VERSION ""

NS_ :

BS_:

BU_:  Inverter  Battery  Charger  Host

BO_ 2626813958 BATT_diagnosticHrnsImpDleta_0_6: 8 Battery
 SG_ BATT_HrnsImpDelta_3_6 : 48|16@1- (0.001,0) [-32.768|32.767] "mV" Host
 SG_ BATT_HrnsImpDelta_2_6 : 32|16@1- (0.001,0) [-32.768|32.767] "mV" Host
 SG_ BATT_HrnsImpDelta_1_6 : 16|16@1- (0.001,0) [-32.768|32.767] "mV" Host
 SG_ BATT_HrnsImpDelta_0_6 : 0|16@1- (0.001,0) [-32.768|32.767] "mV" Host

BO_ 2626813959 BATT_diagnosticHrnsImpDleta_0_7: 8 Battery
 SG_ BATT_HrnsImpDelta_3_7 : 48|16@1- (0.001,0) [-32.768|32.767] "mV" Host
 SG_ BATT_HrnsImpDelta_2_7 : 32|16@1- (0.001,0) [-32.768|32.767] "mV" Host
 SG_ BATT_HrnsImpDelta_1_7 : 16|16@1- (0.001,0) [-32.768|32.767] "mV" Host
 SG_ BATT_HrnsImpDelta_0_7 : 0|16@1- (0.001,0) [-32.768|32.767] "mV" Host

BO_ 2626813960 BATT_diagnosticHrnsImpDleta_0_8: 8 Battery
 SG_ BATT_HrnsImpDelta_3_8 : 48|16@1- (0.001,0) [-32.768|32.767] "mV" Host
 SG_ BATT_HrnsImpDelta_2_8 : 32|16@1- (0.001,0) [-32.768|32.767] "mV" Host
 SG_ BATT_HrnsImpDelta_1_8 : 16|16@1- (0.001,0) [-32.768|32.767] "mV" Host
 SG_ BATT_HrnsImpDelta_0_8 : 0|16@1- (0.001,0) [-32.768|32.767] "mV" Host

BO_ 2626813961 BATT_diagnosticHrnsImpDleta_0_9: 8 Battery
 SG_ BATT_HrnsImpDelta_3_9 : 48|16@1- (0.001,0) [-32.768|32.767] "mV" Host
 SG_ BATT_HrnsImpDelta_2_9 : 32|16@1- (0.001,0) [-32.768|32.767] "mV" Host
 SG_ BATT_HrnsImpDelta_1_9 : 16|16@1- (0.001,0) [-32.768|32.767] "mV" Host
 SG_ BATT_HrnsImpDelta_0_9 : 0|16@1- (0.001,0) [-32.768|32.767] "mV" Host

BO_ 2626813962 BATT_diagnosticHrnsImpDleta_0_10: 8 Battery
 SG_ BATT_HrnsImpDelta_3_10 : 48|16@1- (0.001,0) [-32.768|32.767] "mV" Host
 SG_ BATT_HrnsImpDelta_2_10 : 32|16@1- (0.001,0) [-32.768|32.767] "mV" Host
 SG_ BATT_HrnsImpDelta_1_10 : 16|16@1- (0.001,0) [-32.768|32.767] "mV" Host
 SG_ BATT_HrnsImpDelta_0_10 : 0|16@1- (0.001,0) [-32.768|32.767] "mV" Host

BO_ 2626813963 BATT_diagnosticHrnsImpDleta_0_11: 8 Battery
 SG_ BATT_HrnsImpDelta_3_11 : 48|16@1- (0.001,0) [-32.768|32.767] "mV" Host
 SG_ BATT_HrnsImpDelta_2_11 : 32|16@1- (0.001,0) [-32.768|32.767] "mV" Host
 SG_ BATT_HrnsImpDelta_1_11 : 16|16@1- (0.001,0) [-32.768|32.767] "mV" Host
 SG_ BATT_HrnsImpDelta_0_11 : 0|16@1- (0.001,0) [-32.768|32.767] "mV" Host

BO_ 2626818048 BATT_diagnosticHrnsImpDleta_1_0: 8 Battery
 SG_ BATT_HrnsImpDelta_7_0 : 48|16@1- (0.001,0) [-32.768|32.767] "mV" Host
 SG_ BATT_HrnsImpDelta_6_0 : 32|16@1- (0.001,0) [-32.768|32.767] "mV" Host
 SG_ BATT_HrnsImpDelta_5_0 : 16|16@1- (0.001,0) [-32.768|32.767] "mV" Host
 SG_ BATT_HrnsImpDelta_4_0 : 0|16@1- (0.001,0) [-32.768|32.767] "mV" Host

BO_ 2626818049 BATT_diagnosticHrnsImpDleta_1_1: 8 Battery
 SG_ BATT_HrnsImpDelta_7_1 : 48|16@1- (0.001,0) [-32.768|32.767] "mV" Host
 SG_ BATT_HrnsImpDelta_6_1 : 32|16@1- (0.001,0) [-32.768|32.767] "mV" Host
 SG_ BATT_HrnsImpDelta_5_1 : 16|16@1- (0.001,0) [-32.768|32.767] "mV" Host
 SG_ BATT_HrnsImpDelta_4_1 : 0|16@1- (0.001,0) [-32.768|32.767] "mV" Host

BO_ 2626818050 BATT_diagnosticHrnsImpDleta_1_2: 8 Battery
 SG_ BATT_HrnsImpDelta_7_2 : 48|16@1- (0.001,0) [-32.768|32.767] "mV" Host
 SG_ BATT_HrnsImpDelta_6_2 : 32|16@1- (0.001,0) [-32.768|32.767] "mV" Host
 SG_ BATT_HrnsImpDelta_5_2 : 16|16@1- (0.001,0) [-32.768|32.767] "mV" Host
 SG_ BATT_HrnsImpDelta_4_2 : 0|16@1- (0.001,0) [-32.768|32.767] "mV" Host

BO_ 2626818051 BATT_diagnosticHrnsImpDleta_1_3: 8 Battery
 SG_ BATT_HrnsImpDelta_7_3 : 48|16@1- (0.001,0) [-32.768|32.767] "mV" Host
 SG_ BATT_HrnsImpDelta_6_3 : 32|16@1- (0.001,0) [-32.768|32.767] "mV" Host
 SG_ BATT_HrnsImpDelta_5_3 : 16|16@1- (0.001,0) [-32.768|32.767] "mV" Host
 SG_ BATT_HrnsImpDelta_4_3 : 0|16@1- (0.001,0) [-32.768|32.767] "mV" Host

BO_ 2626818052 BATT_diagnosticHrnsImpDleta_1_4: 8 Battery
 SG_ BATT_HrnsImpDelta_7_4 : 48|16@1- (0.001,0) [-32.768|32.767] "mV" Host
 SG_ BATT_HrnsImpDelta_6_4 : 32|16@1- (0.001,0) [-32.768|32.767] "mV" Host
 SG_ BATT_HrnsImpDelta_5_4 : 16|16@1- (0.001,0) [-32.768|32.767] "mV" Host
 SG_ BATT_HrnsImpDelta_4_4 : 0|16@1- (0.001,0) [-32.768|32.767] "mV" Host

BO_ 2626818053 BATT_diagnosticHrnsImpDleta_1_5: 8 Battery
 SG_ BATT_HrnsImpDelta_7_5 : 48|16@1- (0.001,0) [-32.768|32.767] "mV" Host
 SG_ BATT_HrnsImpDelta_6_5 : 32|16@1- (0.001,0) [-32.768|32.767] "mV" Host
 SG_ BATT_HrnsImpDelta_5_5 : 16|16@1- (0.001,0) [-32.768|32.767] "mV" Host
 SG_ BATT_HrnsImpDelta_4_5 : 0|16@1- (0.001,0) [-32.768|32.767] "mV" Host

BO_ 2626818054 BATT_diagnosticHrnsImpDleta_1_6: 8 Battery
 SG_ BATT_HrnsImpDelta_7_6 : 48|16@1- (0.001,0) [-32.768|32.767] "mV" Host
 SG_ BATT_HrnsImpDelta_6_6 : 32|16@1- (0.001,0) [-32.768|32.767] "mV" Host
 SG_ BATT_HrnsImpDelta_5_6 : 16|16@1- (0.001,0) [-32.768|32.767] "mV" Host
 SG_ BATT_HrnsImpDelta_4_6 : 0|16@1- (0.001,0) [-32.768|32.767] "mV" Host

BO_ 2626818055 BATT_diagnosticHrnsImpDleta_1_7: 8 Battery
 SG_ BATT_HrnsImpDelta_7_7 : 48|16@1- (0.001,0) [-32.768|32.767] "mV" Host
 SG_ BATT_HrnsImpDelta_6_7 : 32|16@1- (0.001,0) [-32.768|32.767] "mV" Host
 SG_ BATT_HrnsImpDelta_5_7 : 16|16@1- (0.001,0) [-32.768|32.767] "mV" Host
 SG_ BATT_HrnsImpDelta_4_7 : 0|16@1- (0.001,0) [-32.768|32.767] "mV" Host

BO_ 2626818056 BATT_diagnosticHrnsImpDleta_1_8: 8 Battery
 SG_ BATT_HrnsImpDelta_7_8 : 48|16@1- (0.001,0) [-32.768|32.767] "mV" Host
 SG_ BATT_HrnsImpDelta_6_8 : 32|16@1- (0.001,0) [-32.768|32.767] "mV" Host
 SG_ BATT_HrnsImpDelta_5_8 : 16|16@1- (0.001,0) [-32.768|32.767] "mV" Host
 SG_ BATT_HrnsImpDelta_4_8 : 0|16@1- (0.001,0) [-32.768|32.767] "mV" Host

BO_ 2626818057 BATT_diagnosticHrnsImpDleta_1_9: 8 Battery
 SG_ BATT_HrnsImpDelta_7_9 : 48|16@1- (0.001,0) [-32.768|32.767] "mV" Host
 SG_ BATT_HrnsImpDelta_6_9 : 32|16@1- (0.001,0) [-32.768|32.767] "mV" Host
 SG_ BATT_HrnsImpDelta_5_9 : 16|16@1- (0.001,0) [-32.768|32.767] "mV" Host
 SG_ BATT_HrnsImpDelta_4_9 : 0|16@1- (0.001,0) [-32.768|32.767] "mV" Host

BO_ 2626818058 BATT_diagnosticHrnsImpDleta_1_10: 8 Battery
 SG_ BATT_HrnsImpDelta_7_10 : 48|16@1- (0.001,0) [-32.768|32.767] "mV" Host
 SG_ BATT_HrnsImpDelta_6_10 : 32|16@1- (0.001,0) [-32.768|32.767] "mV" Host
 SG_ BATT_HrnsImpDelta_5_10 : 16|16@1- (0.001,0) [-32.768|32.767] "mV" Host
 SG_ BATT_HrnsImpDelta_4_10 : 0|16@1- (0.001,0) [-32.768|32.767] "mV" Host

BO_ 2626818059 BATT_diagnosticHrnsImpDleta_1_11: 8 Battery
 SG_ BATT_HrnsImpDelta_7_11 : 48|16@1- (0.001,0) [-32.768|32.767] "mV" Host
 SG_ BATT_HrnsImpDelta_6_11 : 32|16@1- (0.001,0) [-32.768|32.767] "mV" Host
 SG_ BATT_HrnsImpDelta_5_11 : 16|16@1- (0.001,0) [-32.768|32.767] "mV" Host
 SG_ BATT_HrnsImpDelta_4_11 : 0|16@1- (0.001,0) [-32.768|32.767] "mV" Host

BO_ 2626822144 BATT_diagnosticHrnsImpDleta_2_0: 8 Battery
 SG_ BATT_HrnsImpDelta_11_0 : 48|16@1- (0.001,0) [-32.768|32.767] "mV" Host
 SG_ BATT_HrnsImpDelta_10_0 : 32|16@1- (0.001,0) [-32.768|32.767] "mV" Host
 SG_ BATT_HrnsImpDelta_9_0 : 16|16@1- (0.001,0) [-32.768|32.767] "mV" Host
 SG_ BATT_HrnsImpDelta_8_0 : 0|16@1- (0.001,0) [-32.768|32.767] "mV" Host

BO_ 2626822145 BATT_diagnosticHrnsImpDleta_2_1: 8 Battery
 SG_ BATT_HrnsImpDelta_11_1 : 48|16@1- (0.001,0) [-32.768|32.767] "mV" Host
 SG_ BATT_HrnsImpDelta_10_1 : 32|16@1- (0.001,0) [-32.768|32.767] "mV" Host
 SG_ BATT_HrnsImpDelta_9_1 : 16|16@1- (0.001,0) [-32.768|32.767] "mV" Host
 SG_ BATT_HrnsImpDelta_8_1 : 0|16@1- (0.001,0) [-32.768|32.767] "mV" Host

BO_ 2626822146 BATT_diagnosticHrnsImpDleta_2_2: 8 Battery
 SG_ BATT_HrnsImpDelta_11_2 : 48|16@1- (0.001,0) [-32.768|32.767] "mV" Host
 SG_ BATT_HrnsImpDelta_10_2 : 32|16@1- (0.001,0) [-32.768|32.767] "mV" Host
 SG_ BATT_HrnsImpDelta_9_2 : 16|16@1- (0.001,0) [-32.768|32.767] "mV" Host
 SG_ BATT_HrnsImpDelta_8_2 : 0|16@1- (0.001,0) [-32.768|32.767] "mV" Host

BO_ 2626822147 BATT_diagnosticHrnsImpDleta_2_3: 8 Battery
 SG_ BATT_HrnsImpDelta_11_3 : 48|16@1- (0.001,0) [-32.768|32.767] "mV" Host
 SG_ BATT_HrnsImpDelta_10_3 : 32|16@1- (0.001,0) [-32.768|32.767] "mV" Host
 SG_ BATT_HrnsImpDelta_9_3 : 16|16@1- (0.001,0) [-32.768|32.767] "mV" Host
 SG_ BATT_HrnsImpDelta_8_3 : 0|16@1- (0.001,0) [-32.768|32.767] "mV" Host

BO_ 2626822148 BATT_diagnosticHrnsImpDleta_2_4: 8 Battery
 SG_ BATT_HrnsImpDelta_11_4 : 48|16@1- (0.001,0) [-32.768|32.767] "mV" Host
 SG_ BATT_HrnsImpDelta_10_4 : 32|16@1- (0.001,0) [-32.768|32.767] "mV" Host
 SG_ BATT_HrnsImpDelta_9_4 : 16|16@1- (0.001,0) [-32.768|32.767] "mV" Host
 SG_ BATT_HrnsImpDelta_8_4 : 0|16@1- (0.001,0) [-32.768|32.767] "mV" Host

BO_ 2626822149 BATT_diagnosticHrnsImpDleta_2_5: 8 Battery
 SG_ BATT_HrnsImpDelta_11_5 : 48|16@1- (0.001,0) [-32.768|32.767] "mV" Host
 SG_ BATT_HrnsImpDelta_10_5 : 32|16@1- (0.001,0) [-32.768|32.767] "mV" Host
 SG_ BATT_HrnsImpDelta_9_5 : 16|16@1- (0.001,0) [-32.768|32.767] "mV" Host
 SG_ BATT_HrnsImpDelta_8_5 : 0|16@1- (0.001,0) [-32.768|32.767] "mV" Host

BO_ 2626822150 BATT_diagnosticHrnsImpDleta_2_6: 8 Battery
 SG_ BATT_HrnsImpDelta_11_6 : 48|16@1- (0.001,0) [-32.768|32.767] "mV" Host
 SG_ BATT_HrnsImpDelta_10_6 : 32|16@1- (0.001,0) [-32.768|32.767] "mV" Host
 SG_ BATT_HrnsImpDelta_9_6 : 16|16@1- (0.001,0) [-32.768|32.767] "mV" Host
 SG_ BATT_HrnsImpDelta_8_6 : 0|16@1- (0.001,0) [-32.768|32.767] "mV" Host

BO_ 2626822151 BATT_diagnosticHrnsImpDleta_2_7: 8 Battery
 SG_ BATT_HrnsImpDelta_11_7 : 48|16@1- (0.001,0) [-32.768|32.767] "mV" Host
 SG_ BATT_HrnsImpDelta_10_7 : 32|16@1- (0.001,0) [-32.768|32.767] "mV" Host
 SG_ BATT_HrnsImpDelta_9_7 : 16|16@1- (0.001,0) [-32.768|32.767] "mV" Host
 SG_ BATT_HrnsImpDelta_8_7 : 0|16@1- (0.001,0) [-32.768|32.767] "mV" Host

BO_ 2626822152 BATT_diagnosticHrnsImpDleta_2_8: 8 Battery
 SG_ BATT_HrnsImpDelta_11_8 : 48|16@1- (0.001,0) [-32.768|32.767] "mV" Host
 SG_ BATT_HrnsImpDelta_10_8 : 32|16@1- (0.001,0) [-32.768|32.767] "mV" Host
 SG_ BATT_HrnsImpDelta_9_8 : 16|16@1- (0.001,0) [-32.768|32.767] "mV" Host
 SG_ BATT_HrnsImpDelta_8_8 : 0|16@1- (0.001,0) [-32.768|32.767] "mV" Host

BO_ 2626822153 BATT_diagnosticHrnsImpDleta_2_9: 8 Battery
 SG_ BATT_HrnsImpDelta_11_9 : 48|16@1- (0.001,0) [-32.768|32.767] "mV" Host
 SG_ BATT_HrnsImpDelta_10_9 : 32|16@1- (0.001,0) [-32.768|32.767] "mV" Host
 SG_ BATT_HrnsImpDelta_9_9 : 16|16@1- (0.001,0) [-32.768|32.767] "mV" Host
 SG_ BATT_HrnsImpDelta_8_9 : 0|16@1- (0.001,0) [-32.768|32.767] "mV" Host

BO_ 2626822154 BATT_diagnosticHrnsImpDleta_2_10: 8 Battery
 SG_ BATT_HrnsImpDelta_11_10 : 48|16@1- (0.001,0) [-32.768|32.767] "mV" Host
 SG_ BATT_HrnsImpDelta_10_10 : 32|16@1- (0.001,0) [-32.768|32.767] "mV" Host
 SG_ BATT_HrnsImpDelta_9_10 : 16|16@1- (0.001,0) [-32.768|32.767] "mV" Host
 SG_ BATT_HrnsImpDelta_8_10 : 0|16@1- (0.001,0) [-32.768|32.767] "mV" Host

BO_ 2626822155 BATT_diagnosticHrnsImpDleta_2_11: 8 Battery
 SG_ BATT_HrnsImpDelta_11_11 : 48|16@1- (0.001,0) [-32.768|32.767] "mV" Host
 SG_ BATT_HrnsImpDelta_10_11 : 32|16@1- (0.001,0) [-32.768|32.767] "mV" Host
 SG_ BATT_HrnsImpDelta_9_11 : 16|16@1- (0.001,0) [-32.768|32.767] "mV" Host
 SG_ BATT_HrnsImpDelta_8_11 : 0|16@1- (0.001,0) [-32.768|32.767] "mV" Host

BO_ 2626826240 BATT_diagnosticHrnsImpDleta_3_0: 6 Battery
 SG_ BATT_HrnsImpDelta_14_0 : 32|16@1- (0.001,0) [-32.768|32.767] "mV" Host
 SG_ BATT_HrnsImpDelta_13_0 : 16|16@1- (0.001,0) [-32.768|32.767] "mV" Host
 SG_ BATT_HrnsImpDelta_12_0 : 0|16@1- (0.001,0) [-32.768|32.767] "mV" Host

BO_ 2626826241 BATT_diagnosticHrnsImpDleta_3_1: 6 Battery
 SG_ BATT_HrnsImpDelta_14_1 : 32|16@1- (0.001,0) [-32.768|32.767] "mV" Host
 SG_ BATT_HrnsImpDelta_13_1 : 16|16@1- (0.001,0) [-32.768|32.767] "mV" Host
 SG_ BATT_HrnsImpDelta_12_1 : 0|16@1- (0.001,0) [-32.768|32.767] "mV" Host

BO_ 2626826242 BATT_diagnosticHrnsImpDleta_3_2: 6 Battery
 SG_ BATT_HrnsImpDelta_14_2 : 32|16@1- (0.001,0) [-32.768|32.767] "mV" Host
 SG_ BATT_HrnsImpDelta_13_2 : 16|16@1- (0.001,0) [-32.768|32.767] "mV" Host
 SG_ BATT_HrnsImpDelta_12_2 : 0|16@1- (0.001,0) [-32.768|32.767] "mV" Host

BO_ 2626826243 BATT_diagnosticHrnsImpDleta_3_3: 6 Battery
 SG_ BATT_HrnsImpDelta_14_3 : 32|16@1- (0.001,0) [-32.768|32.767] "mV" Host
 SG_ BATT_HrnsImpDelta_13_3 : 16|16@1- (0.001,0) [-32.768|32.767] "mV" Host
 SG_ BATT_HrnsImpDelta_12_3 : 0|16@1- (0.001,0) [-32.768|32.767] "mV" Host

BO_ 2626826244 BATT_diagnosticHrnsImpDleta_3_4: 6 Battery
 SG_ BATT_HrnsImpDelta_14_4 : 32|16@1- (0.001,0) [-32.768|32.767] "mV" Host
 SG_ BATT_HrnsImpDelta_13_4 : 16|16@1- (0.001,0) [-32.768|32.767] "mV" Host
 SG_ BATT_HrnsImpDelta_12_4 : 0|16@1- (0.001,0) [-32.768|32.767] "mV" Host

BO_ 2626826245 BATT_diagnosticHrnsImpDleta_3_5: 6 Battery
 SG_ BATT_HrnsImpDelta_14_5 : 32|16@1- (0.001,0) [-32.768|32.767] "mV" Host
 SG_ BATT_HrnsImpDelta_13_5 : 16|16@1- (0.001,0) [-32.768|32.767] "mV" Host
 SG_ BATT_HrnsImpDelta_12_5 : 0|16@1- (0.001,0) [-32.768|32.767] "mV" Host

BO_ 2626826246 BATT_diagnosticHrnsImpDleta_3_6: 6 Battery
 SG_ BATT_HrnsImpDelta_14_6 : 32|16@1- (0.001,0) [-32.768|32.767] "mV" Host
 SG_ BATT_HrnsImpDelta_13_6 : 16|16@1- (0.001,0) [-32.768|32.767] "mV" Host
 SG_ BATT_HrnsImpDelta_12_6 : 0|16@1- (0.001,0) [-32.768|32.767] "mV" Host

BO_ 2626826247 BATT_diagnosticHrnsImpDleta_3_7: 6 Battery
 SG_ BATT_HrnsImpDelta_14_7 : 32|16@1- (0.001,0) [-32.768|32.767] "mV" Host
 SG_ BATT_HrnsImpDelta_13_7 : 16|16@1- (0.001,0) [-32.768|32.767] "mV" Host
 SG_ BATT_HrnsImpDelta_12_7 : 0|16@1- (0.001,0) [-32.768|32.767] "mV" Host

BO_ 2626826248 BATT_diagnosticHrnsImpDleta_3_8: 6 Battery
 SG_ BATT_HrnsImpDelta_14_8 : 32|16@1- (0.001,0) [-32.768|32.767] "mV" Host
 SG_ BATT_HrnsImpDelta_13_8 : 16|16@1- (0.001,0) [-32.768|32.767] "mV" Host
 SG_ BATT_HrnsImpDelta_12_8 : 0|16@1- (0.001,0) [-32.768|32.767] "mV" Host

BO_ 2626826249 BATT_diagnosticHrnsImpDleta_3_9: 6 Battery
 SG_ BATT_HrnsImpDelta_14_9 : 32|16@1- (0.001,0) [-32.768|32.767] "mV" Host
 SG_ BATT_HrnsImpDelta_13_9 : 16|16@1- (0.001,0) [-32.768|32.767] "mV" Host
 SG_ BATT_HrnsImpDelta_12_9 : 0|16@1- (0.001,0) [-32.768|32.767] "mV" Host

BO_ 2626826250 BATT_diagnosticHrnsImpDleta_3_10: 6 Battery
 SG_ BATT_HrnsImpDelta_14_10 : 32|16@1- (0.001,0) [-32.768|32.767] "mV" Host
 SG_ BATT_HrnsImpDelta_13_10 : 16|16@1- (0.001,0) [-32.768|32.767] "mV" Host
 SG_ BATT_HrnsImpDelta_12_10 : 0|16@1- (0.001,0) [-32.768|32.767] "mV" Host

BO_ 2626826251 BATT_diagnosticHrnsImpDleta_3_11: 6 Battery
 SG_ BATT_HrnsImpDelta_14_11 : 32|16@1- (0.001,0) [-32.768|32.767] "mV" Host
 SG_ BATT_HrnsImpDelta_13_11 : 16|16@1- (0.001,0) [-32.768|32.767] "mV" Host
 SG_ BATT_HrnsImpDelta_12_11 : 0|16@1- (0.001,0) [-32.768|32.767] "mV" Host

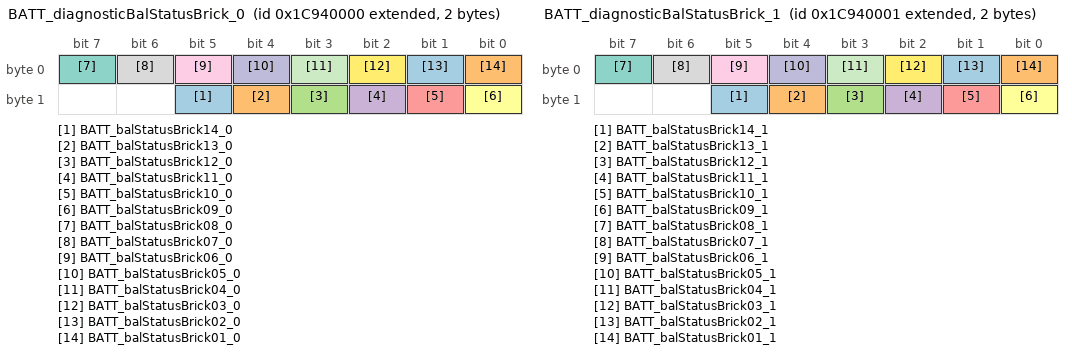
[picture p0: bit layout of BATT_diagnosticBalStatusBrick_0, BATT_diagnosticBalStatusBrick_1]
BO_ 2626945024 BATT_diagnosticBalStatusBrick_0: 2 Battery
 SG_ BATT_balStatusBrick14_0 : 13|1@1+ (1,0) [0|1] "" Host
 SG_ BATT_balStatusBrick13_0 : 12|1@1+ (1,0) [0|1] "" Host
 SG_ BATT_balStatusBrick12_0 : 11|1@1+ (1,0) [0|1] "" Host
 SG_ BATT_balStatusBrick11_0 : 10|1@1+ (1,0) [0|1] "" Host
 SG_ BATT_balStatusBrick10_0 : 9|1@1+ (1,0) [0|1] "" Host
 SG_ BATT_balStatusBrick09_0 : 8|1@1+ (1,0) [0|1] "" Host
 SG_ BATT_balStatusBrick08_0 : 7|1@1+ (1,0) [0|1] "" Host
 SG_ BATT_balStatusBrick07_0 : 6|1@1+ (1,0) [0|1] "" Host
 SG_ BATT_balStatusBrick06_0 : 5|1@1+ (1,0) [0|1] "" Host
 SG_ BATT_balStatusBrick05_0 : 4|1@1+ (1,0) [0|1] "" Host
 SG_ BATT_balStatusBrick04_0 : 3|1@1+ (1,0) [0|1] "" Host
 SG_ BATT_balStatusBrick03_0 : 2|1@1+ (1,0) [0|1] "" Host
 SG_ BATT_balStatusBrick02_0 : 1|1@1+ (1,0) [0|1] "" Host
 SG_ BATT_balStatusBrick01_0 : 0|1@1+ (1,0) [0|1] "" Host

BO_ 2626945025 BATT_diagnosticBalStatusBrick_1: 2 Battery
 SG_ BATT_balStatusBrick14_1 : 13|1@1+ (1,0) [0|1] "" Host
 SG_ BATT_balStatusBrick13_1 : 12|1@1+ (1,0) [0|1] "" Host
 SG_ BATT_balStatusBrick12_1 : 11|1@1+ (1,0) [0|1] "" Host
 SG_ BATT_balStatusBrick11_1 : 10|1@1+ (1,0) [0|1] "" Host
 SG_ BATT_balStatusBrick10_1 : 9|1@1+ (1,0) [0|1] "" Host
 SG_ BATT_balStatusBrick09_1 : 8|1@1+ (1,0) [0|1] "" Host
 SG_ BATT_balStatusBrick08_1 : 7|1@1+ (1,0) [0|1] "" Host
 SG_ BATT_balStatusBrick07_1 : 6|1@1+ (1,0) [0|1] "" Host
 SG_ BATT_balStatusBrick06_1 : 5|1@1+ (1,0) [0|1] "" Host
 SG_ BATT_balStatusBrick05_1 : 4|1@1+ (1,0) [0|1] "" Host
 SG_ BATT_balStatusBrick04_1 : 3|1@1+ (1,0) [0|1] "" Host
 SG_ BATT_balStatusBrick03_1 : 2|1@1+ (1,0) [0|1] "" Host
 SG_ BATT_balStatusBrick02_1 : 1|1@1+ (1,0) [0|1] "" Host
 SG_ BATT_balStatusBrick01_1 : 0|1@1+ (1,0) [0|1] "" Host

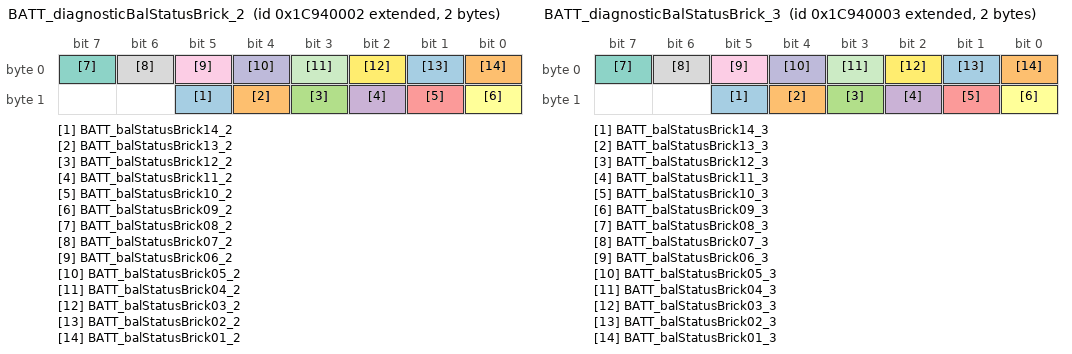
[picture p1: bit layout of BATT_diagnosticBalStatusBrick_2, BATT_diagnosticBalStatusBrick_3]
BO_ 2626945026 BATT_diagnosticBalStatusBrick_2: 2 Battery
 SG_ BATT_balStatusBrick14_2 : 13|1@1+ (1,0) [0|1] "" Host
 SG_ BATT_balStatusBrick13_2 : 12|1@1+ (1,0) [0|1] "" Host
 SG_ BATT_balStatusBrick12_2 : 11|1@1+ (1,0) [0|1] "" Host
 SG_ BATT_balStatusBrick11_2 : 10|1@1+ (1,0) [0|1] "" Host
 SG_ BATT_balStatusBrick10_2 : 9|1@1+ (1,0) [0|1] "" Host
 SG_ BATT_balStatusBrick09_2 : 8|1@1+ (1,0) [0|1] "" Host
 SG_ BATT_balStatusBrick08_2 : 7|1@1+ (1,0) [0|1] "" Host
 SG_ BATT_balStatusBrick07_2 : 6|1@1+ (1,0) [0|1] "" Host
 SG_ BATT_balStatusBrick06_2 : 5|1@1+ (1,0) [0|1] "" Host
 SG_ BATT_balStatusBrick05_2 : 4|1@1+ (1,0) [0|1] "" Host
 SG_ BATT_balStatusBrick04_2 : 3|1@1+ (1,0) [0|1] "" Host
 SG_ BATT_balStatusBrick03_2 : 2|1@1+ (1,0) [0|1] "" Host
 SG_ BATT_balStatusBrick02_2 : 1|1@1+ (1,0) [0|1] "" Host
 SG_ BATT_balStatusBrick01_2 : 0|1@1+ (1,0) [0|1] "" Host

BO_ 2626945027 BATT_diagnosticBalStatusBrick_3: 2 Battery
 SG_ BATT_balStatusBrick14_3 : 13|1@1+ (1,0) [0|1] "" Host
 SG_ BATT_balStatusBrick13_3 : 12|1@1+ (1,0) [0|1] "" Host
 SG_ BATT_balStatusBrick12_3 : 11|1@1+ (1,0) [0|1] "" Host
 SG_ BATT_balStatusBrick11_3 : 10|1@1+ (1,0) [0|1] "" Host
 SG_ BATT_balStatusBrick10_3 : 9|1@1+ (1,0) [0|1] "" Host
 SG_ BATT_balStatusBrick09_3 : 8|1@1+ (1,0) [0|1] "" Host
 SG_ BATT_balStatusBrick08_3 : 7|1@1+ (1,0) [0|1] "" Host
 SG_ BATT_balStatusBrick07_3 : 6|1@1+ (1,0) [0|1] "" Host
 SG_ BATT_balStatusBrick06_3 : 5|1@1+ (1,0) [0|1] "" Host
 SG_ BATT_balStatusBrick05_3 : 4|1@1+ (1,0) [0|1] "" Host
 SG_ BATT_balStatusBrick04_3 : 3|1@1+ (1,0) [0|1] "" Host
 SG_ BATT_balStatusBrick03_3 : 2|1@1+ (1,0) [0|1] "" Host
 SG_ BATT_balStatusBrick02_3 : 1|1@1+ (1,0) [0|1] "" Host
 SG_ BATT_balStatusBrick01_3 : 0|1@1+ (1,0) [0|1] "" Host

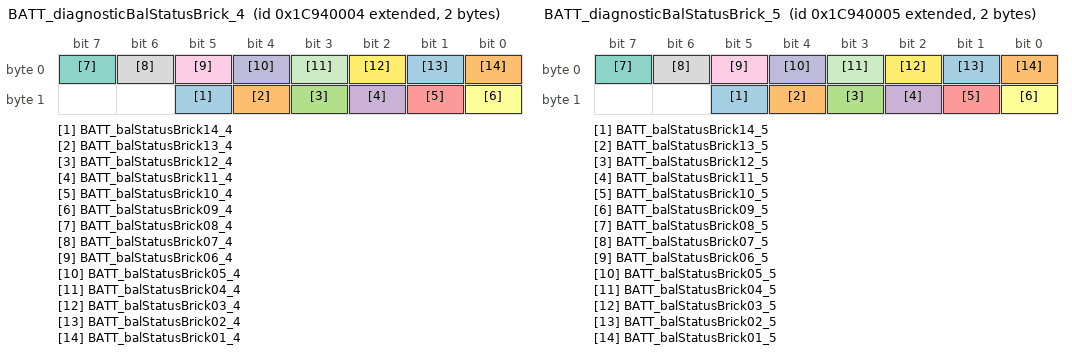
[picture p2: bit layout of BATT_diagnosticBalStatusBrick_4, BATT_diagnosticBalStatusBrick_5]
BO_ 2626945028 BATT_diagnosticBalStatusBrick_4: 2 Battery
 SG_ BATT_balStatusBrick14_4 : 13|1@1+ (1,0) [0|1] "" Host
 SG_ BATT_balStatusBrick13_4 : 12|1@1+ (1,0) [0|1] "" Host
 SG_ BATT_balStatusBrick12_4 : 11|1@1+ (1,0) [0|1] "" Host
 SG_ BATT_balStatusBrick11_4 : 10|1@1+ (1,0) [0|1] "" Host
 SG_ BATT_balStatusBrick10_4 : 9|1@1+ (1,0) [0|1] "" Host
 SG_ BATT_balStatusBrick09_4 : 8|1@1+ (1,0) [0|1] "" Host
 SG_ BATT_balStatusBrick08_4 : 7|1@1+ (1,0) [0|1] "" Host
 SG_ BATT_balStatusBrick07_4 : 6|1@1+ (1,0) [0|1] "" Host
 SG_ BATT_balStatusBrick06_4 : 5|1@1+ (1,0) [0|1] "" Host
 SG_ BATT_balStatusBrick05_4 : 4|1@1+ (1,0) [0|1] "" Host
 SG_ BATT_balStatusBrick04_4 : 3|1@1+ (1,0) [0|1] "" Host
 SG_ BATT_balStatusBrick03_4 : 2|1@1+ (1,0) [0|1] "" Host
 SG_ BATT_balStatusBrick02_4 : 1|1@1+ (1,0) [0|1] "" Host
 SG_ BATT_balStatusBrick01_4 : 0|1@1+ (1,0) [0|1] "" Host

BO_ 2626945029 BATT_diagnosticBalStatusBrick_5: 2 Battery
 SG_ BATT_balStatusBrick14_5 : 13|1@1+ (1,0) [0|1] "" Host
 SG_ BATT_balStatusBrick13_5 : 12|1@1+ (1,0) [0|1] "" Host
 SG_ BATT_balStatusBrick12_5 : 11|1@1+ (1,0) [0|1] "" Host
 SG_ BATT_balStatusBrick11_5 : 10|1@1+ (1,0) [0|1] "" Host
 SG_ BATT_balStatusBrick10_5 : 9|1@1+ (1,0) [0|1] "" Host
 SG_ BATT_balStatusBrick09_5 : 8|1@1+ (1,0) [0|1] "" Host
 SG_ BATT_balStatusBrick08_5 : 7|1@1+ (1,0) [0|1] "" Host
 SG_ BATT_balStatusBrick07_5 : 6|1@1+ (1,0) [0|1] "" Host
 SG_ BATT_balStatusBrick06_5 : 5|1@1+ (1,0) [0|1] "" Host
 SG_ BATT_balStatusBrick05_5 : 4|1@1+ (1,0) [0|1] "" Host
 SG_ BATT_balStatusBrick04_5 : 3|1@1+ (1,0) [0|1] "" Host
 SG_ BATT_balStatusBrick03_5 : 2|1@1+ (1,0) [0|1] "" Host
 SG_ BATT_balStatusBrick02_5 : 1|1@1+ (1,0) [0|1] "" Host
 SG_ BATT_balStatusBrick01_5 : 0|1@1+ (1,0) [0|1] "" Host

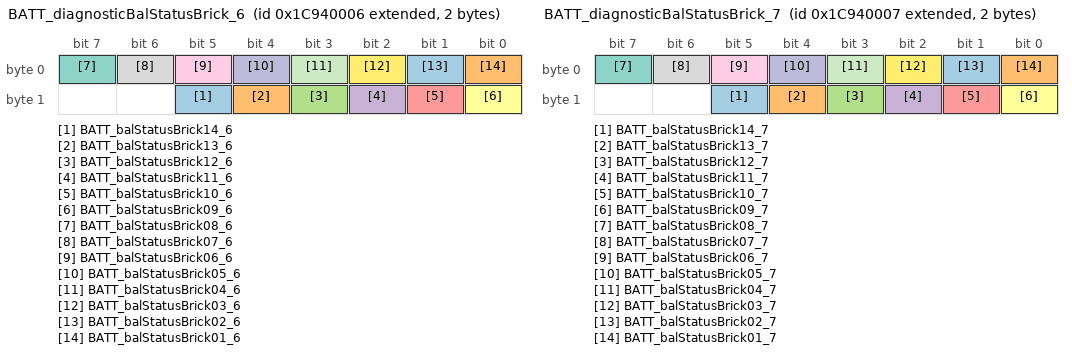
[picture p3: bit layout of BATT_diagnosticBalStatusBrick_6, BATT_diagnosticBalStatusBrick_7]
BO_ 2626945030 BATT_diagnosticBalStatusBrick_6: 2 Battery
 SG_ BATT_balStatusBrick14_6 : 13|1@1+ (1,0) [0|1] "" Host
 SG_ BATT_balStatusBrick13_6 : 12|1@1+ (1,0) [0|1] "" Host
 SG_ BATT_balStatusBrick12_6 : 11|1@1+ (1,0) [0|1] "" Host
 SG_ BATT_balStatusBrick11_6 : 10|1@1+ (1,0) [0|1] "" Host
 SG_ BATT_balStatusBrick10_6 : 9|1@1+ (1,0) [0|1] "" Host
 SG_ BATT_balStatusBrick09_6 : 8|1@1+ (1,0) [0|1] "" Host
 SG_ BATT_balStatusBrick08_6 : 7|1@1+ (1,0) [0|1] "" Host
 SG_ BATT_balStatusBrick07_6 : 6|1@1+ (1,0) [0|1] "" Host
 SG_ BATT_balStatusBrick06_6 : 5|1@1+ (1,0) [0|1] "" Host
 SG_ BATT_balStatusBrick05_6 : 4|1@1+ (1,0) [0|1] "" Host
 SG_ BATT_balStatusBrick04_6 : 3|1@1+ (1,0) [0|1] "" Host
 SG_ BATT_balStatusBrick03_6 : 2|1@1+ (1,0) [0|1] "" Host
 SG_ BATT_balStatusBrick02_6 : 1|1@1+ (1,0) [0|1] "" Host
 SG_ BATT_balStatusBrick01_6 : 0|1@1+ (1,0) [0|1] "" Host

BO_ 2626945031 BATT_diagnosticBalStatusBrick_7: 2 Battery
 SG_ BATT_balStatusBrick14_7 : 13|1@1+ (1,0) [0|1] "" Host
 SG_ BATT_balStatusBrick13_7 : 12|1@1+ (1,0) [0|1] "" Host
 SG_ BATT_balStatusBrick12_7 : 11|1@1+ (1,0) [0|1] "" Host
 SG_ BATT_balStatusBrick11_7 : 10|1@1+ (1,0) [0|1] "" Host
 SG_ BATT_balStatusBrick10_7 : 9|1@1+ (1,0) [0|1] "" Host
 SG_ BATT_balStatusBrick09_7 : 8|1@1+ (1,0) [0|1] "" Host
 SG_ BATT_balStatusBrick08_7 : 7|1@1+ (1,0) [0|1] "" Host
 SG_ BATT_balStatusBrick07_7 : 6|1@1+ (1,0) [0|1] "" Host
 SG_ BATT_balStatusBrick06_7 : 5|1@1+ (1,0) [0|1] "" Host
 SG_ BATT_balStatusBrick05_7 : 4|1@1+ (1,0) [0|1] "" Host
 SG_ BATT_balStatusBrick04_7 : 3|1@1+ (1,0) [0|1] "" Host
 SG_ BATT_balStatusBrick03_7 : 2|1@1+ (1,0) [0|1] "" Host
 SG_ BATT_balStatusBrick02_7 : 1|1@1+ (1,0) [0|1] "" Host
 SG_ BATT_balStatusBrick01_7 : 0|1@1+ (1,0) [0|1] "" Host

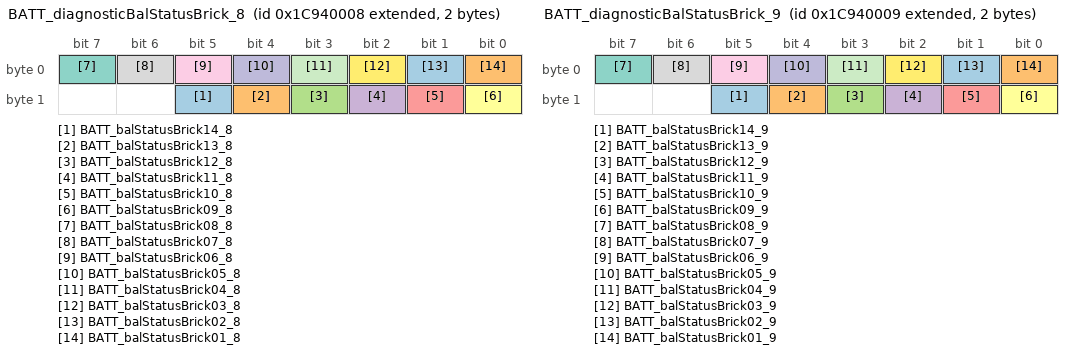
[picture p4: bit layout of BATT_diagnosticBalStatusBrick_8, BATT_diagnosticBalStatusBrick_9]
BO_ 2626945032 BATT_diagnosticBalStatusBrick_8: 2 Battery
 SG_ BATT_balStatusBrick14_8 : 13|1@1+ (1,0) [0|1] "" Host
 SG_ BATT_balStatusBrick13_8 : 12|1@1+ (1,0) [0|1] "" Host
 SG_ BATT_balStatusBrick12_8 : 11|1@1+ (1,0) [0|1] "" Host
 SG_ BATT_balStatusBrick11_8 : 10|1@1+ (1,0) [0|1] "" Host
 SG_ BATT_balStatusBrick10_8 : 9|1@1+ (1,0) [0|1] "" Host
 SG_ BATT_balStatusBrick09_8 : 8|1@1+ (1,0) [0|1] "" Host
 SG_ BATT_balStatusBrick08_8 : 7|1@1+ (1,0) [0|1] "" Host
 SG_ BATT_balStatusBrick07_8 : 6|1@1+ (1,0) [0|1] "" Host
 SG_ BATT_balStatusBrick06_8 : 5|1@1+ (1,0) [0|1] "" Host
 SG_ BATT_balStatusBrick05_8 : 4|1@1+ (1,0) [0|1] "" Host
 SG_ BATT_balStatusBrick04_8 : 3|1@1+ (1,0) [0|1] "" Host
 SG_ BATT_balStatusBrick03_8 : 2|1@1+ (1,0) [0|1] "" Host
 SG_ BATT_balStatusBrick02_8 : 1|1@1+ (1,0) [0|1] "" Host
 SG_ BATT_balStatusBrick01_8 : 0|1@1+ (1,0) [0|1] "" Host

BO_ 2626945033 BATT_diagnosticBalStatusBrick_9: 2 Battery
 SG_ BATT_balStatusBrick14_9 : 13|1@1+ (1,0) [0|1] "" Host
 SG_ BATT_balStatusBrick13_9 : 12|1@1+ (1,0) [0|1] "" Host
 SG_ BATT_balStatusBrick12_9 : 11|1@1+ (1,0) [0|1] "" Host
 SG_ BATT_balStatusBrick11_9 : 10|1@1+ (1,0) [0|1] "" Host
 SG_ BATT_balStatusBrick10_9 : 9|1@1+ (1,0) [0|1] "" Host
 SG_ BATT_balStatusBrick09_9 : 8|1@1+ (1,0) [0|1] "" Host
 SG_ BATT_balStatusBrick08_9 : 7|1@1+ (1,0) [0|1] "" Host
 SG_ BATT_balStatusBrick07_9 : 6|1@1+ (1,0) [0|1] "" Host
 SG_ BATT_balStatusBrick06_9 : 5|1@1+ (1,0) [0|1] "" Host
 SG_ BATT_balStatusBrick05_9 : 4|1@1+ (1,0) [0|1] "" Host
 SG_ BATT_balStatusBrick04_9 : 3|1@1+ (1,0) [0|1] "" Host
 SG_ BATT_balStatusBrick03_9 : 2|1@1+ (1,0) [0|1] "" Host
 SG_ BATT_balStatusBrick02_9 : 1|1@1+ (1,0) [0|1] "" Host
 SG_ BATT_balStatusBrick01_9 : 0|1@1+ (1,0) [0|1] "" Host

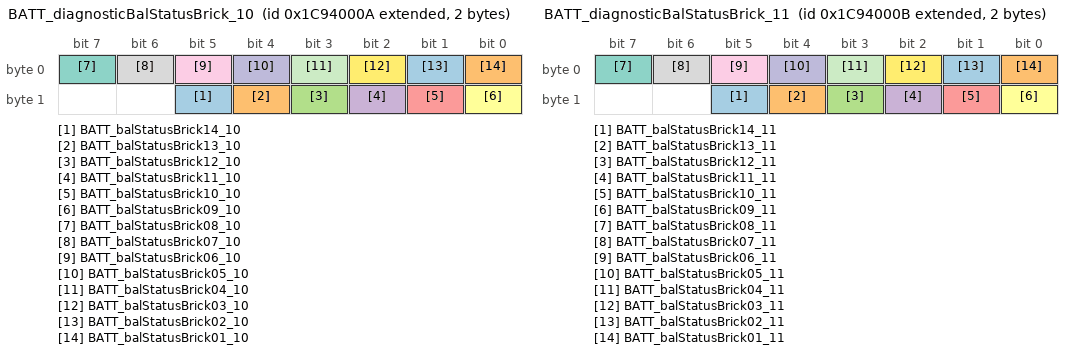
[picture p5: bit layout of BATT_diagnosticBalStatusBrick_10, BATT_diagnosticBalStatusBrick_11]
BO_ 2626945034 BATT_diagnosticBalStatusBrick_10: 2 Battery
 SG_ BATT_balStatusBrick14_10 : 13|1@1+ (1,0) [0|1] "" Host
 SG_ BATT_balStatusBrick13_10 : 12|1@1+ (1,0) [0|1] "" Host
 SG_ BATT_balStatusBrick12_10 : 11|1@1+ (1,0) [0|1] "" Host
 SG_ BATT_balStatusBrick11_10 : 10|1@1+ (1,0) [0|1] "" Host
 SG_ BATT_balStatusBrick10_10 : 9|1@1+ (1,0) [0|1] "" Host
 SG_ BATT_balStatusBrick09_10 : 8|1@1+ (1,0) [0|1] "" Host
 SG_ BATT_balStatusBrick08_10 : 7|1@1+ (1,0) [0|1] "" Host
 SG_ BATT_balStatusBrick07_10 : 6|1@1+ (1,0) [0|1] "" Host
 SG_ BATT_balStatusBrick06_10 : 5|1@1+ (1,0) [0|1] "" Host
 SG_ BATT_balStatusBrick05_10 : 4|1@1+ (1,0) [0|1] "" Host
 SG_ BATT_balStatusBrick04_10 : 3|1@1+ (1,0) [0|1] "" Host
 SG_ BATT_balStatusBrick03_10 : 2|1@1+ (1,0) [0|1] "" Host
 SG_ BATT_balStatusBrick02_10 : 1|1@1+ (1,0) [0|1] "" Host
 SG_ BATT_balStatusBrick01_10 : 0|1@1+ (1,0) [0|1] "" Host

BO_ 2626945035 BATT_diagnosticBalStatusBrick_11: 2 Battery
 SG_ BATT_balStatusBrick14_11 : 13|1@1+ (1,0) [0|1] "" Host
 SG_ BATT_balStatusBrick13_11 : 12|1@1+ (1,0) [0|1] "" Host
 SG_ BATT_balStatusBrick12_11 : 11|1@1+ (1,0) [0|1] "" Host
 SG_ BATT_balStatusBrick11_11 : 10|1@1+ (1,0) [0|1] "" Host
 SG_ BATT_balStatusBrick10_11 : 9|1@1+ (1,0) [0|1] "" Host
 SG_ BATT_balStatusBrick09_11 : 8|1@1+ (1,0) [0|1] "" Host
 SG_ BATT_balStatusBrick08_11 : 7|1@1+ (1,0) [0|1] "" Host
 SG_ BATT_balStatusBrick07_11 : 6|1@1+ (1,0) [0|1] "" Host
 SG_ BATT_balStatusBrick06_11 : 5|1@1+ (1,0) [0|1] "" Host
 SG_ BATT_balStatusBrick05_11 : 4|1@1+ (1,0) [0|1] "" Host
 SG_ BATT_balStatusBrick04_11 : 3|1@1+ (1,0) [0|1] "" Host
 SG_ BATT_balStatusBrick03_11 : 2|1@1+ (1,0) [0|1] "" Host
 SG_ BATT_balStatusBrick02_11 : 1|1@1+ (1,0) [0|1] "" Host
 SG_ BATT_balStatusBrick01_11 : 0|1@1+ (1,0) [0|1] "" Host

BO_ 2629828608 BATT_diagnosticAhTotal_0: 8 Battery
 SG_ BATT_ahDchTotal_0 : 32|32@1+ (0.1,0) [0|500000] "Ah" Host
 SG_ BATT_ahChgTotal_0 : 0|32@1+ (0.1,0) [0|500000] "Ah" Host

BO_ 2629828609 BATT_diagnosticAhTotal_1: 8 Battery
 SG_ BATT_ahDchTotal_1 : 32|32@1+ (0.1,0) [0|500000] "Ah" Host
 SG_ BATT_ahChgTotal_1 : 0|32@1+ (0.1,0) [0|500000] "Ah" Host

BO_ 2629828610 BATT_diagnosticAhTotal_2: 8 Battery
 SG_ BATT_ahDchTotal_2 : 32|32@1+ (0.1,0) [0|500000] "Ah" Host
 SG_ BATT_ahChgTotal_2 : 0|32@1+ (0.1,0) [0|500000] "Ah" Host

BO_ 2629828611 BATT_diagnosticAhTotal_3: 8 Battery
 SG_ BATT_ahDchTotal_3 : 32|32@1+ (0.1,0) [0|500000] "Ah" Host
 SG_ BATT_ahChgTotal_3 : 0|32@1+ (0.1,0) [0|500000] "Ah" Host

BO_ 2629828612 BATT_diagnosticAhTotal_4: 8 Battery
 SG_ BATT_ahDchTotal_4 : 32|32@1+ (0.1,0) [0|500000] "Ah" Host
 SG_ BATT_ahChgTotal_4 : 0|32@1+ (0.1,0) [0|500000] "Ah" Host

BO_ 2629828613 BATT_diagnosticAhTotal_5: 8 Battery
 SG_ BATT_ahDchTotal_5 : 32|32@1+ (0.1,0) [0|500000] "Ah" Host
 SG_ BATT_ahChgTotal_5 : 0|32@1+ (0.1,0) [0|500000] "Ah" Host

BO_ 2629828614 BATT_diagnosticAhTotal_6: 8 Battery
 SG_ BATT_ahDchTotal_6 : 32|32@1+ (0.1,0) [0|500000] "Ah" Host
 SG_ BATT_ahChgTotal_6 : 0|32@1+ (0.1,0) [0|500000] "Ah" Host

BO_ 2629828615 BATT_diagnosticAhTotal_7: 8 Battery
 SG_ BATT_ahDchTotal_7 : 32|32@1+ (0.1,0) [0|500000] "Ah" Host
 SG_ BATT_ahChgTotal_7 : 0|32@1+ (0.1,0) [0|500000] "Ah" Host

BO_ 2629828616 BATT_diagnosticAhTotal_8: 8 Battery
 SG_ BATT_ahDchTotal_8 : 32|32@1+ (0.1,0) [0|500000] "Ah" Host
 SG_ BATT_ahChgTotal_8 : 0|32@1+ (0.1,0) [0|500000] "Ah" Host

BO_ 2629828617 BATT_diagnosticAhTotal_9: 8 Battery
 SG_ BATT_ahDchTotal_9 : 32|32@1+ (0.1,0) [0|500000] "Ah" Host
 SG_ BATT_ahChgTotal_9 : 0|32@1+ (0.1,0) [0|500000] "Ah" Host

BO_ 2629828618 BATT_diagnosticAhTotal_10: 8 Battery
 SG_ BATT_ahDchTotal_10 : 32|32@1+ (0.1,0) [0|500000] "Ah" Host
 SG_ BATT_ahChgTotal_10 : 0|32@1+ (0.1,0) [0|500000] "Ah" Host

BO_ 2629828619 BATT_diagnosticAhTotal_11: 8 Battery
 SG_ BATT_ahDchTotal_11 : 32|32@1+ (0.1,0) [0|500000] "Ah" Host
 SG_ BATT_ahChgTotal_11 : 0|32@1+ (0.1,0) [0|500000] "Ah" Host

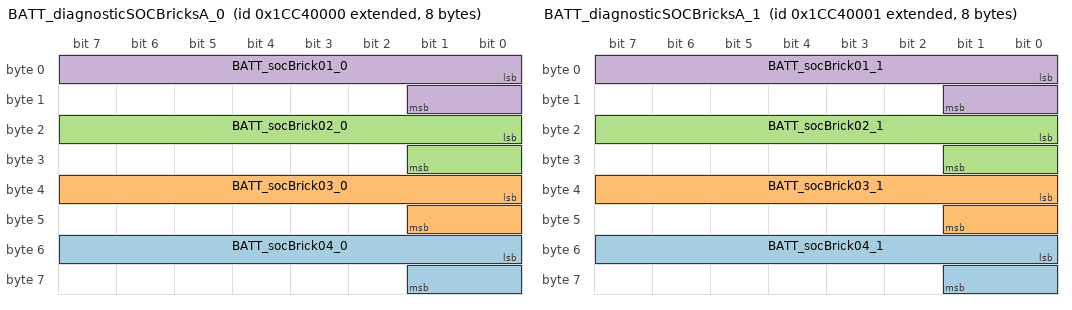
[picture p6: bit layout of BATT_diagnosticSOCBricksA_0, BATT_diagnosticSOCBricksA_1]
BO_ 2630090752 BATT_diagnosticSOCBricksA_0: 8 Battery
 SG_ BATT_socBrick04_0 : 48|10@1+ (0.1,0) [0|102.3] "%" Host
 SG_ BATT_socBrick03_0 : 32|10@1+ (0.1,0) [0|102.3] "%" Host
 SG_ BATT_socBrick02_0 : 16|10@1+ (0.1,0) [0|102.3] "%" Host
 SG_ BATT_socBrick01_0 : 0|10@1+ (0.1,0) [0|102.3] "%" Host

BO_ 2630090753 BATT_diagnosticSOCBricksA_1: 8 Battery
 SG_ BATT_socBrick04_1 : 48|10@1+ (0.1,0) [0|102.3] "%" Host
 SG_ BATT_socBrick03_1 : 32|10@1+ (0.1,0) [0|102.3] "%" Host
 SG_ BATT_socBrick02_1 : 16|10@1+ (0.1,0) [0|102.3] "%" Host
 SG_ BATT_socBrick01_1 : 0|10@1+ (0.1,0) [0|102.3] "%" Host

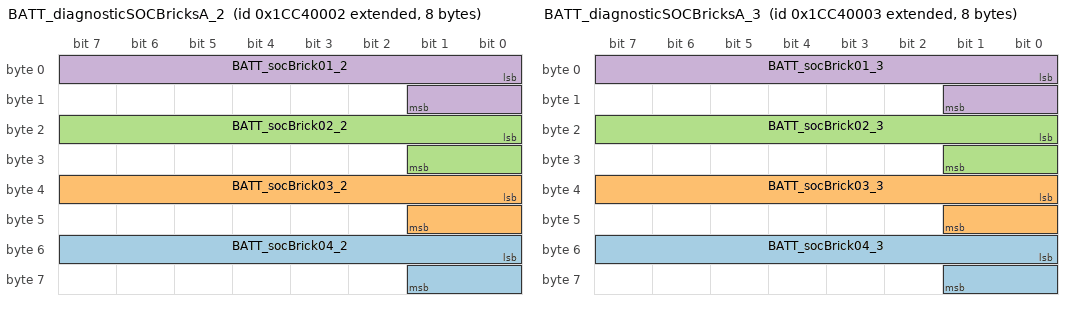
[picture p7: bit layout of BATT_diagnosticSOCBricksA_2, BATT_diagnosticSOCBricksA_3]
BO_ 2630090754 BATT_diagnosticSOCBricksA_2: 8 Battery
 SG_ BATT_socBrick04_2 : 48|10@1+ (0.1,0) [0|102.3] "%" Host
 SG_ BATT_socBrick03_2 : 32|10@1+ (0.1,0) [0|102.3] "%" Host
 SG_ BATT_socBrick02_2 : 16|10@1+ (0.1,0) [0|102.3] "%" Host
 SG_ BATT_socBrick01_2 : 0|10@1+ (0.1,0) [0|102.3] "%" Host

BO_ 2630090755 BATT_diagnosticSOCBricksA_3: 8 Battery
 SG_ BATT_socBrick04_3 : 48|10@1+ (0.1,0) [0|102.3] "%" Host
 SG_ BATT_socBrick03_3 : 32|10@1+ (0.1,0) [0|102.3] "%" Host
 SG_ BATT_socBrick02_3 : 16|10@1+ (0.1,0) [0|102.3] "%" Host
 SG_ BATT_socBrick01_3 : 0|10@1+ (0.1,0) [0|102.3] "%" Host

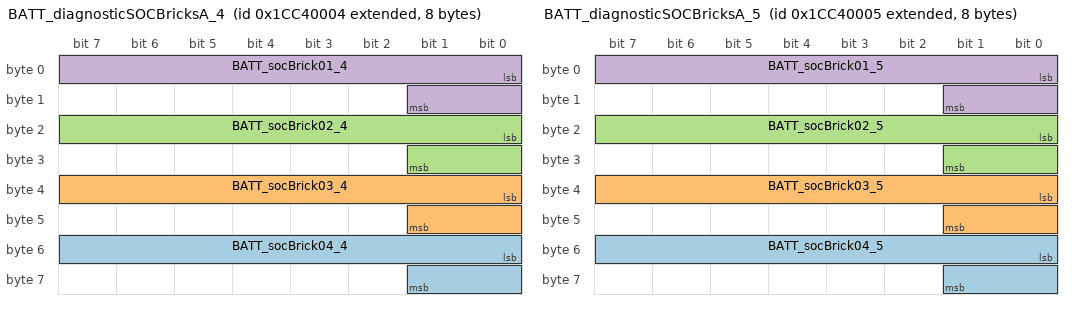
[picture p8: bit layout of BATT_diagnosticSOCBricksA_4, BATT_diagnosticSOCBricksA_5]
BO_ 2630090756 BATT_diagnosticSOCBricksA_4: 8 Battery
 SG_ BATT_socBrick04_4 : 48|10@1+ (0.1,0) [0|102.3] "%" Host
 SG_ BATT_socBrick03_4 : 32|10@1+ (0.1,0) [0|102.3] "%" Host
 SG_ BATT_socBrick02_4 : 16|10@1+ (0.1,0) [0|102.3] "%" Host
 SG_ BATT_socBrick01_4 : 0|10@1+ (0.1,0) [0|102.3] "%" Host

BO_ 2630090757 BATT_diagnosticSOCBricksA_5: 8 Battery
 SG_ BATT_socBrick04_5 : 48|10@1+ (0.1,0) [0|102.3] "%" Host
 SG_ BATT_socBrick03_5 : 32|10@1+ (0.1,0) [0|102.3] "%" Host
 SG_ BATT_socBrick02_5 : 16|10@1+ (0.1,0) [0|102.3] "%" Host
 SG_ BATT_socBrick01_5 : 0|10@1+ (0.1,0) [0|102.3] "%" Host

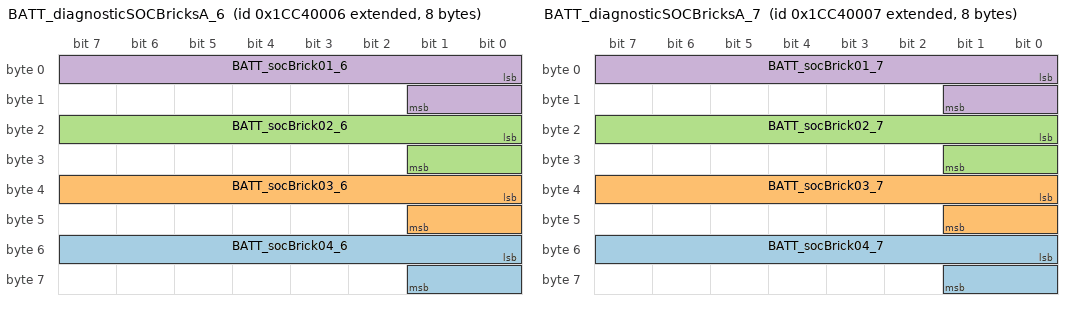
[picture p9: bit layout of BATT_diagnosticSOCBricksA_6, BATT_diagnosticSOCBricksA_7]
BO_ 2630090758 BATT_diagnosticSOCBricksA_6: 8 Battery
 SG_ BATT_socBrick04_6 : 48|10@1+ (0.1,0) [0|102.3] "%" Host
 SG_ BATT_socBrick03_6 : 32|10@1+ (0.1,0) [0|102.3] "%" Host
 SG_ BATT_socBrick02_6 : 16|10@1+ (0.1,0) [0|102.3] "%" Host
 SG_ BATT_socBrick01_6 : 0|10@1+ (0.1,0) [0|102.3] "%" Host

BO_ 2630090759 BATT_diagnosticSOCBricksA_7: 8 Battery
 SG_ BATT_socBrick04_7 : 48|10@1+ (0.1,0) [0|102.3] "%" Host
 SG_ BATT_socBrick03_7 : 32|10@1+ (0.1,0) [0|102.3] "%" Host
 SG_ BATT_socBrick02_7 : 16|10@1+ (0.1,0) [0|102.3] "%" Host
 SG_ BATT_socBrick01_7 : 0|10@1+ (0.1,0) [0|102.3] "%" Host

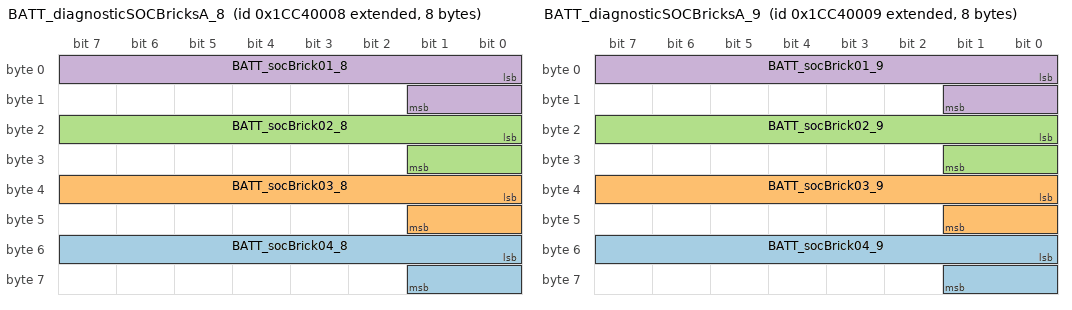
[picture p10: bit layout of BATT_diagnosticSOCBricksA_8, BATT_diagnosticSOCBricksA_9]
BO_ 2630090760 BATT_diagnosticSOCBricksA_8: 8 Battery
 SG_ BATT_socBrick04_8 : 48|10@1+ (0.1,0) [0|102.3] "%" Host
 SG_ BATT_socBrick03_8 : 32|10@1+ (0.1,0) [0|102.3] "%" Host
 SG_ BATT_socBrick02_8 : 16|10@1+ (0.1,0) [0|102.3] "%" Host
 SG_ BATT_socBrick01_8 : 0|10@1+ (0.1,0) [0|102.3] "%" Host

BO_ 2630090761 BATT_diagnosticSOCBricksA_9: 8 Battery
 SG_ BATT_socBrick04_9 : 48|10@1+ (0.1,0) [0|102.3] "%" Host
 SG_ BATT_socBrick03_9 : 32|10@1+ (0.1,0) [0|102.3] "%" Host
 SG_ BATT_socBrick02_9 : 16|10@1+ (0.1,0) [0|102.3] "%" Host
 SG_ BATT_socBrick01_9 : 0|10@1+ (0.1,0) [0|102.3] "%" Host

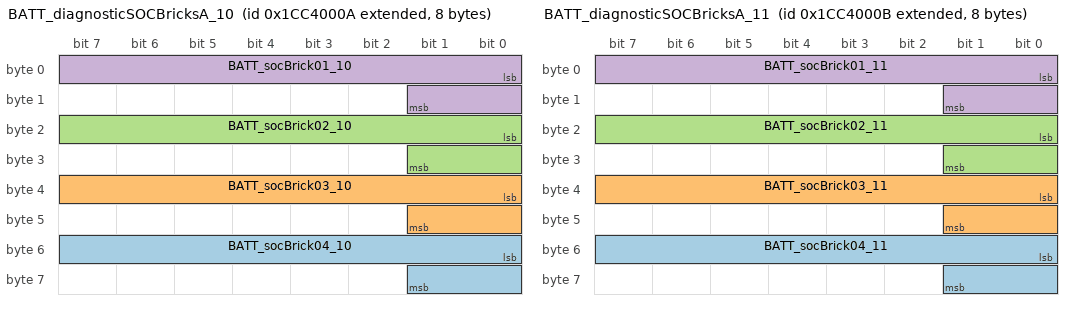
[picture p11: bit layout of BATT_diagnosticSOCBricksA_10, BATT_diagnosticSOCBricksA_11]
BO_ 2630090762 BATT_diagnosticSOCBricksA_10: 8 Battery
 SG_ BATT_socBrick04_10 : 48|10@1+ (0.1,0) [0|102.3] "%" Host
 SG_ BATT_socBrick03_10 : 32|10@1+ (0.1,0) [0|102.3] "%" Host
 SG_ BATT_socBrick02_10 : 16|10@1+ (0.1,0) [0|102.3] "%" Host
 SG_ BATT_socBrick01_10 : 0|10@1+ (0.1,0) [0|102.3] "%" Host

BO_ 2630090763 BATT_diagnosticSOCBricksA_11: 8 Battery
 SG_ BATT_socBrick04_11 : 48|10@1+ (0.1,0) [0|102.3] "%" Host
 SG_ BATT_socBrick03_11 : 32|10@1+ (0.1,0) [0|102.3] "%" Host
 SG_ BATT_socBrick02_11 : 16|10@1+ (0.1,0) [0|102.3] "%" Host
 SG_ BATT_socBrick01_11 : 0|10@1+ (0.1,0) [0|102.3] "%" Host

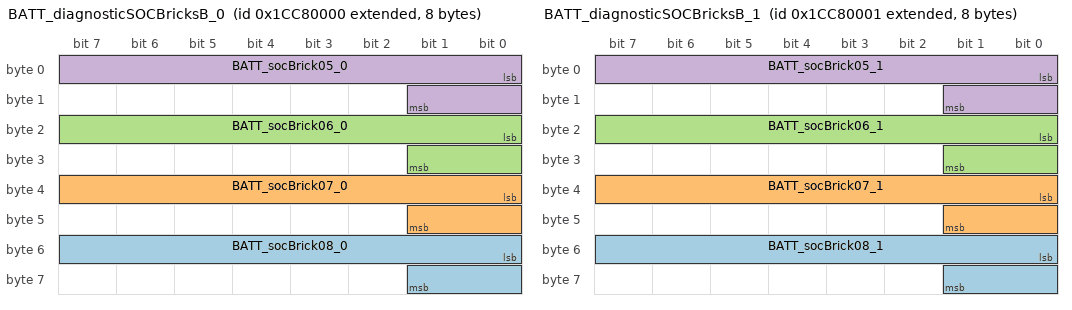
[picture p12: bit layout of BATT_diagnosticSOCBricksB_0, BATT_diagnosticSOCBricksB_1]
BO_ 2630352896 BATT_diagnosticSOCBricksB_0: 8 Battery
 SG_ BATT_socBrick08_0 : 48|10@1+ (0.1,0) [0|102.3] "%" Host
 SG_ BATT_socBrick07_0 : 32|10@1+ (0.1,0) [0|102.3] "%" Host
 SG_ BATT_socBrick06_0 : 16|10@1+ (0.1,0) [0|102.3] "%" Host
 SG_ BATT_socBrick05_0 : 0|10@1+ (0.1,0) [0|102.3] "%" Host

BO_ 2630352897 BATT_diagnosticSOCBricksB_1: 8 Battery
 SG_ BATT_socBrick08_1 : 48|10@1+ (0.1,0) [0|102.3] "%" Host
 SG_ BATT_socBrick07_1 : 32|10@1+ (0.1,0) [0|102.3] "%" Host
 SG_ BATT_socBrick06_1 : 16|10@1+ (0.1,0) [0|102.3] "%" Host
 SG_ BATT_socBrick05_1 : 0|10@1+ (0.1,0) [0|102.3] "%" Host

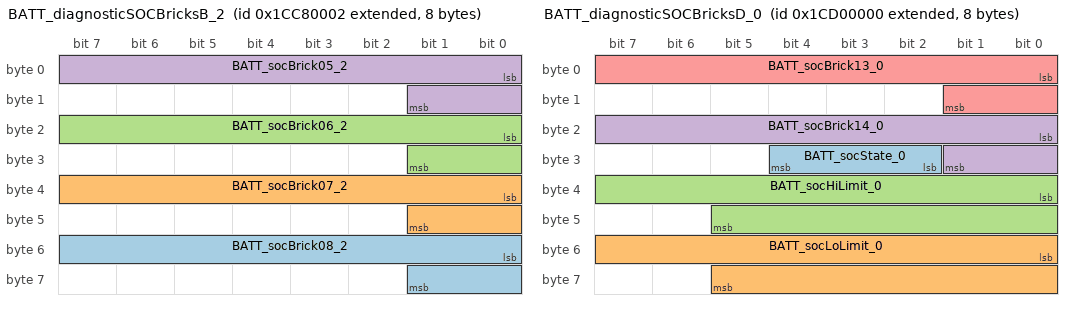
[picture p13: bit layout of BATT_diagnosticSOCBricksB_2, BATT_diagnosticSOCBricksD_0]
BO_ 2630352898 BATT_diagnosticSOCBricksB_2: 8 Battery
 SG_ BATT_socBrick08_2 : 48|10@1+ (0.1,0) [0|102.3] "%" Host
 SG_ BATT_socBrick07_2 : 32|10@1+ (0.1,0) [0|102.3] "%" Host
 SG_ BATT_socBrick06_2 : 16|10@1+ (0.1,0) [0|102.3] "%" Host
 SG_ BATT_socBrick05_2 : 0|10@1+ (0.1,0) [0|102.3] "%" Host

BO_ 2630352899 BATT_diagnosticSOCBricksB_3: 8 Battery
 SG_ BATT_socBrick08_3 : 48|10@1+ (0.1,0) [0|102.3] "%" Host
 SG_ BATT_socBrick07_3 : 32|10@1+ (0.1,0) [0|102.3] "%" Host
 SG_ BATT_socBrick06_3 : 16|10@1+ (0.1,0) [0|102.3] "%" Host
 SG_ BATT_socBrick05_3 : 0|10@1+ (0.1,0) [0|102.3] "%" Host

BO_ 2630352900 BATT_diagnosticSOCBricksB_4: 8 Battery
 SG_ BATT_socBrick08_4 : 48|10@1+ (0.1,0) [0|102.3] "%" Host
 SG_ BATT_socBrick07_4 : 32|10@1+ (0.1,0) [0|102.3] "%" Host
 SG_ BATT_socBrick06_4 : 16|10@1+ (0.1,0) [0|102.3] "%" Host
 SG_ BATT_socBrick05_4 : 0|10@1+ (0.1,0) [0|102.3] "%" Host

BO_ 2630352901 BATT_diagnosticSOCBricksB_5: 8 Battery
 SG_ BATT_socBrick08_5 : 48|10@1+ (0.1,0) [0|102.3] "%" Host
 SG_ BATT_socBrick07_5 : 32|10@1+ (0.1,0) [0|102.3] "%" Host
 SG_ BATT_socBrick06_5 : 16|10@1+ (0.1,0) [0|102.3] "%" Host
 SG_ BATT_socBrick05_5 : 0|10@1+ (0.1,0) [0|102.3] "%" Host

BO_ 2630352902 BATT_diagnosticSOCBricksB_6: 8 Battery
 SG_ BATT_socBrick08_6 : 48|10@1+ (0.1,0) [0|102.3] "%" Host
 SG_ BATT_socBrick07_6 : 32|10@1+ (0.1,0) [0|102.3] "%" Host
 SG_ BATT_socBrick06_6 : 16|10@1+ (0.1,0) [0|102.3] "%" Host
 SG_ BATT_socBrick05_6 : 0|10@1+ (0.1,0) [0|102.3] "%" Host

BO_ 2630352903 BATT_diagnosticSOCBricksB_7: 8 Battery
 SG_ BATT_socBrick08_7 : 48|10@1+ (0.1,0) [0|102.3] "%" Host
 SG_ BATT_socBrick07_7 : 32|10@1+ (0.1,0) [0|102.3] "%" Host
 SG_ BATT_socBrick06_7 : 16|10@1+ (0.1,0) [0|102.3] "%" Host
 SG_ BATT_socBrick05_7 : 0|10@1+ (0.1,0) [0|102.3] "%" Host

BO_ 2630352904 BATT_diagnosticSOCBricksB_8: 8 Battery
 SG_ BATT_socBrick08_8 : 48|10@1+ (0.1,0) [0|102.3] "%" Host
 SG_ BATT_socBrick07_8 : 32|10@1+ (0.1,0) [0|102.3] "%" Host
 SG_ BATT_socBrick06_8 : 16|10@1+ (0.1,0) [0|102.3] "%" Host
 SG_ BATT_socBrick05_8 : 0|10@1+ (0.1,0) [0|102.3] "%" Host

BO_ 2630352905 BATT_diagnosticSOCBricksB_9: 8 Battery
 SG_ BATT_socBrick08_9 : 48|10@1+ (0.1,0) [0|102.3] "%" Host
 SG_ BATT_socBrick07_9 : 32|10@1+ (0.1,0) [0|102.3] "%" Host
 SG_ BATT_socBrick06_9 : 16|10@1+ (0.1,0) [0|102.3] "%" Host
 SG_ BATT_socBrick05_9 : 0|10@1+ (0.1,0) [0|102.3] "%" Host

BO_ 2630352906 BATT_diagnosticSOCBricksB_10: 8 Battery
 SG_ BATT_socBrick08_10 : 48|10@1+ (0.1,0) [0|102.3] "%" Host
 SG_ BATT_socBrick07_10 : 32|10@1+ (0.1,0) [0|102.3] "%" Host
 SG_ BATT_socBrick06_10 : 16|10@1+ (0.1,0) [0|102.3] "%" Host
 SG_ BATT_socBrick05_10 : 0|10@1+ (0.1,0) [0|102.3] "%" Host

BO_ 2630352907 BATT_diagnosticSOCBricksB_11: 8 Battery
 SG_ BATT_socBrick08_11 : 48|10@1+ (0.1,0) [0|102.3] "%" Host
 SG_ BATT_socBrick07_11 : 32|10@1+ (0.1,0) [0|102.3] "%" Host
 SG_ BATT_socBrick06_11 : 16|10@1+ (0.1,0) [0|102.3] "%" Host
 SG_ BATT_socBrick05_11 : 0|10@1+ (0.1,0) [0|102.3] "%" Host

BO_ 2630615040 BATT_diagnosticSOCBricksC_0: 8 Battery
 SG_ BATT_socBrick12_0 : 48|10@1+ (0.1,0) [0|102.3] "%" Host
 SG_ BATT_socBrick11_0 : 32|10@1+ (0.1,0) [0|102.3] "%" Host
 SG_ BATT_socBrick09_0 : 0|10@1+ (0.1,0) [0|102.3] "%" Host
 SG_ BATT_socBrick10_0 : 16|10@1+ (0.1,0) [0|102.3] "%" Host

BO_ 2630615041 BATT_diagnosticSOCBricksC_1: 8 Battery
 SG_ BATT_socBrick12_1 : 48|10@1+ (0.1,0) [0|102.3] "%" Host
 SG_ BATT_socBrick11_1 : 32|10@1+ (0.1,0) [0|102.3] "%" Host
 SG_ BATT_socBrick09_1 : 0|10@1+ (0.1,0) [0|102.3] "%" Host
 SG_ BATT_socBrick10_1 : 16|10@1+ (0.1,0) [0|102.3] "%" Host

BO_ 2630615042 BATT_diagnosticSOCBricksC_2: 8 Battery
 SG_ BATT_socBrick12_2 : 48|10@1+ (0.1,0) [0|102.3] "%" Host
 SG_ BATT_socBrick11_2 : 32|10@1+ (0.1,0) [0|102.3] "%" Host
 SG_ BATT_socBrick09_2 : 0|10@1+ (0.1,0) [0|102.3] "%" Host
 SG_ BATT_socBrick10_2 : 16|10@1+ (0.1,0) [0|102.3] "%" Host

BO_ 2630615043 BATT_diagnosticSOCBricksC_3: 8 Battery
 SG_ BATT_socBrick12_3 : 48|10@1+ (0.1,0) [0|102.3] "%" Host
 SG_ BATT_socBrick11_3 : 32|10@1+ (0.1,0) [0|102.3] "%" Host
 SG_ BATT_socBrick09_3 : 0|10@1+ (0.1,0) [0|102.3] "%" Host
 SG_ BATT_socBrick10_3 : 16|10@1+ (0.1,0) [0|102.3] "%" Host

BO_ 2630615044 BATT_diagnosticSOCBricksC_4: 8 Battery
 SG_ BATT_socBrick12_4 : 48|10@1+ (0.1,0) [0|102.3] "%" Host
 SG_ BATT_socBrick11_4 : 32|10@1+ (0.1,0) [0|102.3] "%" Host
 SG_ BATT_socBrick09_4 : 0|10@1+ (0.1,0) [0|102.3] "%" Host
 SG_ BATT_socBrick10_4 : 16|10@1+ (0.1,0) [0|102.3] "%" Host

BO_ 2630615045 BATT_diagnosticSOCBricksC_5: 8 Battery
 SG_ BATT_socBrick12_5 : 48|10@1+ (0.1,0) [0|102.3] "%" Host
 SG_ BATT_socBrick11_5 : 32|10@1+ (0.1,0) [0|102.3] "%" Host
 SG_ BATT_socBrick09_5 : 0|10@1+ (0.1,0) [0|102.3] "%" Host
 SG_ BATT_socBrick10_5 : 16|10@1+ (0.1,0) [0|102.3] "%" Host

BO_ 2630615046 BATT_diagnosticSOCBricksC_6: 8 Battery
 SG_ BATT_socBrick12_6 : 48|10@1+ (0.1,0) [0|102.3] "%" Host
 SG_ BATT_socBrick11_6 : 32|10@1+ (0.1,0) [0|102.3] "%" Host
 SG_ BATT_socBrick09_6 : 0|10@1+ (0.1,0) [0|102.3] "%" Host
 SG_ BATT_socBrick10_6 : 16|10@1+ (0.1,0) [0|102.3] "%" Host

BO_ 2630615047 BATT_diagnosticSOCBricksC_7: 8 Battery
 SG_ BATT_socBrick12_7 : 48|10@1+ (0.1,0) [0|102.3] "%" Host
 SG_ BATT_socBrick11_7 : 32|10@1+ (0.1,0) [0|102.3] "%" Host
 SG_ BATT_socBrick09_7 : 0|10@1+ (0.1,0) [0|102.3] "%" Host
 SG_ BATT_socBrick10_7 : 16|10@1+ (0.1,0) [0|102.3] "%" Host

BO_ 2630615048 BATT_diagnosticSOCBricksC_8: 8 Battery
 SG_ BATT_socBrick12_8 : 48|10@1+ (0.1,0) [0|102.3] "%" Host
 SG_ BATT_socBrick11_8 : 32|10@1+ (0.1,0) [0|102.3] "%" Host
 SG_ BATT_socBrick09_8 : 0|10@1+ (0.1,0) [0|102.3] "%" Host
 SG_ BATT_socBrick10_8 : 16|10@1+ (0.1,0) [0|102.3] "%" Host

BO_ 2630615049 BATT_diagnosticSOCBricksC_9: 8 Battery
 SG_ BATT_socBrick12_9 : 48|10@1+ (0.1,0) [0|102.3] "%" Host
 SG_ BATT_socBrick11_9 : 32|10@1+ (0.1,0) [0|102.3] "%" Host
 SG_ BATT_socBrick09_9 : 0|10@1+ (0.1,0) [0|102.3] "%" Host
 SG_ BATT_socBrick10_9 : 16|10@1+ (0.1,0) [0|102.3] "%" Host

BO_ 2630615050 BATT_diagnosticSOCBricksC_10: 8 Battery
 SG_ BATT_socBrick12_10 : 48|10@1+ (0.1,0) [0|102.3] "%" Host
 SG_ BATT_socBrick11_10 : 32|10@1+ (0.1,0) [0|102.3] "%" Host
 SG_ BATT_socBrick09_10 : 0|10@1+ (0.1,0) [0|102.3] "%" Host
 SG_ BATT_socBrick10_10 : 16|10@1+ (0.1,0) [0|102.3] "%" Host

BO_ 2630615051 BATT_diagnosticSOCBricksC_11: 8 Battery
 SG_ BATT_socBrick12_11 : 48|10@1+ (0.1,0) [0|102.3] "%" Host
 SG_ BATT_socBrick11_11 : 32|10@1+ (0.1,0) [0|102.3] "%" Host
 SG_ BATT_socBrick09_11 : 0|10@1+ (0.1,0) [0|102.3] "%" Host
 SG_ BATT_socBrick10_11 : 16|10@1+ (0.1,0) [0|102.3] "%" Host

BO_ 2630877184 BATT_diagnosticSOCBricksD_0: 8 Battery
 SG_ BATT_socState_0 : 26|3@1+ (1,0) [0|7] "" Host
 SG_ BATT_socLoLimit_0 : 48|14@1+ (1,0) [0|16383] "" Host
 SG_ BATT_socHiLimit_0 : 32|14@1+ (1,0) [0|16383] "" Host
 SG_ BATT_socBrick14_0 : 16|10@1+ (0.1,0) [0|102.3] "%" Host
 SG_ BATT_socBrick13_0 : 0|10@1+ (0.1,0) [0|102.3] "%" Host

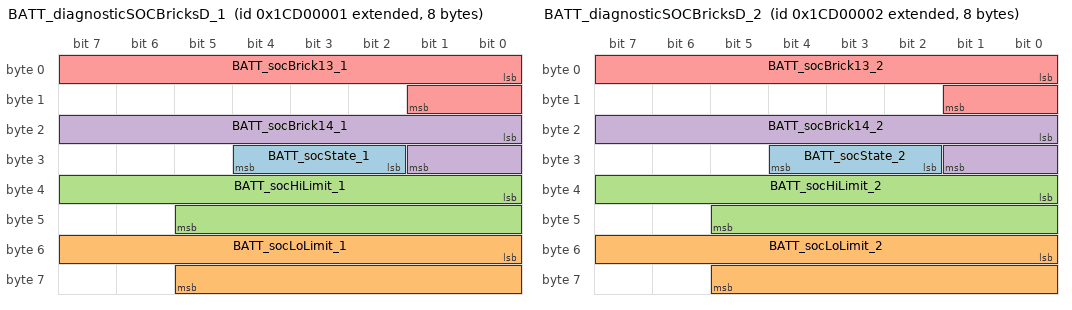
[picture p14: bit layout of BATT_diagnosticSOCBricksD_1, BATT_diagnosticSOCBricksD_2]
BO_ 2630877185 BATT_diagnosticSOCBricksD_1: 8 Battery
 SG_ BATT_socState_1 : 26|3@1+ (1,0) [0|7] "" Host
 SG_ BATT_socLoLimit_1 : 48|14@1+ (1,0) [0|16383] "" Host
 SG_ BATT_socHiLimit_1 : 32|14@1+ (1,0) [0|16383] "" Host
 SG_ BATT_socBrick14_1 : 16|10@1+ (0.1,0) [0|102.3] "%" Host
 SG_ BATT_socBrick13_1 : 0|10@1+ (0.1,0) [0|102.3] "%" Host

BO_ 2630877186 BATT_diagnosticSOCBricksD_2: 8 Battery
 SG_ BATT_socState_2 : 26|3@1+ (1,0) [0|7] "" Host
 SG_ BATT_socLoLimit_2 : 48|14@1+ (1,0) [0|16383] "" Host
 SG_ BATT_socHiLimit_2 : 32|14@1+ (1,0) [0|16383] "" Host
 SG_ BATT_socBrick14_2 : 16|10@1+ (0.1,0) [0|102.3] "%" Host
 SG_ BATT_socBrick13_2 : 0|10@1+ (0.1,0) [0|102.3] "%" Host

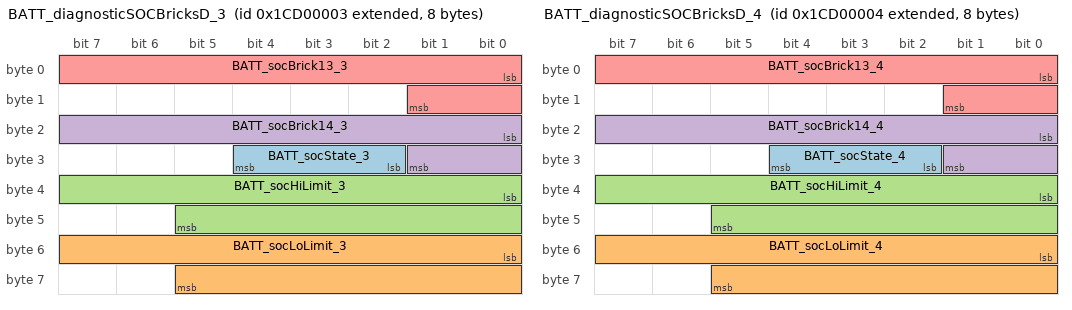
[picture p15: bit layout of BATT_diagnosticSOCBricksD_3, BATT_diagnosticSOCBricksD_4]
BO_ 2630877187 BATT_diagnosticSOCBricksD_3: 8 Battery
 SG_ BATT_socState_3 : 26|3@1+ (1,0) [0|7] "" Host
 SG_ BATT_socLoLimit_3 : 48|14@1+ (1,0) [0|16383] "" Host
 SG_ BATT_socHiLimit_3 : 32|14@1+ (1,0) [0|16383] "" Host
 SG_ BATT_socBrick14_3 : 16|10@1+ (0.1,0) [0|102.3] "%" Host
 SG_ BATT_socBrick13_3 : 0|10@1+ (0.1,0) [0|102.3] "%" Host

BO_ 2630877188 BATT_diagnosticSOCBricksD_4: 8 Battery
 SG_ BATT_socState_4 : 26|3@1+ (1,0) [0|7] "" Host
 SG_ BATT_socLoLimit_4 : 48|14@1+ (1,0) [0|16383] "" Host
 SG_ BATT_socHiLimit_4 : 32|14@1+ (1,0) [0|16383] "" Host
 SG_ BATT_socBrick14_4 : 16|10@1+ (0.1,0) [0|102.3] "%" Host
 SG_ BATT_socBrick13_4 : 0|10@1+ (0.1,0) [0|102.3] "%" Host

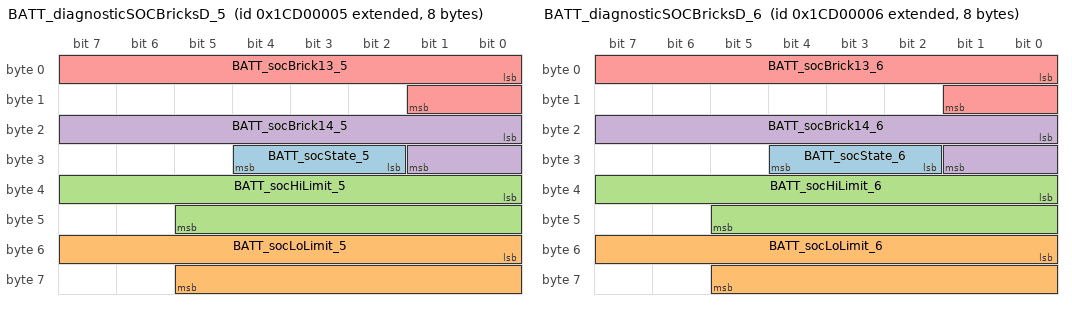
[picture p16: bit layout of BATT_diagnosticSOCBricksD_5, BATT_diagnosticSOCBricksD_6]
BO_ 2630877189 BATT_diagnosticSOCBricksD_5: 8 Battery
 SG_ BATT_socState_5 : 26|3@1+ (1,0) [0|7] "" Host
 SG_ BATT_socLoLimit_5 : 48|14@1+ (1,0) [0|16383] "" Host
 SG_ BATT_socHiLimit_5 : 32|14@1+ (1,0) [0|16383] "" Host
 SG_ BATT_socBrick14_5 : 16|10@1+ (0.1,0) [0|102.3] "%" Host
 SG_ BATT_socBrick13_5 : 0|10@1+ (0.1,0) [0|102.3] "%" Host

BO_ 2630877190 BATT_diagnosticSOCBricksD_6: 8 Battery
 SG_ BATT_socState_6 : 26|3@1+ (1,0) [0|7] "" Host
 SG_ BATT_socLoLimit_6 : 48|14@1+ (1,0) [0|16383] "" Host
 SG_ BATT_socHiLimit_6 : 32|14@1+ (1,0) [0|16383] "" Host
 SG_ BATT_socBrick14_6 : 16|10@1+ (0.1,0) [0|102.3] "%" Host
 SG_ BATT_socBrick13_6 : 0|10@1+ (0.1,0) [0|102.3] "%" Host

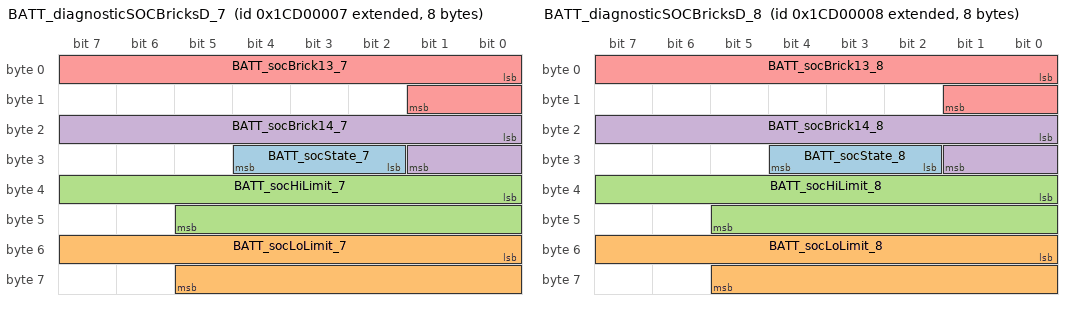
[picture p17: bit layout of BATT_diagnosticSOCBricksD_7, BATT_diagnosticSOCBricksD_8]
BO_ 2630877191 BATT_diagnosticSOCBricksD_7: 8 Battery
 SG_ BATT_socState_7 : 26|3@1+ (1,0) [0|7] "" Host
 SG_ BATT_socLoLimit_7 : 48|14@1+ (1,0) [0|16383] "" Host
 SG_ BATT_socHiLimit_7 : 32|14@1+ (1,0) [0|16383] "" Host
 SG_ BATT_socBrick14_7 : 16|10@1+ (0.1,0) [0|102.3] "%" Host
 SG_ BATT_socBrick13_7 : 0|10@1+ (0.1,0) [0|102.3] "%" Host

BO_ 2630877192 BATT_diagnosticSOCBricksD_8: 8 Battery
 SG_ BATT_socState_8 : 26|3@1+ (1,0) [0|7] "" Host
 SG_ BATT_socLoLimit_8 : 48|14@1+ (1,0) [0|16383] "" Host
 SG_ BATT_socHiLimit_8 : 32|14@1+ (1,0) [0|16383] "" Host
 SG_ BATT_socBrick14_8 : 16|10@1+ (0.1,0) [0|102.3] "%" Host
 SG_ BATT_socBrick13_8 : 0|10@1+ (0.1,0) [0|102.3] "%" Host

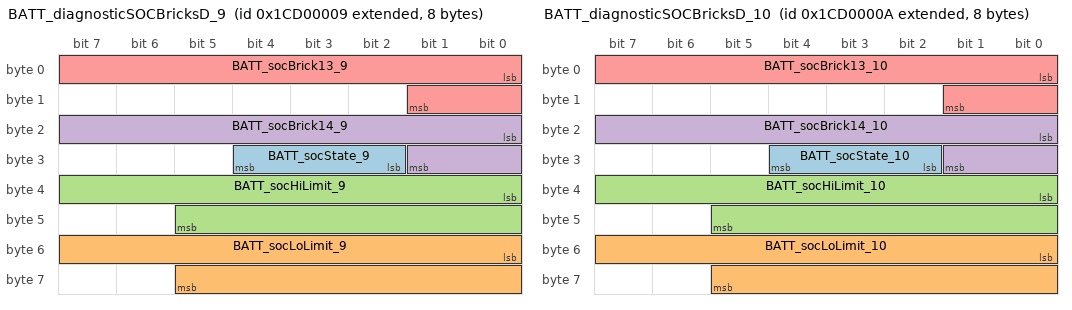
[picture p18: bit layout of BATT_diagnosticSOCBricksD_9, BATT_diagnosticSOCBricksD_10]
BO_ 2630877193 BATT_diagnosticSOCBricksD_9: 8 Battery
 SG_ BATT_socState_9 : 26|3@1+ (1,0) [0|7] "" Host
 SG_ BATT_socLoLimit_9 : 48|14@1+ (1,0) [0|16383] "" Host
 SG_ BATT_socHiLimit_9 : 32|14@1+ (1,0) [0|16383] "" Host
 SG_ BATT_socBrick14_9 : 16|10@1+ (0.1,0) [0|102.3] "%" Host
 SG_ BATT_socBrick13_9 : 0|10@1+ (0.1,0) [0|102.3] "%" Host

BO_ 2630877194 BATT_diagnosticSOCBricksD_10: 8 Battery
 SG_ BATT_socState_10 : 26|3@1+ (1,0) [0|7] "" Host
 SG_ BATT_socLoLimit_10 : 48|14@1+ (1,0) [0|16383] "" Host
 SG_ BATT_socHiLimit_10 : 32|14@1+ (1,0) [0|16383] "" Host
 SG_ BATT_socBrick14_10 : 16|10@1+ (0.1,0) [0|102.3] "%" Host
 SG_ BATT_socBrick13_10 : 0|10@1+ (0.1,0) [0|102.3] "%" Host

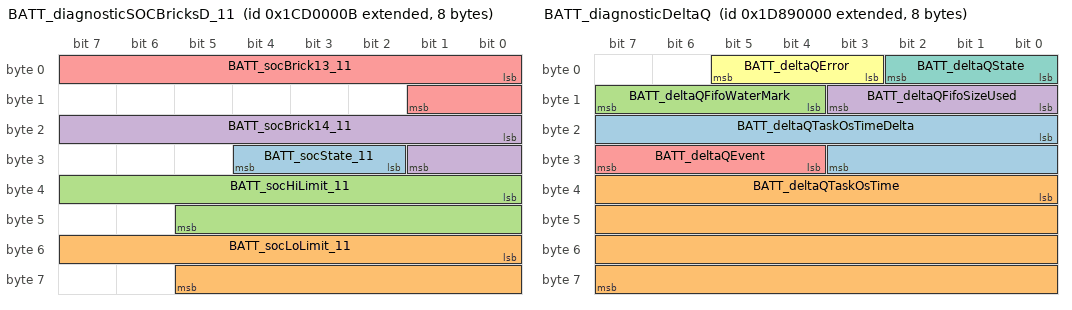
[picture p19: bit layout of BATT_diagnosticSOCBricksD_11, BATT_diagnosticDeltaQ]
BO_ 2630877195 BATT_diagnosticSOCBricksD_11: 8 Battery
 SG_ BATT_socState_11 : 26|3@1+ (1,0) [0|7] "" Host
 SG_ BATT_socLoLimit_11 : 48|14@1+ (1,0) [0|16383] "" Host
 SG_ BATT_socHiLimit_11 : 32|14@1+ (1,0) [0|16383] "" Host
 SG_ BATT_socBrick14_11 : 16|10@1+ (0.1,0) [0|102.3] "%" Host
 SG_ BATT_socBrick13_11 : 0|10@1+ (0.1,0) [0|102.3] "%" Host

BO_ 2642411520 BATT_taskStackDiag_0: 8 Battery
 SG_ BATT_canTaskStack_0 : 48|8@1+ (1,0) [0|100] "%" Host
 SG_ BATT_afeTaskStack_0 : 40|8@1+ (1,0) [0|100] "%" Host
 SG_ BATT_nvmTaskStack_0 : 32|8@1+ (1,0) [0|100] "%" Host
 SG_ BATT_10hzTaskStack_0 : 16|8@1+ (1,0) [0|100] "%" Host
 SG_ BATT_100hzTaskStack_0 : 8|8@1+ (1,0) [0|100] "%" Host
 SG_ BATT_1000hzTaskStack_0 : 0|8@1+ (1,0) [0|100] "%" Host

BO_ 2642411521 BATT_taskStackDiag_1: 8 Battery
 SG_ BATT_canTaskStack_1 : 48|8@1+ (1,0) [0|100] "%" Host
 SG_ BATT_afeTaskStack_1 : 40|8@1+ (1,0) [0|100] "%" Host
 SG_ BATT_nvmTaskStack_1 : 32|8@1+ (1,0) [0|100] "%" Host
 SG_ BATT_10hzTaskStack_1 : 16|8@1+ (1,0) [0|100] "%" Host
 SG_ BATT_100hzTaskStack_1 : 8|8@1+ (1,0) [0|100] "%" Host
 SG_ BATT_1000hzTaskStack_1 : 0|8@1+ (1,0) [0|100] "%" Host

BO_ 2642411522 BATT_taskStackDiag_2: 8 Battery
 SG_ BATT_canTaskStack_2 : 48|8@1+ (1,0) [0|100] "%" Host
 SG_ BATT_afeTaskStack_2 : 40|8@1+ (1,0) [0|100] "%" Host
 SG_ BATT_nvmTaskStack_2 : 32|8@1+ (1,0) [0|100] "%" Host
 SG_ BATT_10hzTaskStack_2 : 16|8@1+ (1,0) [0|100] "%" Host
 SG_ BATT_100hzTaskStack_2 : 8|8@1+ (1,0) [0|100] "%" Host
 SG_ BATT_1000hzTaskStack_2 : 0|8@1+ (1,0) [0|100] "%" Host

BO_ 2642411523 BATT_taskStackDiag_3: 8 Battery
 SG_ BATT_canTaskStack_3 : 48|8@1+ (1,0) [0|100] "%" Host
 SG_ BATT_afeTaskStack_3 : 40|8@1+ (1,0) [0|100] "%" Host
 SG_ BATT_nvmTaskStack_3 : 32|8@1+ (1,0) [0|100] "%" Host
 SG_ BATT_10hzTaskStack_3 : 16|8@1+ (1,0) [0|100] "%" Host
 SG_ BATT_100hzTaskStack_3 : 8|8@1+ (1,0) [0|100] "%" Host
 SG_ BATT_1000hzTaskStack_3 : 0|8@1+ (1,0) [0|100] "%" Host

BO_ 2642411524 BATT_taskStackDiag_4: 8 Battery
 SG_ BATT_canTaskStack_4 : 48|8@1+ (1,0) [0|100] "%" Host
 SG_ BATT_afeTaskStack_4 : 40|8@1+ (1,0) [0|100] "%" Host
 SG_ BATT_nvmTaskStack_4 : 32|8@1+ (1,0) [0|100] "%" Host
 SG_ BATT_10hzTaskStack_4 : 16|8@1+ (1,0) [0|100] "%" Host
 SG_ BATT_100hzTaskStack_4 : 8|8@1+ (1,0) [0|100] "%" Host
 SG_ BATT_1000hzTaskStack_4 : 0|8@1+ (1,0) [0|100] "%" Host

BO_ 2642411525 BATT_taskStackDiag_5: 8 Battery
 SG_ BATT_canTaskStack_5 : 48|8@1+ (1,0) [0|100] "%" Host
 SG_ BATT_afeTaskStack_5 : 40|8@1+ (1,0) [0|100] "%" Host
 SG_ BATT_nvmTaskStack_5 : 32|8@1+ (1,0) [0|100] "%" Host
 SG_ BATT_10hzTaskStack_5 : 16|8@1+ (1,0) [0|100] "%" Host
 SG_ BATT_100hzTaskStack_5 : 8|8@1+ (1,0) [0|100] "%" Host
 SG_ BATT_1000hzTaskStack_5 : 0|8@1+ (1,0) [0|100] "%" Host

BO_ 2642411526 BATT_taskStackDiag_6: 8 Battery
 SG_ BATT_canTaskStack_6 : 48|8@1+ (1,0) [0|100] "%" Host
 SG_ BATT_afeTaskStack_6 : 40|8@1+ (1,0) [0|100] "%" Host
 SG_ BATT_nvmTaskStack_6 : 32|8@1+ (1,0) [0|100] "%" Host
 SG_ BATT_10hzTaskStack_6 : 16|8@1+ (1,0) [0|100] "%" Host
 SG_ BATT_100hzTaskStack_6 : 8|8@1+ (1,0) [0|100] "%" Host
 SG_ BATT_1000hzTaskStack_6 : 0|8@1+ (1,0) [0|100] "%" Host

BO_ 2642411527 BATT_taskStackDiag_7: 8 Battery
 SG_ BATT_canTaskStack_7 : 48|8@1+ (1,0) [0|100] "%" Host
 SG_ BATT_afeTaskStack_7 : 40|8@1+ (1,0) [0|100] "%" Host
 SG_ BATT_nvmTaskStack_7 : 32|8@1+ (1,0) [0|100] "%" Host
 SG_ BATT_10hzTaskStack_7 : 16|8@1+ (1,0) [0|100] "%" Host
 SG_ BATT_100hzTaskStack_7 : 8|8@1+ (1,0) [0|100] "%" Host
 SG_ BATT_1000hzTaskStack_7 : 0|8@1+ (1,0) [0|100] "%" Host

BO_ 2642411528 BATT_taskStackDiag_8: 8 Battery
 SG_ BATT_canTaskStack_8 : 48|8@1+ (1,0) [0|100] "%" Host
 SG_ BATT_afeTaskStack_8 : 40|8@1+ (1,0) [0|100] "%" Host
 SG_ BATT_nvmTaskStack_8 : 32|8@1+ (1,0) [0|100] "%" Host
 SG_ BATT_10hzTaskStack_8 : 16|8@1+ (1,0) [0|100] "%" Host
 SG_ BATT_100hzTaskStack_8 : 8|8@1+ (1,0) [0|100] "%" Host
 SG_ BATT_1000hzTaskStack_8 : 0|8@1+ (1,0) [0|100] "%" Host

BO_ 2642411529 BATT_taskStackDiag_9: 8 Battery
 SG_ BATT_canTaskStack_9 : 48|8@1+ (1,0) [0|100] "%" Host
 SG_ BATT_afeTaskStack_9 : 40|8@1+ (1,0) [0|100] "%" Host
 SG_ BATT_nvmTaskStack_9 : 32|8@1+ (1,0) [0|100] "%" Host
 SG_ BATT_10hzTaskStack_9 : 16|8@1+ (1,0) [0|100] "%" Host
 SG_ BATT_100hzTaskStack_9 : 8|8@1+ (1,0) [0|100] "%" Host
 SG_ BATT_1000hzTaskStack_9 : 0|8@1+ (1,0) [0|100] "%" Host

BO_ 2642411530 BATT_taskStackDiag_10: 8 Battery
 SG_ BATT_canTaskStack_10 : 48|8@1+ (1,0) [0|100] "%" Host
 SG_ BATT_afeTaskStack_10 : 40|8@1+ (1,0) [0|100] "%" Host
 SG_ BATT_nvmTaskStack_10 : 32|8@1+ (1,0) [0|100] "%" Host
 SG_ BATT_10hzTaskStack_10 : 16|8@1+ (1,0) [0|100] "%" Host
 SG_ BATT_100hzTaskStack_10 : 8|8@1+ (1,0) [0|100] "%" Host
 SG_ BATT_1000hzTaskStack_10 : 0|8@1+ (1,0) [0|100] "%" Host

BO_ 2642411531 BATT_taskStackDiag_11: 8 Battery
 SG_ BATT_canTaskStack_11 : 48|8@1+ (1,0) [0|100] "%" Host
 SG_ BATT_afeTaskStack_11 : 40|8@1+ (1,0) [0|100] "%" Host
 SG_ BATT_nvmTaskStack_11 : 32|8@1+ (1,0) [0|100] "%" Host
 SG_ BATT_10hzTaskStack_11 : 16|8@1+ (1,0) [0|100] "%" Host
 SG_ BATT_100hzTaskStack_11 : 8|8@1+ (1,0) [0|100] "%" Host
 SG_ BATT_1000hzTaskStack_11 : 0|8@1+ (1,0) [0|100] "%" Host

BO_ 2642935808 BATT_diagnosticCan_0: 4 Battery
 SG_ BATT_canTXFifoSizeUsed_0 : 24|8@1+ (1,0) [0|255] "" Host
 SG_ BATT_canRXFifoSizeUsed_0 : 8|8@1+ (1,0) [0|255] "" Host
 SG_ BATT_canTXFifoWaterMark_0 : 16|8@1+ (1,0) [0|65535] "" Host
 SG_ BATT_canRXFifoWaterMark_0 : 0|8@1+ (1,0) [0|255] "" Host

BO_ 2642935809 BATT_diagnosticCan_1: 4 Battery
 SG_ BATT_canTXFifoSizeUsed_1 : 24|8@1+ (1,0) [0|255] "" Host
 SG_ BATT_canRXFifoSizeUsed_1 : 8|8@1+ (1,0) [0|255] "" Host
 SG_ BATT_canTXFifoWaterMark_1 : 16|8@1+ (1,0) [0|65535] "" Host
 SG_ BATT_canRXFifoWaterMark_1 : 0|8@1+ (1,0) [0|255] "" Host

BO_ 2642935810 BATT_diagnosticCan_2: 4 Battery
 SG_ BATT_canTXFifoSizeUsed_2 : 24|8@1+ (1,0) [0|255] "" Host
 SG_ BATT_canRXFifoSizeUsed_2 : 8|8@1+ (1,0) [0|255] "" Host
 SG_ BATT_canTXFifoWaterMark_2 : 16|8@1+ (1,0) [0|65535] "" Host
 SG_ BATT_canRXFifoWaterMark_2 : 0|8@1+ (1,0) [0|255] "" Host

BO_ 2642935811 BATT_diagnosticCan_3: 4 Battery
 SG_ BATT_canTXFifoSizeUsed_3 : 24|8@1+ (1,0) [0|255] "" Host
 SG_ BATT_canRXFifoSizeUsed_3 : 8|8@1+ (1,0) [0|255] "" Host
 SG_ BATT_canTXFifoWaterMark_3 : 16|8@1+ (1,0) [0|65535] "" Host
 SG_ BATT_canRXFifoWaterMark_3 : 0|8@1+ (1,0) [0|255] "" Host

BO_ 2642935812 BATT_diagnosticCan_4: 4 Battery
 SG_ BATT_canTXFifoSizeUsed_4 : 24|8@1+ (1,0) [0|255] "" Host
 SG_ BATT_canRXFifoSizeUsed_4 : 8|8@1+ (1,0) [0|255] "" Host
 SG_ BATT_canTXFifoWaterMark_4 : 16|8@1+ (1,0) [0|65535] "" Host
 SG_ BATT_canRXFifoWaterMark_4 : 0|8@1+ (1,0) [0|255] "" Host

BO_ 2642935813 BATT_diagnosticCan_5: 4 Battery
 SG_ BATT_canTXFifoSizeUsed_5 : 24|8@1+ (1,0) [0|255] "" Host
 SG_ BATT_canRXFifoSizeUsed_5 : 8|8@1+ (1,0) [0|255] "" Host
 SG_ BATT_canTXFifoWaterMark_5 : 16|8@1+ (1,0) [0|65535] "" Host
 SG_ BATT_canRXFifoWaterMark_5 : 0|8@1+ (1,0) [0|255] "" Host

BO_ 2642935814 BATT_diagnosticCan_6: 4 Battery
 SG_ BATT_canTXFifoSizeUsed_6 : 24|8@1+ (1,0) [0|255] "" Host
 SG_ BATT_canRXFifoSizeUsed_6 : 8|8@1+ (1,0) [0|255] "" Host
 SG_ BATT_canTXFifoWaterMark_6 : 16|8@1+ (1,0) [0|65535] "" Host
 SG_ BATT_canRXFifoWaterMark_6 : 0|8@1+ (1,0) [0|255] "" Host

BO_ 2642935815 BATT_diagnosticCan_7: 4 Battery
 SG_ BATT_canTXFifoSizeUsed_7 : 24|8@1+ (1,0) [0|255] "" Host
 SG_ BATT_canRXFifoSizeUsed_7 : 8|8@1+ (1,0) [0|255] "" Host
 SG_ BATT_canTXFifoWaterMark_7 : 16|8@1+ (1,0) [0|65535] "" Host
 SG_ BATT_canRXFifoWaterMark_7 : 0|8@1+ (1,0) [0|255] "" Host

BO_ 2642935816 BATT_diagnosticCan_8: 4 Battery
 SG_ BATT_canTXFifoSizeUsed_8 : 24|8@1+ (1,0) [0|255] "" Host
 SG_ BATT_canRXFifoSizeUsed_8 : 8|8@1+ (1,0) [0|255] "" Host
 SG_ BATT_canTXFifoWaterMark_8 : 16|8@1+ (1,0) [0|65535] "" Host
 SG_ BATT_canRXFifoWaterMark_8 : 0|8@1+ (1,0) [0|255] "" Host

BO_ 2642935817 BATT_diagnosticCan_9: 4 Battery
 SG_ BATT_canTXFifoSizeUsed_9 : 24|8@1+ (1,0) [0|255] "" Host
 SG_ BATT_canRXFifoSizeUsed_9 : 8|8@1+ (1,0) [0|255] "" Host
 SG_ BATT_canTXFifoWaterMark_9 : 16|8@1+ (1,0) [0|65535] "" Host
 SG_ BATT_canRXFifoWaterMark_9 : 0|8@1+ (1,0) [0|255] "" Host

BO_ 2642935818 BATT_diagnosticCan_10: 4 Battery
 SG_ BATT_canTXFifoSizeUsed_10 : 24|8@1+ (1,0) [0|255] "" Host
 SG_ BATT_canRXFifoSizeUsed_10 : 8|8@1+ (1,0) [0|255] "" Host
 SG_ BATT_canTXFifoWaterMark_10 : 16|8@1+ (1,0) [0|65535] "" Host
 SG_ BATT_canRXFifoWaterMark_10 : 0|8@1+ (1,0) [0|255] "" Host

BO_ 2642935819 BATT_diagnosticCan_11: 4 Battery
 SG_ BATT_canTXFifoSizeUsed_11 : 24|8@1+ (1,0) [0|255] "" Host
 SG_ BATT_canRXFifoSizeUsed_11 : 8|8@1+ (1,0) [0|255] "" Host
 SG_ BATT_canTXFifoWaterMark_11 : 16|8@1+ (1,0) [0|65535] "" Host
 SG_ BATT_canRXFifoWaterMark_11 : 0|8@1+ (1,0) [0|255] "" Host

BO_ 2643001344 BATT_diagnosticDeltaQ: 8 Battery
 SG_ BATT_deltaQTaskOsTimeDelta : 16|12@1+ (1,0) [0|4095] "" Host
 SG_ BATT_deltaQTaskOsTime : 32|32@1+ (1,0) [0|4294967295] "" Host
 SG_ BATT_deltaQFifoWaterMark : 12|4@1+ (1,0) [0|15] "" Host
 SG_ BATT_deltaQFifoSizeUsed : 8|4@1+ (1,0) [0|15] "" Host
 SG_ BATT_deltaQEvent : 28|4@1+ (1,0) [0|15] "" Host
 SG_ BATT_deltaQError : 3|3@1+ (1,0) [0|3] "" Host
 SG_ BATT_deltaQState : 0|3@1+ (1,0) [0|3] "" Host

BO_ 2671771648 BATT_boardADC_1_0: 6 Battery
 SG_ BATT_boardADC_LOAD_0 : 32|16@1- (0.01,0) [0|100] "V" Host
 SG_ BATT_boardADC_COMMON_DRAIN_0 : 16|16@1- (0.01,0) [0|100] "V" Host
 SG_ BATT_boardADC_PACK_0 : 0|16@1- (0.01,0) [0|100] "V" Host

BO_ 2671771649 BATT_boardADC_1_1: 6 Battery
 SG_ BATT_boardADC_LOAD_1 : 32|16@1- (0.01,0) [0|100] "V" Host
 SG_ BATT_boardADC_COMMON_DRAIN_1 : 16|16@1- (0.01,0) [0|100] "V" Host
 SG_ BATT_boardADC_PACK_1 : 0|16@1- (0.01,0) [0|100] "V" Host

BO_ 2671771650 BATT_boardADC_1_2: 6 Battery
 SG_ BATT_boardADC_LOAD_2 : 32|16@1- (0.01,0) [0|100] "V" Host
 SG_ BATT_boardADC_COMMON_DRAIN_2 : 16|16@1- (0.01,0) [0|100] "V" Host
 SG_ BATT_boardADC_PACK_2 : 0|16@1- (0.01,0) [0|100] "V" Host

BO_ 2671771651 BATT_boardADC_1_3: 6 Battery
 SG_ BATT_boardADC_LOAD_3 : 32|16@1- (0.01,0) [0|100] "V" Host
 SG_ BATT_boardADC_COMMON_DRAIN_3 : 16|16@1- (0.01,0) [0|100] "V" Host
 SG_ BATT_boardADC_PACK_3 : 0|16@1- (0.01,0) [0|100] "V" Host

BO_ 2671771652 BATT_boardADC_1_4: 6 Battery
 SG_ BATT_boardADC_LOAD_4 : 32|16@1- (0.01,0) [0|100] "V" Host
 SG_ BATT_boardADC_COMMON_DRAIN_4 : 16|16@1- (0.01,0) [0|100] "V" Host
 SG_ BATT_boardADC_PACK_4 : 0|16@1- (0.01,0) [0|100] "V" Host

BO_ 2671771653 BATT_boardADC_1_5: 6 Battery
 SG_ BATT_boardADC_LOAD_5 : 32|16@1- (0.01,0) [0|100] "V" Host
 SG_ BATT_boardADC_COMMON_DRAIN_5 : 16|16@1- (0.01,0) [0|100] "V" Host
 SG_ BATT_boardADC_PACK_5 : 0|16@1- (0.01,0) [0|100] "V" Host

BO_ 2671771654 BATT_boardADC_1_6: 6 Battery
 SG_ BATT_boardADC_LOAD_6 : 32|16@1- (0.01,0) [0|100] "V" Host
 SG_ BATT_boardADC_COMMON_DRAIN_6 : 16|16@1- (0.01,0) [0|100] "V" Host
 SG_ BATT_boardADC_PACK_6 : 0|16@1- (0.01,0) [0|100] "V" Host

BO_ 2671771655 BATT_boardADC_1_7: 6 Battery
 SG_ BATT_boardADC_LOAD_7 : 32|16@1- (0.01,0) [0|100] "V" Host
 SG_ BATT_boardADC_COMMON_DRAIN_7 : 16|16@1- (0.01,0) [0|100] "V" Host
 SG_ BATT_boardADC_PACK_7 : 0|16@1- (0.01,0) [0|100] "V" Host

BO_ 2671771656 BATT_boardADC_1_8: 6 Battery
 SG_ BATT_boardADC_LOAD_8 : 32|16@1- (0.01,0) [0|100] "V" Host
 SG_ BATT_boardADC_COMMON_DRAIN_8 : 16|16@1- (0.01,0) [0|100] "V" Host
 SG_ BATT_boardADC_PACK_8 : 0|16@1- (0.01,0) [0|100] "V" Host

BO_ 2671771657 BATT_boardADC_1_9: 6 Battery
 SG_ BATT_boardADC_LOAD_9 : 32|16@1- (0.01,0) [0|100] "V" Host
 SG_ BATT_boardADC_COMMON_DRAIN_9 : 16|16@1- (0.01,0) [0|100] "V" Host
 SG_ BATT_boardADC_PACK_9 : 0|16@1- (0.01,0) [0|100] "V" Host

BO_ 2671771658 BATT_boardADC_1_10: 6 Battery
 SG_ BATT_boardADC_LOAD_10 : 32|16@1- (0.01,0) [0|100] "V" Host
 SG_ BATT_boardADC_COMMON_DRAIN_10 : 16|16@1- (0.01,0) [0|100] "V" Host
 SG_ BATT_boardADC_PACK_10 : 0|16@1- (0.01,0) [0|100] "V" Host

BO_ 2671771659 BATT_boardADC_1_11: 6 Battery
 SG_ BATT_boardADC_LOAD_11 : 32|16@1- (0.01,0) [0|100] "V" Host
 SG_ BATT_boardADC_COMMON_DRAIN_11 : 16|16@1- (0.01,0) [0|100] "V" Host
 SG_ BATT_boardADC_PACK_11 : 0|16@1- (0.01,0) [0|100] "V" Host

BO_ 2672033792 BATT_boardADC_2_0: 6 Battery
 SG_ BATT_boardADC_12V_0 : 16|16@1- (0.01,0) [0|100] "V" Host
 SG_ BATT_boardADC_5V_0 : 0|16@1- (0.01,0) [0|100] "V" Host
 SG_ BATT_boardADC_3V3_0 : 32|16@1- (0.01,0) [0|100] "V" Host

BO_ 2672033793 BATT_boardADC_2_1: 6 Battery
 SG_ BATT_boardADC_12V_1 : 16|16@1- (0.01,0) [0|100] "V" Host
 SG_ BATT_boardADC_5V_1 : 0|16@1- (0.01,0) [0|100] "V" Host
 SG_ BATT_boardADC_3V3_1 : 32|16@1- (0.01,0) [0|100] "V" Host

BO_ 2672033794 BATT_boardADC_2_2: 6 Battery
 SG_ BATT_boardADC_12V_2 : 16|16@1- (0.01,0) [0|100] "V" Host
 SG_ BATT_boardADC_5V_2 : 0|16@1- (0.01,0) [0|100] "V" Host
 SG_ BATT_boardADC_3V3_2 : 32|16@1- (0.01,0) [0|100] "V" Host

BO_ 2672033795 BATT_boardADC_2_3: 6 Battery
 SG_ BATT_boardADC_12V_3 : 16|16@1- (0.01,0) [0|100] "V" Host
 SG_ BATT_boardADC_5V_3 : 0|16@1- (0.01,0) [0|100] "V" Host
 SG_ BATT_boardADC_3V3_3 : 32|16@1- (0.01,0) [0|100] "V" Host

BO_ 2672033796 BATT_boardADC_2_4: 6 Battery
 SG_ BATT_boardADC_12V_4 : 16|16@1- (0.01,0) [0|100] "V" Host
 SG_ BATT_boardADC_5V_4 : 0|16@1- (0.01,0) [0|100] "V" Host
 SG_ BATT_boardADC_3V3_4 : 32|16@1- (0.01,0) [0|100] "V" Host

BO_ 2672033797 BATT_boardADC_2_5: 6 Battery
 SG_ BATT_boardADC_12V_5 : 16|16@1- (0.01,0) [0|100] "V" Host
 SG_ BATT_boardADC_5V_5 : 0|16@1- (0.01,0) [0|100] "V" Host
 SG_ BATT_boardADC_3V3_5 : 32|16@1- (0.01,0) [0|100] "V" Host

BO_ 2672033798 BATT_boardADC_2_6: 6 Battery
 SG_ BATT_boardADC_12V_6 : 16|16@1- (0.01,0) [0|100] "V" Host
 SG_ BATT_boardADC_5V_6 : 0|16@1- (0.01,0) [0|100] "V" Host
 SG_ BATT_boardADC_3V3_6 : 32|16@1- (0.01,0) [0|100] "V" Host

BO_ 2672033799 BATT_boardADC_2_7: 6 Battery
 SG_ BATT_boardADC_12V_7 : 16|16@1- (0.01,0) [0|100] "V" Host
 SG_ BATT_boardADC_5V_7 : 0|16@1- (0.01,0) [0|100] "V" Host
 SG_ BATT_boardADC_3V3_7 : 32|16@1- (0.01,0) [0|100] "V" Host

BO_ 2672033800 BATT_boardADC_2_8: 6 Battery
 SG_ BATT_boardADC_12V_8 : 16|16@1- (0.01,0) [0|100] "V" Host
 SG_ BATT_boardADC_5V_8 : 0|16@1- (0.01,0) [0|100] "V" Host
 SG_ BATT_boardADC_3V3_8 : 32|16@1- (0.01,0) [0|100] "V" Host

BO_ 2672033801 BATT_boardADC_2_9: 6 Battery
 SG_ BATT_boardADC_12V_9 : 16|16@1- (0.01,0) [0|100] "V" Host
 SG_ BATT_boardADC_5V_9 : 0|16@1- (0.01,0) [0|100] "V" Host
 SG_ BATT_boardADC_3V3_9 : 32|16@1- (0.01,0) [0|100] "V" Host

BO_ 2672033802 BATT_boardADC_2_10: 6 Battery
 SG_ BATT_boardADC_12V_10 : 16|16@1- (0.01,0) [0|100] "V" Host
 SG_ BATT_boardADC_5V_10 : 0|16@1- (0.01,0) [0|100] "V" Host
 SG_ BATT_boardADC_3V3_10 : 32|16@1- (0.01,0) [0|100] "V" Host

BO_ 2672033803 BATT_boardADC_2_11: 6 Battery
 SG_ BATT_boardADC_12V_11 : 16|16@1- (0.01,0) [0|100] "V" Host
 SG_ BATT_boardADC_5V_11 : 0|16@1- (0.01,0) [0|100] "V" Host
 SG_ BATT_boardADC_3V3_11 : 32|16@1- (0.01,0) [0|100] "V" Host

BO_ 2672295936 BATT_boardADC_3_0: 6 Battery
 SG_ BATT_boardADC_SHUNT_TEMP_0 : 16|16@1- (0.01,0) [0|100] "V" Host
 SG_ BATT_boardADC_FET_TEMP_0 : 0|16@1- (0.01,0) [0|100] "V" Host
 SG_ BATT_boardADC_AMB_TEMP_0 : 32|16@1- (0.01,0) [0|100] "V" Host

BO_ 2672295937 BATT_boardADC_3_1: 6 Battery
 SG_ BATT_boardADC_SHUNT_TEMP_1 : 16|16@1- (0.01,0) [0|100] "V" Host
 SG_ BATT_boardADC_FET_TEMP_1 : 0|16@1- (0.01,0) [0|100] "V" Host
 SG_ BATT_boardADC_AMB_TEMP_1 : 32|16@1- (0.01,0) [0|100] "V" Host

BO_ 2672295938 BATT_boardADC_3_2: 6 Battery
 SG_ BATT_boardADC_SHUNT_TEMP_2 : 16|16@1- (0.01,0) [0|100] "V" Host
 SG_ BATT_boardADC_FET_TEMP_2 : 0|16@1- (0.01,0) [0|100] "V" Host
 SG_ BATT_boardADC_AMB_TEMP_2 : 32|16@1- (0.01,0) [0|100] "V" Host

BO_ 2672295939 BATT_boardADC_3_3: 6 Battery
 SG_ BATT_boardADC_SHUNT_TEMP_3 : 16|16@1- (0.01,0) [0|100] "V" Host
 SG_ BATT_boardADC_FET_TEMP_3 : 0|16@1- (0.01,0) [0|100] "V" Host
 SG_ BATT_boardADC_AMB_TEMP_3 : 32|16@1- (0.01,0) [0|100] "V" Host

BO_ 2672295940 BATT_boardADC_3_4: 6 Battery
 SG_ BATT_boardADC_SHUNT_TEMP_4 : 16|16@1- (0.01,0) [0|100] "V" Host
 SG_ BATT_boardADC_FET_TEMP_4 : 0|16@1- (0.01,0) [0|100] "V" Host
 SG_ BATT_boardADC_AMB_TEMP_4 : 32|16@1- (0.01,0) [0|100] "V" Host

BO_ 2672295941 BATT_boardADC_3_5: 6 Battery
 SG_ BATT_boardADC_SHUNT_TEMP_5 : 16|16@1- (0.01,0) [0|100] "V" Host
 SG_ BATT_boardADC_FET_TEMP_5 : 0|16@1- (0.01,0) [0|100] "V" Host
 SG_ BATT_boardADC_AMB_TEMP_5 : 32|16@1- (0.01,0) [0|100] "V" Host

BO_ 2672295942 BATT_boardADC_3_6: 6 Battery
 SG_ BATT_boardADC_SHUNT_TEMP_6 : 16|16@1- (0.01,0) [0|100] "V" Host
 SG_ BATT_boardADC_FET_TEMP_6 : 0|16@1- (0.01,0) [0|100] "V" Host
 SG_ BATT_boardADC_AMB_TEMP_6 : 32|16@1- (0.01,0) [0|100] "V" Host

BO_ 2672295943 BATT_boardADC_3_7: 6 Battery
 SG_ BATT_boardADC_SHUNT_TEMP_7 : 16|16@1- (0.01,0) [0|100] "V" Host
 SG_ BATT_boardADC_FET_TEMP_7 : 0|16@1- (0.01,0) [0|100] "V" Host
 SG_ BATT_boardADC_AMB_TEMP_7 : 32|16@1- (0.01,0) [0|100] "V" Host

BO_ 2672295944 BATT_boardADC_3_8: 6 Battery
 SG_ BATT_boardADC_SHUNT_TEMP_8 : 16|16@1- (0.01,0) [0|100] "V" Host
 SG_ BATT_boardADC_FET_TEMP_8 : 0|16@1- (0.01,0) [0|100] "V" Host
 SG_ BATT_boardADC_AMB_TEMP_8 : 32|16@1- (0.01,0) [0|100] "V" Host

BO_ 2672295945 BATT_boardADC_3_9: 6 Battery
 SG_ BATT_boardADC_SHUNT_TEMP_9 : 16|16@1- (0.01,0) [0|100] "V" Host
 SG_ BATT_boardADC_FET_TEMP_9 : 0|16@1- (0.01,0) [0|100] "V" Host
 SG_ BATT_boardADC_AMB_TEMP_9 : 32|16@1- (0.01,0) [0|100] "V" Host

BO_ 2672295946 BATT_boardADC_3_10: 6 Battery
 SG_ BATT_boardADC_SHUNT_TEMP_10 : 16|16@1- (0.01,0) [0|100] "V" Host
 SG_ BATT_boardADC_FET_TEMP_10 : 0|16@1- (0.01,0) [0|100] "V" Host
 SG_ BATT_boardADC_AMB_TEMP_10 : 32|16@1- (0.01,0) [0|100] "V" Host

BO_ 2672295947 BATT_boardADC_3_11: 6 Battery
 SG_ BATT_boardADC_SHUNT_TEMP_11 : 16|16@1- (0.01,0) [0|100] "V" Host
 SG_ BATT_boardADC_FET_TEMP_11 : 0|16@1- (0.01,0) [0|100] "V" Host
 SG_ BATT_boardADC_AMB_TEMP_11 : 32|16@1- (0.01,0) [0|100] "V" Host

CM_ BO_ 2626813958 "Harness impedance Delta ";
CM_ SG_ 2626813958 BATT_HrnsImpDelta_3_6 "Delat value of Harness Impedance
";
CM_ SG_ 2626813958 BATT_HrnsImpDelta_2_6 "Delat value of Harness Impedance
";
CM_ SG_ 2626813958 BATT_HrnsImpDelta_1_6 "Delat value of Harness Impedance
";
CM_ SG_ 2626813958 BATT_HrnsImpDelta_0_6 "Delat value of Harness Impedance
";
CM_ BO_ 2626813959 "Harness impedance Delta ";
CM_ SG_ 2626813959 BATT_HrnsImpDelta_3_7 "Delat value of Harness Impedance
";
CM_ SG_ 2626813959 BATT_HrnsImpDelta_2_7 "Delat value of Harness Impedance
";
CM_ SG_ 2626813959 BATT_HrnsImpDelta_1_7 "Delat value of Harness Impedance
";
CM_ SG_ 2626813959 BATT_HrnsImpDelta_0_7 "Delat value of Harness Impedance
";
CM_ BO_ 2626813960 "Harness impedance Delta ";
CM_ SG_ 2626813960 BATT_HrnsImpDelta_3_8 "Delat value of Harness Impedance
";
CM_ SG_ 2626813960 BATT_HrnsImpDelta_2_8 "Delat value of Harness Impedance
";
CM_ SG_ 2626813960 BATT_HrnsImpDelta_1_8 "Delat value of Harness Impedance
";
CM_ SG_ 2626813960 BATT_HrnsImpDelta_0_8 "Delat value of Harness Impedance
";
CM_ BO_ 2626813961 "Harness impedance Delta ";
CM_ SG_ 2626813961 BATT_HrnsImpDelta_3_9 "Delat value of Harness Impedance
";
CM_ SG_ 2626813961 BATT_HrnsImpDelta_2_9 "Delat value of Harness Impedance
";
CM_ SG_ 2626813961 BATT_HrnsImpDelta_1_9 "Delat value of Harness Impedance
";
CM_ SG_ 2626813961 BATT_HrnsImpDelta_0_9 "Delat value of Harness Impedance
";
CM_ BO_ 2626813962 "Harness impedance Delta ";
CM_ SG_ 2626813962 BATT_HrnsImpDelta_3_10 "Delat value of Harness Impedance
";
CM_ SG_ 2626813962 BATT_HrnsImpDelta_2_10 "Delat value of Harness Impedance
";
CM_ SG_ 2626813962 BATT_HrnsImpDelta_1_10 "Delat value of Harness Impedance
";
CM_ SG_ 2626813962 BATT_HrnsImpDelta_0_10 "Delat value of Harness Impedance
";
CM_ BO_ 2626813963 "Harness impedance Delta ";
CM_ SG_ 2626813963 BATT_HrnsImpDelta_3_11 "Delat value of Harness Impedance
";
CM_ SG_ 2626813963 BATT_HrnsImpDelta_2_11 "Delat value of Harness Impedance
";
CM_ SG_ 2626813963 BATT_HrnsImpDelta_1_11 "Delat value of Harness Impedance
";
CM_ SG_ 2626813963 BATT_HrnsImpDelta_0_11 "Delat value of Harness Impedance
";
CM_ BO_ 2626818048 "Harness impedance Delta ";
CM_ SG_ 2626818048 BATT_HrnsImpDelta_7_0 "Delat value of Harness Impedance
";
CM_ SG_ 2626818048 BATT_HrnsImpDelta_6_0 "Delat value of Harness Impedance
";
CM_ SG_ 2626818048 BATT_HrnsImpDelta_5_0 "Delat value of Harness Impedance
";
CM_ SG_ 2626818048 BATT_HrnsImpDelta_4_0 "Delat value of Harness Impedance
";
CM_ BO_ 2626818049 "Harness impedance Delta ";
CM_ SG_ 2626818049 BATT_HrnsImpDelta_7_1 "Delat value of Harness Impedance
";
CM_ SG_ 2626818049 BATT_HrnsImpDelta_6_1 "Delat value of Harness Impedance
";
CM_ SG_ 2626818049 BATT_HrnsImpDelta_5_1 "Delat value of Harness Impedance
";
CM_ SG_ 2626818049 BATT_HrnsImpDelta_4_1 "Delat value of Harness Impedance
";
CM_ BO_ 2626818050 "Harness impedance Delta ";
CM_ SG_ 2626818050 BATT_HrnsImpDelta_7_2 "Delat value of Harness Impedance
";
CM_ SG_ 2626818050 BATT_HrnsImpDelta_6_2 "Delat value of Harness Impedance
";
CM_ SG_ 2626818050 BATT_HrnsImpDelta_5_2 "Delat value of Harness Impedance
";
CM_ SG_ 2626818050 BATT_HrnsImpDelta_4_2 "Delat value of Harness Impedance
";
CM_ BO_ 2626818051 "Harness impedance Delta ";
CM_ SG_ 2626818051 BATT_HrnsImpDelta_7_3 "Delat value of Harness Impedance
";
CM_ SG_ 2626818051 BATT_HrnsImpDelta_6_3 "Delat value of Harness Impedance
";
CM_ SG_ 2626818051 BATT_HrnsImpDelta_5_3 "Delat value of Harness Impedance
";
CM_ SG_ 2626818051 BATT_HrnsImpDelta_4_3 "Delat value of Harness Impedance
";
CM_ BO_ 2626818052 "Harness impedance Delta ";
CM_ SG_ 2626818052 BATT_HrnsImpDelta_7_4 "Delat value of Harness Impedance
";
CM_ SG_ 2626818052 BATT_HrnsImpDelta_6_4 "Delat value of Harness Impedance
";
CM_ SG_ 2626818052 BATT_HrnsImpDelta_5_4 "Delat value of Harness Impedance
";
CM_ SG_ 2626818052 BATT_HrnsImpDelta_4_4 "Delat value of Harness Impedance
";
CM_ BO_ 2626818053 "Harness impedance Delta ";
CM_ SG_ 2626818053 BATT_HrnsImpDelta_7_5 "Delat value of Harness Impedance
";
CM_ SG_ 2626818053 BATT_HrnsImpDelta_6_5 "Delat value of Harness Impedance
";
CM_ SG_ 2626818053 BATT_HrnsImpDelta_5_5 "Delat value of Harness Impedance
";
CM_ SG_ 2626818053 BATT_HrnsImpDelta_4_5 "Delat value of Harness Impedance
";
CM_ BO_ 2626818054 "Harness impedance Delta ";
CM_ SG_ 2626818054 BATT_HrnsImpDelta_7_6 "Delat value of Harness Impedance
";
CM_ SG_ 2626818054 BATT_HrnsImpDelta_6_6 "Delat value of Harness Impedance
";
CM_ SG_ 2626818054 BATT_HrnsImpDelta_5_6 "Delat value of Harness Impedance
";
CM_ SG_ 2626818054 BATT_HrnsImpDelta_4_6 "Delat value of Harness Impedance
";
CM_ BO_ 2626818055 "Harness impedance Delta ";
CM_ SG_ 2626818055 BATT_HrnsImpDelta_7_7 "Delat value of Harness Impedance
";
CM_ SG_ 2626818055 BATT_HrnsImpDelta_6_7 "Delat value of Harness Impedance
";
CM_ SG_ 2626818055 BATT_HrnsImpDelta_5_7 "Delat value of Harness Impedance
";
CM_ SG_ 2626818055 BATT_HrnsImpDelta_4_7 "Delat value of Harness Impedance
";
CM_ BO_ 2626818056 "Harness impedance Delta ";
CM_ SG_ 2626818056 BATT_HrnsImpDelta_7_8 "Delat value of Harness Impedance
";
CM_ SG_ 2626818056 BATT_HrnsImpDelta_6_8 "Delat value of Harness Impedance
";
CM_ SG_ 2626818056 BATT_HrnsImpDelta_5_8 "Delat value of Harness Impedance
";
CM_ SG_ 2626818056 BATT_HrnsImpDelta_4_8 "Delat value of Harness Impedance
";
CM_ BO_ 2626818057 "Harness impedance Delta ";
CM_ SG_ 2626818057 BATT_HrnsImpDelta_7_9 "Delat value of Harness Impedance
";
CM_ SG_ 2626818057 BATT_HrnsImpDelta_6_9 "Delat value of Harness Impedance
";
CM_ SG_ 2626818057 BATT_HrnsImpDelta_5_9 "Delat value of Harness Impedance
";
CM_ SG_ 2626818057 BATT_HrnsImpDelta_4_9 "Delat value of Harness Impedance
";
CM_ BO_ 2626818058 "Harness impedance Delta ";
CM_ SG_ 2626818058 BATT_HrnsImpDelta_7_10 "Delat value of Harness Impedance
";
CM_ SG_ 2626818058 BATT_HrnsImpDelta_6_10 "Delat value of Harness Impedance
";
CM_ SG_ 2626818058 BATT_HrnsImpDelta_5_10 "Delat value of Harness Impedance
";
CM_ SG_ 2626818058 BATT_HrnsImpDelta_4_10 "Delat value of Harness Impedance
";
CM_ BO_ 2626818059 "Harness impedance Delta ";
CM_ SG_ 2626818059 BATT_HrnsImpDelta_7_11 "Delat value of Harness Impedance
";
CM_ SG_ 2626818059 BATT_HrnsImpDelta_6_11 "Delat value of Harness Impedance
";
CM_ SG_ 2626818059 BATT_HrnsImpDelta_5_11 "Delat value of Harness Impedance
";
CM_ SG_ 2626818059 BATT_HrnsImpDelta_4_11 "Delat value of Harness Impedance
";
CM_ BO_ 2626822144 "Harness impedance Delta ";
CM_ SG_ 2626822144 BATT_HrnsImpDelta_11_0 "Delat value of Harness Impedance
";
CM_ SG_ 2626822144 BATT_HrnsImpDelta_10_0 "Delat value of Harness Impedance
";
CM_ SG_ 2626822144 BATT_HrnsImpDelta_9_0 "Delat value of Harness Impedance
";
CM_ SG_ 2626822144 BATT_HrnsImpDelta_8_0 "Delat value of Harness Impedance
";
CM_ BO_ 2626822145 "Harness impedance Delta ";
CM_ SG_ 2626822145 BATT_HrnsImpDelta_11_1 "Delat value of Harness Impedance
";
CM_ SG_ 2626822145 BATT_HrnsImpDelta_10_1 "Delat value of Harness Impedance
";
CM_ SG_ 2626822145 BATT_HrnsImpDelta_9_1 "Delat value of Harness Impedance
";
CM_ SG_ 2626822145 BATT_HrnsImpDelta_8_1 "Delat value of Harness Impedance
";
CM_ BO_ 2626822146 "Harness impedance Delta ";
CM_ SG_ 2626822146 BATT_HrnsImpDelta_11_2 "Delat value of Harness Impedance
";
CM_ SG_ 2626822146 BATT_HrnsImpDelta_10_2 "Delat value of Harness Impedance
";
CM_ SG_ 2626822146 BATT_HrnsImpDelta_9_2 "Delat value of Harness Impedance
";
CM_ SG_ 2626822146 BATT_HrnsImpDelta_8_2 "Delat value of Harness Impedance
";
CM_ BO_ 2626822147 "Harness impedance Delta ";
CM_ SG_ 2626822147 BATT_HrnsImpDelta_11_3 "Delat value of Harness Impedance
";
CM_ SG_ 2626822147 BATT_HrnsImpDelta_10_3 "Delat value of Harness Impedance
";
CM_ SG_ 2626822147 BATT_HrnsImpDelta_9_3 "Delat value of Harness Impedance
";
CM_ SG_ 2626822147 BATT_HrnsImpDelta_8_3 "Delat value of Harness Impedance
";
CM_ BO_ 2626822148 "Harness impedance Delta ";
CM_ SG_ 2626822148 BATT_HrnsImpDelta_11_4 "Delat value of Harness Impedance
";
CM_ SG_ 2626822148 BATT_HrnsImpDelta_10_4 "Delat value of Harness Impedance
";
CM_ SG_ 2626822148 BATT_HrnsImpDelta_9_4 "Delat value of Harness Impedance
";
CM_ SG_ 2626822148 BATT_HrnsImpDelta_8_4 "Delat value of Harness Impedance
";
CM_ BO_ 2626822149 "Harness impedance Delta ";
CM_ SG_ 2626822149 BATT_HrnsImpDelta_11_5 "Delat value of Harness Impedance
";
CM_ SG_ 2626822149 BATT_HrnsImpDelta_10_5 "Delat value of Harness Impedance
";
CM_ SG_ 2626822149 BATT_HrnsImpDelta_9_5 "Delat value of Harness Impedance
";
CM_ SG_ 2626822149 BATT_HrnsImpDelta_8_5 "Delat value of Harness Impedance
";
CM_ BO_ 2626822150 "Harness impedance Delta ";
CM_ SG_ 2626822150 BATT_HrnsImpDelta_11_6 "Delat value of Harness Impedance
";
CM_ SG_ 2626822150 BATT_HrnsImpDelta_10_6 "Delat value of Harness Impedance
";
CM_ SG_ 2626822150 BATT_HrnsImpDelta_9_6 "Delat value of Harness Impedance
";
CM_ SG_ 2626822150 BATT_HrnsImpDelta_8_6 "Delat value of Harness Impedance
";
CM_ BO_ 2626822151 "Harness impedance Delta ";
CM_ SG_ 2626822151 BATT_HrnsImpDelta_11_7 "Delat value of Harness Impedance
";
CM_ SG_ 2626822151 BATT_HrnsImpDelta_10_7 "Delat value of Harness Impedance
";
CM_ SG_ 2626822151 BATT_HrnsImpDelta_9_7 "Delat value of Harness Impedance
";
CM_ SG_ 2626822151 BATT_HrnsImpDelta_8_7 "Delat value of Harness Impedance
";
CM_ BO_ 2626822152 "Harness impedance Delta ";
CM_ SG_ 2626822152 BATT_HrnsImpDelta_11_8 "Delat value of Harness Impedance
";
CM_ SG_ 2626822152 BATT_HrnsImpDelta_10_8 "Delat value of Harness Impedance
";
CM_ SG_ 2626822152 BATT_HrnsImpDelta_9_8 "Delat value of Harness Impedance
";
CM_ SG_ 2626822152 BATT_HrnsImpDelta_8_8 "Delat value of Harness Impedance
";
CM_ BO_ 2626822153 "Harness impedance Delta ";
CM_ SG_ 2626822153 BATT_HrnsImpDelta_11_9 "Delat value of Harness Impedance
";
CM_ SG_ 2626822153 BATT_HrnsImpDelta_10_9 "Delat value of Harness Impedance
";
CM_ SG_ 2626822153 BATT_HrnsImpDelta_9_9 "Delat value of Harness Impedance
";
CM_ SG_ 2626822153 BATT_HrnsImpDelta_8_9 "Delat value of Harness Impedance
";
CM_ BO_ 2626822154 "Harness impedance Delta ";
CM_ SG_ 2626822154 BATT_HrnsImpDelta_11_10 "Delat value of Harness Impedance
";
CM_ SG_ 2626822154 BATT_HrnsImpDelta_10_10 "Delat value of Harness Impedance
";
CM_ SG_ 2626822154 BATT_HrnsImpDelta_9_10 "Delat value of Harness Impedance
";
CM_ SG_ 2626822154 BATT_HrnsImpDelta_8_10 "Delat value of Harness Impedance
";
CM_ BO_ 2626822155 "Harness impedance Delta ";
CM_ SG_ 2626822155 BATT_HrnsImpDelta_11_11 "Delat value of Harness Impedance
";
CM_ SG_ 2626822155 BATT_HrnsImpDelta_10_11 "Delat value of Harness Impedance
";
CM_ SG_ 2626822155 BATT_HrnsImpDelta_9_11 "Delat value of Harness Impedance
";
CM_ SG_ 2626822155 BATT_HrnsImpDelta_8_11 "Delat value of Harness Impedance
";
CM_ BO_ 2626826240 "Harness impedance Delta ";
CM_ SG_ 2626826240 BATT_HrnsImpDelta_14_0 "Delat value of Harness Impedance
";
CM_ SG_ 2626826240 BATT_HrnsImpDelta_13_0 "Delat value of Harness Impedance
";
CM_ SG_ 2626826240 BATT_HrnsImpDelta_12_0 "Delat value of Harness Impedance
";
CM_ BO_ 2626826241 "Harness impedance Delta ";
CM_ SG_ 2626826241 BATT_HrnsImpDelta_14_1 "Delat value of Harness Impedance
";
CM_ SG_ 2626826241 BATT_HrnsImpDelta_13_1 "Delat value of Harness Impedance
";
CM_ SG_ 2626826241 BATT_HrnsImpDelta_12_1 "Delat value of Harness Impedance
";
CM_ BO_ 2626826242 "Harness impedance Delta ";
CM_ SG_ 2626826242 BATT_HrnsImpDelta_14_2 "Delat value of Harness Impedance
";
CM_ SG_ 2626826242 BATT_HrnsImpDelta_13_2 "Delat value of Harness Impedance
";
CM_ SG_ 2626826242 BATT_HrnsImpDelta_12_2 "Delat value of Harness Impedance
";
CM_ BO_ 2626826243 "Harness impedance Delta ";
CM_ SG_ 2626826243 BATT_HrnsImpDelta_14_3 "Delat value of Harness Impedance
";
CM_ SG_ 2626826243 BATT_HrnsImpDelta_13_3 "Delat value of Harness Impedance
";
CM_ SG_ 2626826243 BATT_HrnsImpDelta_12_3 "Delat value of Harness Impedance
";
CM_ BO_ 2626826244 "Harness impedance Delta ";
CM_ SG_ 2626826244 BATT_HrnsImpDelta_14_4 "Delat value of Harness Impedance
";
CM_ SG_ 2626826244 BATT_HrnsImpDelta_13_4 "Delat value of Harness Impedance
";
CM_ SG_ 2626826244 BATT_HrnsImpDelta_12_4 "Delat value of Harness Impedance
";
CM_ BO_ 2626826245 "Harness impedance Delta ";
CM_ SG_ 2626826245 BATT_HrnsImpDelta_14_5 "Delat value of Harness Impedance
";
CM_ SG_ 2626826245 BATT_HrnsImpDelta_13_5 "Delat value of Harness Impedance
";
CM_ SG_ 2626826245 BATT_HrnsImpDelta_12_5 "Delat value of Harness Impedance
";
CM_ BO_ 2626826246 "Harness impedance Delta ";
CM_ SG_ 2626826246 BATT_HrnsImpDelta_14_6 "Delat value of Harness Impedance
";
CM_ SG_ 2626826246 BATT_HrnsImpDelta_13_6 "Delat value of Harness Impedance
";
CM_ SG_ 2626826246 BATT_HrnsImpDelta_12_6 "Delat value of Harness Impedance
";
CM_ BO_ 2626826247 "Harness impedance Delta ";
CM_ SG_ 2626826247 BATT_HrnsImpDelta_14_7 "Delat value of Harness Impedance
";
CM_ SG_ 2626826247 BATT_HrnsImpDelta_13_7 "Delat value of Harness Impedance
";
CM_ SG_ 2626826247 BATT_HrnsImpDelta_12_7 "Delat value of Harness Impedance
";
CM_ BO_ 2626826248 "Harness impedance Delta ";
CM_ SG_ 2626826248 BATT_HrnsImpDelta_14_8 "Delat value of Harness Impedance
";
CM_ SG_ 2626826248 BATT_HrnsImpDelta_13_8 "Delat value of Harness Impedance
";
CM_ SG_ 2626826248 BATT_HrnsImpDelta_12_8 "Delat value of Harness Impedance
";
CM_ BO_ 2626826249 "Harness impedance Delta ";
CM_ SG_ 2626826249 BATT_HrnsImpDelta_14_9 "Delat value of Harness Impedance
";
CM_ SG_ 2626826249 BATT_HrnsImpDelta_13_9 "Delat value of Harness Impedance
";
CM_ SG_ 2626826249 BATT_HrnsImpDelta_12_9 "Delat value of Harness Impedance
";
CM_ BO_ 2626826250 "Harness impedance Delta ";
CM_ SG_ 2626826250 BATT_HrnsImpDelta_14_10 "Delat value of Harness Impedance
";
CM_ SG_ 2626826250 BATT_HrnsImpDelta_13_10 "Delat value of Harness Impedance
";
CM_ SG_ 2626826250 BATT_HrnsImpDelta_12_10 "Delat value of Harness Impedance
";
CM_ BO_ 2626826251 "Harness impedance Delta ";
CM_ SG_ 2626826251 BATT_HrnsImpDelta_14_11 "Delat value of Harness Impedance
";
CM_ SG_ 2626826251 BATT_HrnsImpDelta_13_11 "Delat value of Harness Impedance
";
CM_ SG_ 2626826251 BATT_HrnsImpDelta_12_11 "Delat value of Harness Impedance
";
CM_ BO_ 2626945024 "Balancing status";
CM_ BO_ 2626945025 "Balancing status";
CM_ BO_ 2626945026 "Balancing status";
CM_ BO_ 2626945027 "Balancing status";
CM_ BO_ 2626945028 "Balancing status";
CM_ BO_ 2626945029 "Balancing status";
CM_ BO_ 2626945030 "Balancing status";
CM_ BO_ 2626945031 "Balancing status";
CM_ BO_ 2626945032 "Balancing status";
CM_ BO_ 2626945033 "Balancing status";
CM_ BO_ 2626945034 "Balancing status";
CM_ BO_ 2626945035 "Balancing status";
CM_ BO_ 2629828608 "Total Ah charged and discharged counters";
CM_ SG_ 2629828608 BATT_ahDchTotal_0 "Total Ah discharged";
CM_ SG_ 2629828608 BATT_ahChgTotal_0 "Total Ah charged";
CM_ BO_ 2629828609 "Total Ah charged and discharged counters";
CM_ SG_ 2629828609 BATT_ahDchTotal_1 "Total Ah discharged";
CM_ SG_ 2629828609 BATT_ahChgTotal_1 "Total Ah charged";
CM_ BO_ 2629828610 "Total Ah charged and discharged counters";
CM_ SG_ 2629828610 BATT_ahDchTotal_2 "Total Ah discharged";
CM_ SG_ 2629828610 BATT_ahChgTotal_2 "Total Ah charged";
CM_ BO_ 2629828611 "Total Ah charged and discharged counters";
CM_ SG_ 2629828611 BATT_ahDchTotal_3 "Total Ah discharged";
CM_ SG_ 2629828611 BATT_ahChgTotal_3 "Total Ah charged";
CM_ BO_ 2629828612 "Total Ah charged and discharged counters";
CM_ SG_ 2629828612 BATT_ahDchTotal_4 "Total Ah discharged";
CM_ SG_ 2629828612 BATT_ahChgTotal_4 "Total Ah charged";
CM_ BO_ 2629828613 "Total Ah charged and discharged counters";
CM_ SG_ 2629828613 BATT_ahDchTotal_5 "Total Ah discharged";
CM_ SG_ 2629828613 BATT_ahChgTotal_5 "Total Ah charged";
CM_ BO_ 2629828614 "Total Ah charged and discharged counters";
CM_ SG_ 2629828614 BATT_ahDchTotal_6 "Total Ah discharged";
CM_ SG_ 2629828614 BATT_ahChgTotal_6 "Total Ah charged";
CM_ BO_ 2629828615 "Total Ah charged and discharged counters";
CM_ SG_ 2629828615 BATT_ahDchTotal_7 "Total Ah discharged";
CM_ SG_ 2629828615 BATT_ahChgTotal_7 "Total Ah charged";
CM_ BO_ 2629828616 "Total Ah charged and discharged counters";
CM_ SG_ 2629828616 BATT_ahDchTotal_8 "Total Ah discharged";
CM_ SG_ 2629828616 BATT_ahChgTotal_8 "Total Ah charged";
CM_ BO_ 2629828617 "Total Ah charged and discharged counters";
CM_ SG_ 2629828617 BATT_ahDchTotal_9 "Total Ah discharged";
CM_ SG_ 2629828617 BATT_ahChgTotal_9 "Total Ah charged";
CM_ BO_ 2629828618 "Total Ah charged and discharged counters";
CM_ SG_ 2629828618 BATT_ahDchTotal_10 "Total Ah discharged";
CM_ SG_ 2629828618 BATT_ahChgTotal_10 "Total Ah charged";
CM_ BO_ 2629828619 "Total Ah charged and discharged counters";
CM_ SG_ 2629828619 BATT_ahDchTotal_11 "Total Ah discharged";
CM_ SG_ 2629828619 BATT_ahChgTotal_11 "Total Ah charged";
CM_ BO_ 2630090752 "State of charge of bricks 1-4";
CM_ SG_ 2630090752 BATT_socBrick04_0 "State of charge of brick 4";
CM_ SG_ 2630090752 BATT_socBrick03_0 "State of charge of brick 3";
CM_ SG_ 2630090752 BATT_socBrick02_0 "State of charge of brick 2";
CM_ SG_ 2630090752 BATT_socBrick01_0 "State of charge of brick 1";
CM_ BO_ 2630090753 "State of charge of bricks 1-4";
CM_ SG_ 2630090753 BATT_socBrick04_1 "State of charge of brick 4";
CM_ SG_ 2630090753 BATT_socBrick03_1 "State of charge of brick 3";
CM_ SG_ 2630090753 BATT_socBrick02_1 "State of charge of brick 2";
CM_ SG_ 2630090753 BATT_socBrick01_1 "State of charge of brick 1";
CM_ BO_ 2630090754 "State of charge of bricks 1-4";
CM_ SG_ 2630090754 BATT_socBrick04_2 "State of charge of brick 4";
CM_ SG_ 2630090754 BATT_socBrick03_2 "State of charge of brick 3";
CM_ SG_ 2630090754 BATT_socBrick02_2 "State of charge of brick 2";
CM_ SG_ 2630090754 BATT_socBrick01_2 "State of charge of brick 1";
CM_ BO_ 2630090755 "State of charge of bricks 1-4";
CM_ SG_ 2630090755 BATT_socBrick04_3 "State of charge of brick 4";
CM_ SG_ 2630090755 BATT_socBrick03_3 "State of charge of brick 3";
CM_ SG_ 2630090755 BATT_socBrick02_3 "State of charge of brick 2";
CM_ SG_ 2630090755 BATT_socBrick01_3 "State of charge of brick 1";
CM_ BO_ 2630090756 "State of charge of bricks 1-4";
CM_ SG_ 2630090756 BATT_socBrick04_4 "State of charge of brick 4";
CM_ SG_ 2630090756 BATT_socBrick03_4 "State of charge of brick 3";
CM_ SG_ 2630090756 BATT_socBrick02_4 "State of charge of brick 2";
CM_ SG_ 2630090756 BATT_socBrick01_4 "State of charge of brick 1";
CM_ BO_ 2630090757 "State of charge of bricks 1-4";
CM_ SG_ 2630090757 BATT_socBrick04_5 "State of charge of brick 4";
CM_ SG_ 2630090757 BATT_socBrick03_5 "State of charge of brick 3";
CM_ SG_ 2630090757 BATT_socBrick02_5 "State of charge of brick 2";
CM_ SG_ 2630090757 BATT_socBrick01_5 "State of charge of brick 1";
CM_ BO_ 2630090758 "State of charge of bricks 1-4";
CM_ SG_ 2630090758 BATT_socBrick04_6 "State of charge of brick 4";
CM_ SG_ 2630090758 BATT_socBrick03_6 "State of charge of brick 3";
CM_ SG_ 2630090758 BATT_socBrick02_6 "State of charge of brick 2";
CM_ SG_ 2630090758 BATT_socBrick01_6 "State of charge of brick 1";
CM_ BO_ 2630090759 "State of charge of bricks 1-4";
CM_ SG_ 2630090759 BATT_socBrick04_7 "State of charge of brick 4";
CM_ SG_ 2630090759 BATT_socBrick03_7 "State of charge of brick 3";
CM_ SG_ 2630090759 BATT_socBrick02_7 "State of charge of brick 2";
CM_ SG_ 2630090759 BATT_socBrick01_7 "State of charge of brick 1";
CM_ BO_ 2630090760 "State of charge of bricks 1-4";
CM_ SG_ 2630090760 BATT_socBrick04_8 "State of charge of brick 4";
CM_ SG_ 2630090760 BATT_socBrick03_8 "State of charge of brick 3";
CM_ SG_ 2630090760 BATT_socBrick02_8 "State of charge of brick 2";
CM_ SG_ 2630090760 BATT_socBrick01_8 "State of charge of brick 1";
CM_ BO_ 2630090761 "State of charge of bricks 1-4";
CM_ SG_ 2630090761 BATT_socBrick04_9 "State of charge of brick 4";
CM_ SG_ 2630090761 BATT_socBrick03_9 "State of charge of brick 3";
CM_ SG_ 2630090761 BATT_socBrick02_9 "State of charge of brick 2";
CM_ SG_ 2630090761 BATT_socBrick01_9 "State of charge of brick 1";
CM_ BO_ 2630090762 "State of charge of bricks 1-4";
CM_ SG_ 2630090762 BATT_socBrick04_10 "State of charge of brick 4";
CM_ SG_ 2630090762 BATT_socBrick03_10 "State of charge of brick 3";
CM_ SG_ 2630090762 BATT_socBrick02_10 "State of charge of brick 2";
CM_ SG_ 2630090762 BATT_socBrick01_10 "State of charge of brick 1";
CM_ BO_ 2630090763 "State of charge of bricks 1-4";
CM_ SG_ 2630090763 BATT_socBrick04_11 "State of charge of brick 4";
CM_ SG_ 2630090763 BATT_socBrick03_11 "State of charge of brick 3";
CM_ SG_ 2630090763 BATT_socBrick02_11 "State of charge of brick 2";
CM_ SG_ 2630090763 BATT_socBrick01_11 "State of charge of brick 1";
CM_ BO_ 2630352896 "State of charge of bricks 5-8";
CM_ SG_ 2630352896 BATT_socBrick08_0 "State of charge of brick 8";
CM_ SG_ 2630352896 BATT_socBrick07_0 "State of charge of brick 7";
CM_ SG_ 2630352896 BATT_socBrick06_0 "State of charge of brick 6";
CM_ SG_ 2630352896 BATT_socBrick05_0 "State of charge of brick 5";
CM_ BO_ 2630352897 "State of charge of bricks 5-8";
CM_ SG_ 2630352897 BATT_socBrick08_1 "State of charge of brick 8";
CM_ SG_ 2630352897 BATT_socBrick07_1 "State of charge of brick 7";
CM_ SG_ 2630352897 BATT_socBrick06_1 "State of charge of brick 6";
CM_ SG_ 2630352897 BATT_socBrick05_1 "State of charge of brick 5";
CM_ BO_ 2630352898 "State of charge of bricks 5-8";
CM_ SG_ 2630352898 BATT_socBrick08_2 "State of charge of brick 8";
CM_ SG_ 2630352898 BATT_socBrick07_2 "State of charge of brick 7";
CM_ SG_ 2630352898 BATT_socBrick06_2 "State of charge of brick 6";
CM_ SG_ 2630352898 BATT_socBrick05_2 "State of charge of brick 5";
CM_ BO_ 2630352899 "State of charge of bricks 5-8";
CM_ SG_ 2630352899 BATT_socBrick08_3 "State of charge of brick 8";
CM_ SG_ 2630352899 BATT_socBrick07_3 "State of charge of brick 7";
CM_ SG_ 2630352899 BATT_socBrick06_3 "State of charge of brick 6";
CM_ SG_ 2630352899 BATT_socBrick05_3 "State of charge of brick 5";
CM_ BO_ 2630352900 "State of charge of bricks 5-8";
CM_ SG_ 2630352900 BATT_socBrick08_4 "State of charge of brick 8";
CM_ SG_ 2630352900 BATT_socBrick07_4 "State of charge of brick 7";
CM_ SG_ 2630352900 BATT_socBrick06_4 "State of charge of brick 6";
CM_ SG_ 2630352900 BATT_socBrick05_4 "State of charge of brick 5";
CM_ BO_ 2630352901 "State of charge of bricks 5-8";
CM_ SG_ 2630352901 BATT_socBrick08_5 "State of charge of brick 8";
CM_ SG_ 2630352901 BATT_socBrick07_5 "State of charge of brick 7";
CM_ SG_ 2630352901 BATT_socBrick06_5 "State of charge of brick 6";
CM_ SG_ 2630352901 BATT_socBrick05_5 "State of charge of brick 5";
CM_ BO_ 2630352902 "State of charge of bricks 5-8";
CM_ SG_ 2630352902 BATT_socBrick08_6 "State of charge of brick 8";
CM_ SG_ 2630352902 BATT_socBrick07_6 "State of charge of brick 7";
CM_ SG_ 2630352902 BATT_socBrick06_6 "State of charge of brick 6";
CM_ SG_ 2630352902 BATT_socBrick05_6 "State of charge of brick 5";
CM_ BO_ 2630352903 "State of charge of bricks 5-8";
CM_ SG_ 2630352903 BATT_socBrick08_7 "State of charge of brick 8";
CM_ SG_ 2630352903 BATT_socBrick07_7 "State of charge of brick 7";
CM_ SG_ 2630352903 BATT_socBrick06_7 "State of charge of brick 6";
CM_ SG_ 2630352903 BATT_socBrick05_7 "State of charge of brick 5";
CM_ BO_ 2630352904 "State of charge of bricks 5-8";
CM_ SG_ 2630352904 BATT_socBrick08_8 "State of charge of brick 8";
CM_ SG_ 2630352904 BATT_socBrick07_8 "State of charge of brick 7";
CM_ SG_ 2630352904 BATT_socBrick06_8 "State of charge of brick 6";
CM_ SG_ 2630352904 BATT_socBrick05_8 "State of charge of brick 5";
CM_ BO_ 2630352905 "State of charge of bricks 5-8";
CM_ SG_ 2630352905 BATT_socBrick08_9 "State of charge of brick 8";
CM_ SG_ 2630352905 BATT_socBrick07_9 "State of charge of brick 7";
CM_ SG_ 2630352905 BATT_socBrick06_9 "State of charge of brick 6";
CM_ SG_ 2630352905 BATT_socBrick05_9 "State of charge of brick 5";
CM_ BO_ 2630352906 "State of charge of bricks 5-8";
CM_ SG_ 2630352906 BATT_socBrick08_10 "State of charge of brick 8";
CM_ SG_ 2630352906 BATT_socBrick07_10 "State of charge of brick 7";
CM_ SG_ 2630352906 BATT_socBrick06_10 "State of charge of brick 6";
CM_ SG_ 2630352906 BATT_socBrick05_10 "State of charge of brick 5";
CM_ BO_ 2630352907 "State of charge of bricks 5-8";
CM_ SG_ 2630352907 BATT_socBrick08_11 "State of charge of brick 8";
CM_ SG_ 2630352907 BATT_socBrick07_11 "State of charge of brick 7";
CM_ SG_ 2630352907 BATT_socBrick06_11 "State of charge of brick 6";
CM_ SG_ 2630352907 BATT_socBrick05_11 "State of charge of brick 5";
CM_ BO_ 2630615040 "State of charge of bricks 9-12";
CM_ SG_ 2630615040 BATT_socBrick12_0 "State of charge of brick 12";
CM_ SG_ 2630615040 BATT_socBrick11_0 "State of charge of brick 11";
CM_ SG_ 2630615040 BATT_socBrick09_0 "State of charge of brick 9";
CM_ SG_ 2630615040 BATT_socBrick10_0 "State of charge of brick 10";
CM_ BO_ 2630615041 "State of charge of bricks 9-12";
CM_ SG_ 2630615041 BATT_socBrick12_1 "State of charge of brick 12";
CM_ SG_ 2630615041 BATT_socBrick11_1 "State of charge of brick 11";
CM_ SG_ 2630615041 BATT_socBrick09_1 "State of charge of brick 9";
CM_ SG_ 2630615041 BATT_socBrick10_1 "State of charge of brick 10";
CM_ BO_ 2630615042 "State of charge of bricks 9-12";
CM_ SG_ 2630615042 BATT_socBrick12_2 "State of charge of brick 12";
CM_ SG_ 2630615042 BATT_socBrick11_2 "State of charge of brick 11";
CM_ SG_ 2630615042 BATT_socBrick09_2 "State of charge of brick 9";
CM_ SG_ 2630615042 BATT_socBrick10_2 "State of charge of brick 10";
CM_ BO_ 2630615043 "State of charge of bricks 9-12";
CM_ SG_ 2630615043 BATT_socBrick12_3 "State of charge of brick 12";
CM_ SG_ 2630615043 BATT_socBrick11_3 "State of charge of brick 11";
CM_ SG_ 2630615043 BATT_socBrick09_3 "State of charge of brick 9";
CM_ SG_ 2630615043 BATT_socBrick10_3 "State of charge of brick 10";
CM_ BO_ 2630615044 "State of charge of bricks 9-12";
CM_ SG_ 2630615044 BATT_socBrick12_4 "State of charge of brick 12";
CM_ SG_ 2630615044 BATT_socBrick11_4 "State of charge of brick 11";
CM_ SG_ 2630615044 BATT_socBrick09_4 "State of charge of brick 9";
CM_ SG_ 2630615044 BATT_socBrick10_4 "State of charge of brick 10";
CM_ BO_ 2630615045 "State of charge of bricks 9-12";
CM_ SG_ 2630615045 BATT_socBrick12_5 "State of charge of brick 12";
CM_ SG_ 2630615045 BATT_socBrick11_5 "State of charge of brick 11";
CM_ SG_ 2630615045 BATT_socBrick09_5 "State of charge of brick 9";
CM_ SG_ 2630615045 BATT_socBrick10_5 "State of charge of brick 10";
CM_ BO_ 2630615046 "State of charge of bricks 9-12";
CM_ SG_ 2630615046 BATT_socBrick12_6 "State of charge of brick 12";
CM_ SG_ 2630615046 BATT_socBrick11_6 "State of charge of brick 11";
CM_ SG_ 2630615046 BATT_socBrick09_6 "State of charge of brick 9";
CM_ SG_ 2630615046 BATT_socBrick10_6 "State of charge of brick 10";
CM_ BO_ 2630615047 "State of charge of bricks 9-12";
CM_ SG_ 2630615047 BATT_socBrick12_7 "State of charge of brick 12";
CM_ SG_ 2630615047 BATT_socBrick11_7 "State of charge of brick 11";
CM_ SG_ 2630615047 BATT_socBrick09_7 "State of charge of brick 9";
CM_ SG_ 2630615047 BATT_socBrick10_7 "State of charge of brick 10";
CM_ BO_ 2630615048 "State of charge of bricks 9-12";
CM_ SG_ 2630615048 BATT_socBrick12_8 "State of charge of brick 12";
CM_ SG_ 2630615048 BATT_socBrick11_8 "State of charge of brick 11";
CM_ SG_ 2630615048 BATT_socBrick09_8 "State of charge of brick 9";
CM_ SG_ 2630615048 BATT_socBrick10_8 "State of charge of brick 10";
CM_ BO_ 2630615049 "State of charge of bricks 9-12";
CM_ SG_ 2630615049 BATT_socBrick12_9 "State of charge of brick 12";
CM_ SG_ 2630615049 BATT_socBrick11_9 "State of charge of brick 11";
CM_ SG_ 2630615049 BATT_socBrick09_9 "State of charge of brick 9";
CM_ SG_ 2630615049 BATT_socBrick10_9 "State of charge of brick 10";
CM_ BO_ 2630615050 "State of charge of bricks 9-12";
CM_ SG_ 2630615050 BATT_socBrick12_10 "State of charge of brick 12";
CM_ SG_ 2630615050 BATT_socBrick11_10 "State of charge of brick 11";
CM_ SG_ 2630615050 BATT_socBrick09_10 "State of charge of brick 9";
CM_ SG_ 2630615050 BATT_socBrick10_10 "State of charge of brick 10";
CM_ BO_ 2630615051 "State of charge of bricks 9-12";
CM_ SG_ 2630615051 BATT_socBrick12_11 "State of charge of brick 12";
CM_ SG_ 2630615051 BATT_socBrick11_11 "State of charge of brick 11";
CM_ SG_ 2630615051 BATT_socBrick09_11 "State of charge of brick 9";
CM_ SG_ 2630615051 BATT_socBrick10_11 "State of charge of brick 10";
CM_ BO_ 2630877184 "State of charge of bricks 13-14";
CM_ SG_ 2630877184 BATT_socState_0 "SOC State";
CM_ SG_ 2630877184 BATT_socLoLimit_0 "SOC Low Limit Mask";
CM_ SG_ 2630877184 BATT_socHiLimit_0 "SOC Low Limit Mask";
CM_ SG_ 2630877184 BATT_socBrick14_0 "State of charge of brick 14";
CM_ SG_ 2630877184 BATT_socBrick13_0 "State of charge of brick 13";
CM_ BO_ 2630877185 "State of charge of bricks 13-14";
CM_ SG_ 2630877185 BATT_socState_1 "SOC State";
CM_ SG_ 2630877185 BATT_socLoLimit_1 "SOC Low Limit Mask";
CM_ SG_ 2630877185 BATT_socHiLimit_1 "SOC Low Limit Mask";
CM_ SG_ 2630877185 BATT_socBrick14_1 "State of charge of brick 14";
CM_ SG_ 2630877185 BATT_socBrick13_1 "State of charge of brick 13";
CM_ BO_ 2630877186 "State of charge of bricks 13-14";
CM_ SG_ 2630877186 BATT_socState_2 "SOC State";
CM_ SG_ 2630877186 BATT_socLoLimit_2 "SOC Low Limit Mask";
CM_ SG_ 2630877186 BATT_socHiLimit_2 "SOC Low Limit Mask";
CM_ SG_ 2630877186 BATT_socBrick14_2 "State of charge of brick 14";
CM_ SG_ 2630877186 BATT_socBrick13_2 "State of charge of brick 13";
CM_ BO_ 2630877187 "State of charge of bricks 13-14";
CM_ SG_ 2630877187 BATT_socState_3 "SOC State";
CM_ SG_ 2630877187 BATT_socLoLimit_3 "SOC Low Limit Mask";
CM_ SG_ 2630877187 BATT_socHiLimit_3 "SOC Low Limit Mask";
CM_ SG_ 2630877187 BATT_socBrick14_3 "State of charge of brick 14";
CM_ SG_ 2630877187 BATT_socBrick13_3 "State of charge of brick 13";
CM_ BO_ 2630877188 "State of charge of bricks 13-14";
CM_ SG_ 2630877188 BATT_socState_4 "SOC State";
CM_ SG_ 2630877188 BATT_socLoLimit_4 "SOC Low Limit Mask";
CM_ SG_ 2630877188 BATT_socHiLimit_4 "SOC Low Limit Mask";
CM_ SG_ 2630877188 BATT_socBrick14_4 "State of charge of brick 14";
CM_ SG_ 2630877188 BATT_socBrick13_4 "State of charge of brick 13";
CM_ BO_ 2630877189 "State of charge of bricks 13-14";
CM_ SG_ 2630877189 BATT_socState_5 "SOC State";
CM_ SG_ 2630877189 BATT_socLoLimit_5 "SOC Low Limit Mask";
CM_ SG_ 2630877189 BATT_socHiLimit_5 "SOC Low Limit Mask";
CM_ SG_ 2630877189 BATT_socBrick14_5 "State of charge of brick 14";
CM_ SG_ 2630877189 BATT_socBrick13_5 "State of charge of brick 13";
CM_ BO_ 2630877190 "State of charge of bricks 13-14";
CM_ SG_ 2630877190 BATT_socState_6 "SOC State";
CM_ SG_ 2630877190 BATT_socLoLimit_6 "SOC Low Limit Mask";
CM_ SG_ 2630877190 BATT_socHiLimit_6 "SOC Low Limit Mask";
CM_ SG_ 2630877190 BATT_socBrick14_6 "State of charge of brick 14";
CM_ SG_ 2630877190 BATT_socBrick13_6 "State of charge of brick 13";
CM_ BO_ 2630877191 "State of charge of bricks 13-14";
CM_ SG_ 2630877191 BATT_socState_7 "SOC State";
CM_ SG_ 2630877191 BATT_socLoLimit_7 "SOC Low Limit Mask";
CM_ SG_ 2630877191 BATT_socHiLimit_7 "SOC Low Limit Mask";
CM_ SG_ 2630877191 BATT_socBrick14_7 "State of charge of brick 14";
CM_ SG_ 2630877191 BATT_socBrick13_7 "State of charge of brick 13";
CM_ BO_ 2630877192 "State of charge of bricks 13-14";
CM_ SG_ 2630877192 BATT_socState_8 "SOC State";
CM_ SG_ 2630877192 BATT_socLoLimit_8 "SOC Low Limit Mask";
CM_ SG_ 2630877192 BATT_socHiLimit_8 "SOC Low Limit Mask";
CM_ SG_ 2630877192 BATT_socBrick14_8 "State of charge of brick 14";
CM_ SG_ 2630877192 BATT_socBrick13_8 "State of charge of brick 13";
CM_ BO_ 2630877193 "State of charge of bricks 13-14";
CM_ SG_ 2630877193 BATT_socState_9 "SOC State";
CM_ SG_ 2630877193 BATT_socLoLimit_9 "SOC Low Limit Mask";
CM_ SG_ 2630877193 BATT_socHiLimit_9 "SOC Low Limit Mask";
CM_ SG_ 2630877193 BATT_socBrick14_9 "State of charge of brick 14";
CM_ SG_ 2630877193 BATT_socBrick13_9 "State of charge of brick 13";
CM_ BO_ 2630877194 "State of charge of bricks 13-14";
CM_ SG_ 2630877194 BATT_socState_10 "SOC State";
CM_ SG_ 2630877194 BATT_socLoLimit_10 "SOC Low Limit Mask";
CM_ SG_ 2630877194 BATT_socHiLimit_10 "SOC Low Limit Mask";
CM_ SG_ 2630877194 BATT_socBrick14_10 "State of charge of brick 14";
CM_ SG_ 2630877194 BATT_socBrick13_10 "State of charge of brick 13";
CM_ BO_ 2630877195 "State of charge of bricks 13-14";
CM_ SG_ 2630877195 BATT_socState_11 "SOC State";
CM_ SG_ 2630877195 BATT_socLoLimit_11 "SOC Low Limit Mask";
CM_ SG_ 2630877195 BATT_socHiLimit_11 "SOC Low Limit Mask";
CM_ SG_ 2630877195 BATT_socBrick14_11 "State of charge of brick 14";
CM_ SG_ 2630877195 BATT_socBrick13_11 "State of charge of brick 13";
CM_ SG_ 2643001344 BATT_deltaQTaskOsTimeDelta "Delta Q Charger Task OS Time Delta";
CM_ SG_ 2643001344 BATT_deltaQTaskOsTime "Delta Q Charger Task OS Time";
CM_ SG_ 2643001344 BATT_deltaQFifoWaterMark "Delta Q Charger Event Queue Water Mark";
CM_ SG_ 2643001344 BATT_deltaQFifoSizeUsed "Delta Q Charger Event Queue Size Used";
CM_ SG_ 2643001344 BATT_deltaQEvent "Delta Q Charger Event";
CM_ SG_ 2643001344 BATT_deltaQError "Delta Q Charger Error";
CM_ SG_ 2643001344 BATT_deltaQState "Delta Q Charger State";
CM_ BO_ 2671771648 "ADC 1 message just for inhouse testing";
CM_ BO_ 2671771649 "ADC 1 message just for inhouse testing";
CM_ BO_ 2671771650 "ADC 1 message just for inhouse testing";
CM_ BO_ 2671771651 "ADC 1 message just for inhouse testing";
CM_ BO_ 2671771652 "ADC 1 message just for inhouse testing";
CM_ BO_ 2671771653 "ADC 1 message just for inhouse testing";
CM_ BO_ 2671771654 "ADC 1 message just for inhouse testing";
CM_ BO_ 2671771655 "ADC 1 message just for inhouse testing";
CM_ BO_ 2671771656 "ADC 1 message just for inhouse testing";
CM_ BO_ 2671771657 "ADC 1 message just for inhouse testing";
CM_ BO_ 2671771658 "ADC 1 message just for inhouse testing";
CM_ BO_ 2671771659 "ADC 1 message just for inhouse testing";
CM_ BO_ 2672033792 "ADC 1 message just for inhouse testing";
CM_ BO_ 2672033793 "ADC 1 message just for inhouse testing";
CM_ BO_ 2672033794 "ADC 1 message just for inhouse testing";
CM_ BO_ 2672033795 "ADC 1 message just for inhouse testing";
CM_ BO_ 2672033796 "ADC 1 message just for inhouse testing";
CM_ BO_ 2672033797 "ADC 1 message just for inhouse testing";
CM_ BO_ 2672033798 "ADC 1 message just for inhouse testing";
CM_ BO_ 2672033799 "ADC 1 message just for inhouse testing";
CM_ BO_ 2672033800 "ADC 1 message just for inhouse testing";
CM_ BO_ 2672033801 "ADC 1 message just for inhouse testing";
CM_ BO_ 2672033802 "ADC 1 message just for inhouse testing";
CM_ BO_ 2672033803 "ADC 1 message just for inhouse testing";
CM_ BO_ 2672295936 "ADC 1 message just for inhouse testing";
CM_ BO_ 2672295937 "ADC 1 message just for inhouse testing";
CM_ BO_ 2672295938 "ADC 1 message just for inhouse testing";
CM_ BO_ 2672295939 "ADC 1 message just for inhouse testing";
CM_ BO_ 2672295940 "ADC 1 message just for inhouse testing";
CM_ BO_ 2672295941 "ADC 1 message just for inhouse testing";
CM_ BO_ 2672295942 "ADC 1 message just for inhouse testing";
CM_ BO_ 2672295943 "ADC 1 message just for inhouse testing";
CM_ BO_ 2672295944 "ADC 1 message just for inhouse testing";
CM_ BO_ 2672295945 "ADC 1 message just for inhouse testing";
CM_ BO_ 2672295946 "ADC 1 message just for inhouse testing";
CM_ BO_ 2672295947 "ADC 1 message just for inhouse testing";

BA_DEF_ BO_  "GenMsgDiag" ENUM "No","Yes";
BA_DEF_ BO_  "GenMsgInstanced" STRING ;
BA_DEF_ SG_  "GenSigType" ENUM "Extended","Diagnostic","Standard","Modified";
BA_DEF_ BO_  "GenMsgCycleTime" INT 0 0;
BA_DEF_ SG_  "GenSigSNA" INT 0 65535;
BA_DEF_ SG_  "Access" ENUM "r","rw";
BA_DEF_DEF_  "GenMsgDiag" "No";
BA_DEF_DEF_  "GenMsgInstanced" "No";
BA_DEF_DEF_  "GenSigType" "Standard";
BA_DEF_DEF_  "GenMsgCycleTime" 0;
BA_DEF_DEF_  "GenSigSNA" 0;
BA_DEF_DEF_  "Access" "r";
BA_ "GenMsgDiag" BO_ 2626813958 1;
BA_ "GenMsgDiag" BO_ 2626813959 1;
BA_ "GenMsgDiag" BO_ 2626813960 1;
BA_ "GenMsgDiag" BO_ 2626813961 1;
BA_ "GenMsgDiag" BO_ 2626813962 1;
BA_ "GenMsgDiag" BO_ 2626813963 1;
BA_ "GenMsgDiag" BO_ 2626818048 1;
BA_ "GenMsgDiag" BO_ 2626818049 1;
BA_ "GenMsgDiag" BO_ 2626818050 1;
BA_ "GenMsgDiag" BO_ 2626818051 1;
BA_ "GenMsgDiag" BO_ 2626818052 1;
BA_ "GenMsgDiag" BO_ 2626818053 1;
BA_ "GenMsgDiag" BO_ 2626818054 1;
BA_ "GenMsgDiag" BO_ 2626818055 1;
BA_ "GenMsgDiag" BO_ 2626818056 1;
BA_ "GenMsgDiag" BO_ 2626818057 1;
BA_ "GenMsgDiag" BO_ 2626818058 1;
BA_ "GenMsgDiag" BO_ 2626818059 1;
BA_ "GenMsgDiag" BO_ 2626822144 1;
BA_ "GenMsgDiag" BO_ 2626822145 1;
BA_ "GenMsgDiag" BO_ 2626822146 1;
BA_ "GenMsgDiag" BO_ 2626822147 1;
BA_ "GenMsgDiag" BO_ 2626822148 1;
BA_ "GenMsgDiag" BO_ 2626822149 1;
BA_ "GenMsgDiag" BO_ 2626822150 1;
BA_ "GenMsgDiag" BO_ 2626822151 1;
BA_ "GenMsgDiag" BO_ 2626822152 1;
BA_ "GenMsgDiag" BO_ 2626822153 1;
BA_ "GenMsgDiag" BO_ 2626822154 1;
BA_ "GenMsgDiag" BO_ 2626822155 1;
BA_ "GenMsgDiag" BO_ 2626826240 1;
BA_ "GenMsgDiag" BO_ 2626826241 1;
BA_ "GenMsgDiag" BO_ 2626826242 1;
BA_ "GenMsgDiag" BO_ 2626826243 1;
BA_ "GenMsgDiag" BO_ 2626826244 1;
BA_ "GenMsgDiag" BO_ 2626826245 1;
BA_ "GenMsgDiag" BO_ 2626826246 1;
BA_ "GenMsgDiag" BO_ 2626826247 1;
BA_ "GenMsgDiag" BO_ 2626826248 1;
BA_ "GenMsgDiag" BO_ 2626826249 1;
BA_ "GenMsgDiag" BO_ 2626826250 1;
BA_ "GenMsgDiag" BO_ 2626826251 1;
BA_ "GenMsgDiag" BO_ 2629828608 1;
BA_ "GenMsgDiag" BO_ 2629828609 1;
BA_ "GenMsgDiag" BO_ 2629828610 1;
BA_ "GenMsgDiag" BO_ 2629828611 1;
BA_ "GenMsgDiag" BO_ 2629828612 1;
BA_ "GenMsgDiag" BO_ 2629828613 1;
BA_ "GenMsgDiag" BO_ 2629828614 1;
BA_ "GenMsgDiag" BO_ 2629828615 1;
BA_ "GenMsgDiag" BO_ 2629828616 1;
BA_ "GenMsgDiag" BO_ 2629828617 1;
BA_ "GenMsgDiag" BO_ 2629828618 1;
BA_ "GenMsgDiag" BO_ 2629828619 1;
BA_ "GenMsgDiag" BO_ 2630090752 1;
BA_ "GenMsgDiag" BO_ 2630090753 1;
BA_ "GenMsgDiag" BO_ 2630090754 1;
BA_ "GenMsgDiag" BO_ 2630090755 1;
BA_ "GenMsgDiag" BO_ 2630090756 1;
BA_ "GenMsgDiag" BO_ 2630090757 1;
BA_ "GenMsgDiag" BO_ 2630090758 1;
BA_ "GenMsgDiag" BO_ 2630090759 1;
BA_ "GenMsgDiag" BO_ 2630090760 1;
BA_ "GenMsgDiag" BO_ 2630090761 1;
BA_ "GenMsgDiag" BO_ 2630090762 1;
BA_ "GenMsgDiag" BO_ 2630090763 1;
BA_ "GenMsgDiag" BO_ 2630352896 1;
BA_ "GenMsgDiag" BO_ 2630352897 1;
BA_ "GenMsgDiag" BO_ 2630352898 1;
BA_ "GenMsgDiag" BO_ 2630352899 1;
BA_ "GenMsgDiag" BO_ 2630352900 1;
BA_ "GenMsgDiag" BO_ 2630352901 1;
BA_ "GenMsgDiag" BO_ 2630352902 1;
BA_ "GenMsgDiag" BO_ 2630352903 1;
BA_ "GenMsgDiag" BO_ 2630352904 1;
BA_ "GenMsgDiag" BO_ 2630352905 1;
BA_ "GenMsgDiag" BO_ 2630352906 1;
BA_ "GenMsgDiag" BO_ 2630352907 1;
BA_ "GenMsgDiag" BO_ 2630615040 1;
BA_ "GenMsgDiag" BO_ 2630615041 1;
BA_ "GenMsgDiag" BO_ 2630615042 1;
BA_ "GenMsgDiag" BO_ 2630615043 1;
BA_ "GenMsgDiag" BO_ 2630615044 1;
BA_ "GenMsgDiag" BO_ 2630615045 1;
BA_ "GenMsgDiag" BO_ 2630615046 1;
BA_ "GenMsgDiag" BO_ 2630615047 1;
BA_ "GenMsgDiag" BO_ 2630615048 1;
BA_ "GenMsgDiag" BO_ 2630615049 1;
BA_ "GenMsgDiag" BO_ 2630615050 1;
BA_ "GenMsgDiag" BO_ 2630615051 1;
BA_ "GenMsgDiag" BO_ 2630877184 1;
BA_ "GenMsgDiag" BO_ 2630877185 1;
BA_ "GenMsgDiag" BO_ 2630877186 1;
BA_ "GenMsgDiag" BO_ 2630877187 1;
BA_ "GenMsgDiag" BO_ 2630877188 1;
BA_ "GenMsgDiag" BO_ 2630877189 1;
BA_ "GenMsgDiag" BO_ 2630877190 1;
BA_ "GenMsgDiag" BO_ 2630877191 1;
BA_ "GenMsgDiag" BO_ 2630877192 1;
BA_ "GenMsgDiag" BO_ 2630877193 1;
BA_ "GenMsgDiag" BO_ 2630877194 1;
BA_ "GenMsgDiag" BO_ 2630877195 1;
BA_ "GenMsgDiag" BO_ 2671771648 1;
BA_ "GenMsgDiag" BO_ 2671771649 1;
BA_ "GenMsgDiag" BO_ 2671771650 1;
BA_ "GenMsgDiag" BO_ 2671771651 1;
BA_ "GenMsgDiag" BO_ 2671771652 1;
BA_ "GenMsgDiag" BO_ 2671771653 1;
BA_ "GenMsgDiag" BO_ 2671771654 1;
BA_ "GenMsgDiag" BO_ 2671771655 1;
BA_ "GenMsgDiag" BO_ 2671771656 1;
BA_ "GenMsgDiag" BO_ 2671771657 1;
BA_ "GenMsgDiag" BO_ 2671771658 1;
BA_ "GenMsgDiag" BO_ 2671771659 1;
BA_ "GenMsgDiag" BO_ 2672033792 1;
BA_ "GenMsgDiag" BO_ 2672033793 1;
BA_ "GenMsgDiag" BO_ 2672033794 1;
BA_ "GenMsgDiag" BO_ 2672033795 1;
BA_ "GenMsgDiag" BO_ 2672033796 1;
BA_ "GenMsgDiag" BO_ 2672033797 1;
BA_ "GenMsgDiag" BO_ 2672033798 1;
BA_ "GenMsgDiag" BO_ 2672033799 1;
BA_ "GenMsgDiag" BO_ 2672033800 1;
BA_ "GenMsgDiag" BO_ 2672033801 1;
BA_ "GenMsgDiag" BO_ 2672033802 1;
BA_ "GenMsgDiag" BO_ 2672033803 1;
BA_ "GenMsgDiag" BO_ 2672295936 1;
BA_ "GenMsgDiag" BO_ 2672295937 1;
BA_ "GenMsgDiag" BO_ 2672295938 1;
BA_ "GenMsgDiag" BO_ 2672295939 1;
BA_ "GenMsgDiag" BO_ 2672295940 1;
BA_ "GenMsgDiag" BO_ 2672295941 1;
BA_ "GenMsgDiag" BO_ 2672295942 1;
BA_ "GenMsgDiag" BO_ 2672295943 1;
BA_ "GenMsgDiag" BO_ 2672295944 1;
BA_ "GenMsgDiag" BO_ 2672295945 1;
BA_ "GenMsgDiag" BO_ 2672295946 1;
BA_ "GenMsgDiag" BO_ 2672295947 1;
BA_ "GenMsgInstanced" BO_ 2626813958 "False";
BA_ "GenMsgInstanced" BO_ 2626813959 "False";
BA_ "GenMsgInstanced" BO_ 2626813960 "False";
BA_ "GenMsgInstanced" BO_ 2626813961 "False";
BA_ "GenMsgInstanced" BO_ 2626813962 "False";
BA_ "GenMsgInstanced" BO_ 2626813963 "False";
BA_ "GenMsgInstanced" BO_ 2626818048 "False";
BA_ "GenMsgInstanced" BO_ 2626818049 "False";
BA_ "GenMsgInstanced" BO_ 2626818050 "False";
BA_ "GenMsgInstanced" BO_ 2626818051 "False";
BA_ "GenMsgInstanced" BO_ 2626818052 "False";
BA_ "GenMsgInstanced" BO_ 2626818053 "False";
BA_ "GenMsgInstanced" BO_ 2626818054 "False";
BA_ "GenMsgInstanced" BO_ 2626818055 "False";
BA_ "GenMsgInstanced" BO_ 2626818056 "False";
BA_ "GenMsgInstanced" BO_ 2626818057 "False";
BA_ "GenMsgInstanced" BO_ 2626818058 "False";
BA_ "GenMsgInstanced" BO_ 2626818059 "False";
BA_ "GenMsgInstanced" BO_ 2626822144 "False";
BA_ "GenMsgInstanced" BO_ 2626822145 "False";
BA_ "GenMsgInstanced" BO_ 2626822146 "False";
BA_ "GenMsgInstanced" BO_ 2626822147 "False";
BA_ "GenMsgInstanced" BO_ 2626822148 "False";
BA_ "GenMsgInstanced" BO_ 2626822149 "False";
BA_ "GenMsgInstanced" BO_ 2626822150 "False";
BA_ "GenMsgInstanced" BO_ 2626822151 "False";
BA_ "GenMsgInstanced" BO_ 2626822152 "False";
BA_ "GenMsgInstanced" BO_ 2626822153 "False";
BA_ "GenMsgInstanced" BO_ 2626822154 "False";
BA_ "GenMsgInstanced" BO_ 2626822155 "False";
BA_ "GenMsgInstanced" BO_ 2626826240 "False";
BA_ "GenMsgInstanced" BO_ 2626826241 "False";
BA_ "GenMsgInstanced" BO_ 2626826242 "False";
BA_ "GenMsgInstanced" BO_ 2626826243 "False";
BA_ "GenMsgInstanced" BO_ 2626826244 "False";
BA_ "GenMsgInstanced" BO_ 2626826245 "False";
BA_ "GenMsgInstanced" BO_ 2626826246 "False";
BA_ "GenMsgInstanced" BO_ 2626826247 "False";
BA_ "GenMsgInstanced" BO_ 2626826248 "False";
BA_ "GenMsgInstanced" BO_ 2626826249 "False";
BA_ "GenMsgInstanced" BO_ 2626826250 "False";
BA_ "GenMsgInstanced" BO_ 2626826251 "False";
BA_ "GenMsgInstanced" BO_ 2626945024 "False";
BA_ "GenMsgInstanced" BO_ 2626945025 "False";
BA_ "GenMsgInstanced" BO_ 2626945026 "False";
BA_ "GenMsgInstanced" BO_ 2626945027 "False";
BA_ "GenMsgInstanced" BO_ 2626945028 "False";
BA_ "GenMsgInstanced" BO_ 2626945029 "False";
BA_ "GenMsgInstanced" BO_ 2626945030 "False";
BA_ "GenMsgInstanced" BO_ 2626945031 "False";
BA_ "GenMsgInstanced" BO_ 2626945032 "False";
BA_ "GenMsgInstanced" BO_ 2626945033 "False";
BA_ "GenMsgInstanced" BO_ 2626945034 "False";
BA_ "GenMsgInstanced" BO_ 2626945035 "False";
BA_ "GenMsgInstanced" BO_ 2629828608 "False";
BA_ "GenMsgInstanced" BO_ 2629828609 "False";
BA_ "GenMsgInstanced" BO_ 2629828610 "False";
BA_ "GenMsgInstanced" BO_ 2629828611 "False";
BA_ "GenMsgInstanced" BO_ 2629828612 "False";
BA_ "GenMsgInstanced" BO_ 2629828613 "False";
BA_ "GenMsgInstanced" BO_ 2629828614 "False";
BA_ "GenMsgInstanced" BO_ 2629828615 "False";
BA_ "GenMsgInstanced" BO_ 2629828616 "False";
BA_ "GenMsgInstanced" BO_ 2629828617 "False";
BA_ "GenMsgInstanced" BO_ 2629828618 "False";
BA_ "GenMsgInstanced" BO_ 2629828619 "False";
BA_ "GenMsgInstanced" BO_ 2630090752 "False";
BA_ "GenMsgInstanced" BO_ 2630090753 "False";
BA_ "GenMsgInstanced" BO_ 2630090754 "False";
BA_ "GenMsgInstanced" BO_ 2630090755 "False";
BA_ "GenMsgInstanced" BO_ 2630090756 "False";
BA_ "GenMsgInstanced" BO_ 2630090757 "False";
BA_ "GenMsgInstanced" BO_ 2630090758 "False";
BA_ "GenMsgInstanced" BO_ 2630090759 "False";
BA_ "GenMsgInstanced" BO_ 2630090760 "False";
BA_ "GenMsgInstanced" BO_ 2630090761 "False";
BA_ "GenMsgInstanced" BO_ 2630090762 "False";
BA_ "GenMsgInstanced" BO_ 2630090763 "False";
BA_ "GenMsgInstanced" BO_ 2630352896 "False";
BA_ "GenMsgInstanced" BO_ 2630352897 "False";
BA_ "GenMsgInstanced" BO_ 2630352898 "False";
BA_ "GenMsgInstanced" BO_ 2630352899 "False";
BA_ "GenMsgInstanced" BO_ 2630352900 "False";
BA_ "GenMsgInstanced" BO_ 2630352901 "False";
BA_ "GenMsgInstanced" BO_ 2630352902 "False";
BA_ "GenMsgInstanced" BO_ 2630352903 "False";
BA_ "GenMsgInstanced" BO_ 2630352904 "False";
BA_ "GenMsgInstanced" BO_ 2630352905 "False";
BA_ "GenMsgInstanced" BO_ 2630352906 "False";
BA_ "GenMsgInstanced" BO_ 2630352907 "False";
BA_ "GenMsgInstanced" BO_ 2630615040 "False";
BA_ "GenMsgInstanced" BO_ 2630615041 "False";
BA_ "GenMsgInstanced" BO_ 2630615042 "False";
BA_ "GenMsgInstanced" BO_ 2630615043 "False";
BA_ "GenMsgInstanced" BO_ 2630615044 "False";
BA_ "GenMsgInstanced" BO_ 2630615045 "False";
BA_ "GenMsgInstanced" BO_ 2630615046 "False";
BA_ "GenMsgInstanced" BO_ 2630615047 "False";
BA_ "GenMsgInstanced" BO_ 2630615048 "False";
BA_ "GenMsgInstanced" BO_ 2630615049 "False";
BA_ "GenMsgInstanced" BO_ 2630615050 "False";
BA_ "GenMsgInstanced" BO_ 2630615051 "False";
BA_ "GenMsgInstanced" BO_ 2630877184 "False";
BA_ "GenMsgInstanced" BO_ 2630877185 "False";
BA_ "GenMsgInstanced" BO_ 2630877186 "False";
BA_ "GenMsgInstanced" BO_ 2630877187 "False";
BA_ "GenMsgInstanced" BO_ 2630877188 "False";
BA_ "GenMsgInstanced" BO_ 2630877189 "False";
BA_ "GenMsgInstanced" BO_ 2630877190 "False";
BA_ "GenMsgInstanced" BO_ 2630877191 "False";
BA_ "GenMsgInstanced" BO_ 2630877192 "False";
BA_ "GenMsgInstanced" BO_ 2630877193 "False";
BA_ "GenMsgInstanced" BO_ 2630877194 "False";
BA_ "GenMsgInstanced" BO_ 2630877195 "False";
BA_ "GenMsgInstanced" BO_ 2642411520 "False";
BA_ "GenMsgInstanced" BO_ 2642411521 "False";
BA_ "GenMsgInstanced" BO_ 2642411522 "False";
BA_ "GenMsgInstanced" BO_ 2642411523 "False";
BA_ "GenMsgInstanced" BO_ 2642411524 "False";
BA_ "GenMsgInstanced" BO_ 2642411525 "False";
BA_ "GenMsgInstanced" BO_ 2642411526 "False";
BA_ "GenMsgInstanced" BO_ 2642411527 "False";
BA_ "GenMsgInstanced" BO_ 2642411528 "False";
BA_ "GenMsgInstanced" BO_ 2642411529 "False";
BA_ "GenMsgInstanced" BO_ 2642411530 "False";
BA_ "GenMsgInstanced" BO_ 2642411531 "False";
BA_ "GenMsgInstanced" BO_ 2642935808 "False";
BA_ "GenMsgInstanced" BO_ 2642935809 "False";
BA_ "GenMsgInstanced" BO_ 2642935810 "False";
BA_ "GenMsgInstanced" BO_ 2642935811 "False";
BA_ "GenMsgInstanced" BO_ 2642935812 "False";
BA_ "GenMsgInstanced" BO_ 2642935813 "False";
BA_ "GenMsgInstanced" BO_ 2642935814 "False";
BA_ "GenMsgInstanced" BO_ 2642935815 "False";
BA_ "GenMsgInstanced" BO_ 2642935816 "False";
BA_ "GenMsgInstanced" BO_ 2642935817 "False";
BA_ "GenMsgInstanced" BO_ 2642935818 "False";
BA_ "GenMsgInstanced" BO_ 2642935819 "False";
BA_ "GenMsgInstanced" BO_ 2643001344 "False";
BA_ "GenMsgInstanced" BO_ 2671771648 "False";
BA_ "GenMsgInstanced" BO_ 2671771649 "False";
BA_ "GenMsgInstanced" BO_ 2671771650 "False";
BA_ "GenMsgInstanced" BO_ 2671771651 "False";
BA_ "GenMsgInstanced" BO_ 2671771652 "False";
BA_ "GenMsgInstanced" BO_ 2671771653 "False";
BA_ "GenMsgInstanced" BO_ 2671771654 "False";
BA_ "GenMsgInstanced" BO_ 2671771655 "False";
BA_ "GenMsgInstanced" BO_ 2671771656 "False";
BA_ "GenMsgInstanced" BO_ 2671771657 "False";
BA_ "GenMsgInstanced" BO_ 2671771658 "False";
BA_ "GenMsgInstanced" BO_ 2671771659 "False";
BA_ "GenMsgInstanced" BO_ 2672033792 "False";
BA_ "GenMsgInstanced" BO_ 2672033793 "False";
BA_ "GenMsgInstanced" BO_ 2672033794 "False";
BA_ "GenMsgInstanced" BO_ 2672033795 "False";
BA_ "GenMsgInstanced" BO_ 2672033796 "False";
BA_ "GenMsgInstanced" BO_ 2672033797 "False";
BA_ "GenMsgInstanced" BO_ 2672033798 "False";
BA_ "GenMsgInstanced" BO_ 2672033799 "False";
BA_ "GenMsgInstanced" BO_ 2672033800 "False";
BA_ "GenMsgInstanced" BO_ 2672033801 "False";
BA_ "GenMsgInstanced" BO_ 2672033802 "False";
BA_ "GenMsgInstanced" BO_ 2672033803 "False";
BA_ "GenMsgInstanced" BO_ 2672295936 "False";
BA_ "GenMsgInstanced" BO_ 2672295937 "False";
BA_ "GenMsgInstanced" BO_ 2672295938 "False";
BA_ "GenMsgInstanced" BO_ 2672295939 "False";
BA_ "GenMsgInstanced" BO_ 2672295940 "False";
BA_ "GenMsgInstanced" BO_ 2672295941 "False";
BA_ "GenMsgInstanced" BO_ 2672295942 "False";
BA_ "GenMsgInstanced" BO_ 2672295943 "False";
BA_ "GenMsgInstanced" BO_ 2672295944 "False";
BA_ "GenMsgInstanced" BO_ 2672295945 "False";
BA_ "GenMsgInstanced" BO_ 2672295946 "False";
BA_ "GenMsgInstanced" BO_ 2672295947 "False";
BA_ "GenSigType" SG_ 2626813958 BATT_HrnsImpDelta_0_6 1;
BA_ "GenSigType" SG_ 2626813958 BATT_HrnsImpDelta_1_6 1;
BA_ "GenSigType" SG_ 2626813958 BATT_HrnsImpDelta_3_6 1;
BA_ "GenSigType" SG_ 2626813958 BATT_HrnsImpDelta_2_6 1;
BA_ "GenSigType" SG_ 2626813959 BATT_HrnsImpDelta_3_7 1;
BA_ "GenSigType" SG_ 2626813959 BATT_HrnsImpDelta_0_7 1;
BA_ "GenSigType" SG_ 2626813959 BATT_HrnsImpDelta_2_7 1;
BA_ "GenSigType" SG_ 2626813959 BATT_HrnsImpDelta_1_7 1;
BA_ "GenSigType" SG_ 2626813960 BATT_HrnsImpDelta_2_8 1;
BA_ "GenSigType" SG_ 2626813960 BATT_HrnsImpDelta_3_8 1;
BA_ "GenSigType" SG_ 2626813960 BATT_HrnsImpDelta_1_8 1;
BA_ "GenSigType" SG_ 2626813960 BATT_HrnsImpDelta_0_8 1;
BA_ "GenSigType" SG_ 2626813961 BATT_HrnsImpDelta_2_9 1;
BA_ "GenSigType" SG_ 2626813961 BATT_HrnsImpDelta_1_9 1;
BA_ "GenSigType" SG_ 2626813961 BATT_HrnsImpDelta_0_9 1;
BA_ "GenSigType" SG_ 2626813961 BATT_HrnsImpDelta_3_9 1;
BA_ "GenSigType" SG_ 2626813962 BATT_HrnsImpDelta_0_10 1;
BA_ "GenSigType" SG_ 2626813962 BATT_HrnsImpDelta_2_10 1;
BA_ "GenSigType" SG_ 2626813962 BATT_HrnsImpDelta_1_10 1;
BA_ "GenSigType" SG_ 2626813962 BATT_HrnsImpDelta_3_10 1;
BA_ "GenSigType" SG_ 2626813963 BATT_HrnsImpDelta_2_11 1;
BA_ "GenSigType" SG_ 2626813963 BATT_HrnsImpDelta_1_11 1;
BA_ "GenSigType" SG_ 2626813963 BATT_HrnsImpDelta_3_11 1;
BA_ "GenSigType" SG_ 2626813963 BATT_HrnsImpDelta_0_11 1;
BA_ "GenSigType" SG_ 2626818048 BATT_HrnsImpDelta_4_0 1;
BA_ "GenSigType" SG_ 2626818048 BATT_HrnsImpDelta_6_0 1;
BA_ "GenSigType" SG_ 2626818048 BATT_HrnsImpDelta_5_0 1;
BA_ "GenSigType" SG_ 2626818048 BATT_HrnsImpDelta_7_0 1;
BA_ "GenSigType" SG_ 2626818049 BATT_HrnsImpDelta_6_1 1;
BA_ "GenSigType" SG_ 2626818049 BATT_HrnsImpDelta_5_1 1;
BA_ "GenSigType" SG_ 2626818049 BATT_HrnsImpDelta_4_1 1;
BA_ "GenSigType" SG_ 2626818049 BATT_HrnsImpDelta_7_1 1;
BA_ "GenSigType" SG_ 2626818050 BATT_HrnsImpDelta_7_2 1;
BA_ "GenSigType" SG_ 2626818050 BATT_HrnsImpDelta_6_2 1;
BA_ "GenSigType" SG_ 2626818050 BATT_HrnsImpDelta_5_2 1;
BA_ "GenSigType" SG_ 2626818050 BATT_HrnsImpDelta_4_2 1;
BA_ "GenSigType" SG_ 2626818051 BATT_HrnsImpDelta_5_3 1;
BA_ "GenSigType" SG_ 2626818051 BATT_HrnsImpDelta_4_3 1;
BA_ "GenSigType" SG_ 2626818051 BATT_HrnsImpDelta_7_3 1;
BA_ "GenSigType" SG_ 2626818051 BATT_HrnsImpDelta_6_3 1;
BA_ "GenSigType" SG_ 2626818052 BATT_HrnsImpDelta_7_4 1;
BA_ "GenSigType" SG_ 2626818052 BATT_HrnsImpDelta_6_4 1;
BA_ "GenSigType" SG_ 2626818052 BATT_HrnsImpDelta_5_4 1;
BA_ "GenSigType" SG_ 2626818052 BATT_HrnsImpDelta_4_4 1;
BA_ "GenSigType" SG_ 2626818053 BATT_HrnsImpDelta_5_5 1;
BA_ "GenSigType" SG_ 2626818053 BATT_HrnsImpDelta_4_5 1;
BA_ "GenSigType" SG_ 2626818053 BATT_HrnsImpDelta_7_5 1;
BA_ "GenSigType" SG_ 2626818053 BATT_HrnsImpDelta_6_5 1;
BA_ "GenSigType" SG_ 2626818054 BATT_HrnsImpDelta_4_6 1;
BA_ "GenSigType" SG_ 2626818054 BATT_HrnsImpDelta_7_6 1;
BA_ "GenSigType" SG_ 2626818054 BATT_HrnsImpDelta_6_6 1;
BA_ "GenSigType" SG_ 2626818054 BATT_HrnsImpDelta_5_6 1;
BA_ "GenSigType" SG_ 2626818055 BATT_HrnsImpDelta_7_7 1;
BA_ "GenSigType" SG_ 2626818055 BATT_HrnsImpDelta_6_7 1;
BA_ "GenSigType" SG_ 2626818055 BATT_HrnsImpDelta_4_7 1;
BA_ "GenSigType" SG_ 2626818055 BATT_HrnsImpDelta_5_7 1;
BA_ "GenSigType" SG_ 2626818056 BATT_HrnsImpDelta_7_8 1;
BA_ "GenSigType" SG_ 2626818056 BATT_HrnsImpDelta_6_8 1;
BA_ "GenSigType" SG_ 2626818056 BATT_HrnsImpDelta_4_8 1;
BA_ "GenSigType" SG_ 2626818056 BATT_HrnsImpDelta_5_8 1;
BA_ "GenSigType" SG_ 2626818057 BATT_HrnsImpDelta_4_9 1;
BA_ "GenSigType" SG_ 2626818057 BATT_HrnsImpDelta_6_9 1;
BA_ "GenSigType" SG_ 2626818057 BATT_HrnsImpDelta_7_9 1;
BA_ "GenSigType" SG_ 2626818057 BATT_HrnsImpDelta_5_9 1;
BA_ "GenSigType" SG_ 2626818058 BATT_HrnsImpDelta_6_10 1;
BA_ "GenSigType" SG_ 2626818058 BATT_HrnsImpDelta_5_10 1;
BA_ "GenSigType" SG_ 2626818058 BATT_HrnsImpDelta_4_10 1;
BA_ "GenSigType" SG_ 2626818058 BATT_HrnsImpDelta_7_10 1;
BA_ "GenSigType" SG_ 2626818059 BATT_HrnsImpDelta_7_11 1;
BA_ "GenSigType" SG_ 2626818059 BATT_HrnsImpDelta_6_11 1;
BA_ "GenSigType" SG_ 2626818059 BATT_HrnsImpDelta_5_11 1;
BA_ "GenSigType" SG_ 2626818059 BATT_HrnsImpDelta_4_11 1;
BA_ "GenSigType" SG_ 2626822144 BATT_HrnsImpDelta_8_0 1;
BA_ "GenSigType" SG_ 2626822144 BATT_HrnsImpDelta_9_0 1;
BA_ "GenSigType" SG_ 2626822144 BATT_HrnsImpDelta_11_0 1;
BA_ "GenSigType" SG_ 2626822144 BATT_HrnsImpDelta_10_0 1;
BA_ "GenSigType" SG_ 2626822145 BATT_HrnsImpDelta_11_1 1;
BA_ "GenSigType" SG_ 2626822145 BATT_HrnsImpDelta_9_1 1;
BA_ "GenSigType" SG_ 2626822145 BATT_HrnsImpDelta_8_1 1;
BA_ "GenSigType" SG_ 2626822145 BATT_HrnsImpDelta_10_1 1;
BA_ "GenSigType" SG_ 2626822146 BATT_HrnsImpDelta_11_2 1;
BA_ "GenSigType" SG_ 2626822146 BATT_HrnsImpDelta_10_2 1;
BA_ "GenSigType" SG_ 2626822146 BATT_HrnsImpDelta_8_2 1;
BA_ "GenSigType" SG_ 2626822146 BATT_HrnsImpDelta_9_2 1;
BA_ "GenSigType" SG_ 2626822147 BATT_HrnsImpDelta_11_3 1;
BA_ "GenSigType" SG_ 2626822147 BATT_HrnsImpDelta_10_3 1;
BA_ "GenSigType" SG_ 2626822147 BATT_HrnsImpDelta_8_3 1;
BA_ "GenSigType" SG_ 2626822147 BATT_HrnsImpDelta_9_3 1;
BA_ "GenSigType" SG_ 2626822148 BATT_HrnsImpDelta_9_4 1;
BA_ "GenSigType" SG_ 2626822148 BATT_HrnsImpDelta_11_4 1;
BA_ "GenSigType" SG_ 2626822148 BATT_HrnsImpDelta_10_4 1;
BA_ "GenSigType" SG_ 2626822148 BATT_HrnsImpDelta_8_4 1;
BA_ "GenSigType" SG_ 2626822149 BATT_HrnsImpDelta_10_5 1;
BA_ "GenSigType" SG_ 2626822149 BATT_HrnsImpDelta_8_5 1;
BA_ "GenSigType" SG_ 2626822149 BATT_HrnsImpDelta_9_5 1;
BA_ "GenSigType" SG_ 2626822149 BATT_HrnsImpDelta_11_5 1;
BA_ "GenSigType" SG_ 2626822150 BATT_HrnsImpDelta_10_6 1;
BA_ "GenSigType" SG_ 2626822150 BATT_HrnsImpDelta_11_6 1;
BA_ "GenSigType" SG_ 2626822150 BATT_HrnsImpDelta_9_6 1;
BA_ "GenSigType" SG_ 2626822150 BATT_HrnsImpDelta_8_6 1;
BA_ "GenSigType" SG_ 2626822151 BATT_HrnsImpDelta_8_7 1;
BA_ "GenSigType" SG_ 2626822151 BATT_HrnsImpDelta_11_7 1;
BA_ "GenSigType" SG_ 2626822151 BATT_HrnsImpDelta_10_7 1;
BA_ "GenSigType" SG_ 2626822151 BATT_HrnsImpDelta_9_7 1;
BA_ "GenSigType" SG_ 2626822152 BATT_HrnsImpDelta_10_8 1;
BA_ "GenSigType" SG_ 2626822152 BATT_HrnsImpDelta_11_8 1;
BA_ "GenSigType" SG_ 2626822152 BATT_HrnsImpDelta_9_8 1;
BA_ "GenSigType" SG_ 2626822152 BATT_HrnsImpDelta_8_8 1;
BA_ "GenSigType" SG_ 2626822153 BATT_HrnsImpDelta_8_9 1;
BA_ "GenSigType" SG_ 2626822153 BATT_HrnsImpDelta_9_9 1;
BA_ "GenSigType" SG_ 2626822153 BATT_HrnsImpDelta_11_9 1;
BA_ "GenSigType" SG_ 2626822153 BATT_HrnsImpDelta_10_9 1;
BA_ "GenSigType" SG_ 2626822154 BATT_HrnsImpDelta_11_10 1;
BA_ "GenSigType" SG_ 2626822154 BATT_HrnsImpDelta_8_10 1;
BA_ "GenSigType" SG_ 2626822154 BATT_HrnsImpDelta_10_10 1;
BA_ "GenSigType" SG_ 2626822154 BATT_HrnsImpDelta_9_10 1;
BA_ "GenSigType" SG_ 2626822155 BATT_HrnsImpDelta_10_11 1;
BA_ "GenSigType" SG_ 2626822155 BATT_HrnsImpDelta_8_11 1;
BA_ "GenSigType" SG_ 2626822155 BATT_HrnsImpDelta_9_11 1;
BA_ "GenSigType" SG_ 2626822155 BATT_HrnsImpDelta_11_11 1;
BA_ "GenSigType" SG_ 2626826240 BATT_HrnsImpDelta_12_0 1;
BA_ "GenSigType" SG_ 2626826240 BATT_HrnsImpDelta_14_0 1;
BA_ "GenSigType" SG_ 2626826240 BATT_HrnsImpDelta_13_0 1;
BA_ "GenSigType" SG_ 2626826241 BATT_HrnsImpDelta_14_1 1;
BA_ "GenSigType" SG_ 2626826241 BATT_HrnsImpDelta_13_1 1;
BA_ "GenSigType" SG_ 2626826241 BATT_HrnsImpDelta_12_1 1;
BA_ "GenSigType" SG_ 2626826242 BATT_HrnsImpDelta_14_2 1;
BA_ "GenSigType" SG_ 2626826242 BATT_HrnsImpDelta_13_2 1;
BA_ "GenSigType" SG_ 2626826242 BATT_HrnsImpDelta_12_2 1;
BA_ "GenSigType" SG_ 2626826243 BATT_HrnsImpDelta_12_3 1;
BA_ "GenSigType" SG_ 2626826243 BATT_HrnsImpDelta_14_3 1;
BA_ "GenSigType" SG_ 2626826243 BATT_HrnsImpDelta_13_3 1;
BA_ "GenSigType" SG_ 2626826244 BATT_HrnsImpDelta_13_4 1;
BA_ "GenSigType" SG_ 2626826244 BATT_HrnsImpDelta_12_4 1;
BA_ "GenSigType" SG_ 2626826244 BATT_HrnsImpDelta_14_4 1;
BA_ "GenSigType" SG_ 2626826245 BATT_HrnsImpDelta_14_5 1;
BA_ "GenSigType" SG_ 2626826245 BATT_HrnsImpDelta_13_5 1;
BA_ "GenSigType" SG_ 2626826245 BATT_HrnsImpDelta_12_5 1;
BA_ "GenSigType" SG_ 2626826246 BATT_HrnsImpDelta_14_6 1;
BA_ "GenSigType" SG_ 2626826246 BATT_HrnsImpDelta_13_6 1;
BA_ "GenSigType" SG_ 2626826246 BATT_HrnsImpDelta_12_6 1;
BA_ "GenSigType" SG_ 2626826247 BATT_HrnsImpDelta_14_7 1;
BA_ "GenSigType" SG_ 2626826247 BATT_HrnsImpDelta_13_7 1;
BA_ "GenSigType" SG_ 2626826247 BATT_HrnsImpDelta_12_7 1;
BA_ "GenSigType" SG_ 2626826248 BATT_HrnsImpDelta_14_8 1;
BA_ "GenSigType" SG_ 2626826248 BATT_HrnsImpDelta_13_8 1;
BA_ "GenSigType" SG_ 2626826248 BATT_HrnsImpDelta_12_8 1;
BA_ "GenSigType" SG_ 2626826249 BATT_HrnsImpDelta_14_9 1;
BA_ "GenSigType" SG_ 2626826249 BATT_HrnsImpDelta_13_9 1;
BA_ "GenSigType" SG_ 2626826249 BATT_HrnsImpDelta_12_9 1;
BA_ "GenSigType" SG_ 2626826250 BATT_HrnsImpDelta_14_10 1;
BA_ "GenSigType" SG_ 2626826250 BATT_HrnsImpDelta_13_10 1;
BA_ "GenSigType" SG_ 2626826250 BATT_HrnsImpDelta_12_10 1;
BA_ "GenSigType" SG_ 2626826251 BATT_HrnsImpDelta_14_11 1;
BA_ "GenSigType" SG_ 2626826251 BATT_HrnsImpDelta_13_11 1;
BA_ "GenSigType" SG_ 2626826251 BATT_HrnsImpDelta_12_11 1;
BA_ "GenSigType" SG_ 2629828608 BATT_ahChgTotal_0 1;
BA_ "GenSigType" SG_ 2629828608 BATT_ahDchTotal_0 1;
BA_ "GenSigType" SG_ 2629828609 BATT_ahDchTotal_1 1;
BA_ "GenSigType" SG_ 2629828609 BATT_ahChgTotal_1 1;
BA_ "GenSigType" SG_ 2629828610 BATT_ahChgTotal_2 1;
BA_ "GenSigType" SG_ 2629828610 BATT_ahDchTotal_2 1;
BA_ "GenSigType" SG_ 2629828611 BATT_ahDchTotal_3 1;
BA_ "GenSigType" SG_ 2629828611 BATT_ahChgTotal_3 1;
BA_ "GenSigType" SG_ 2629828612 BATT_ahDchTotal_4 1;
BA_ "GenSigType" SG_ 2629828612 BATT_ahChgTotal_4 1;
BA_ "GenSigType" SG_ 2629828613 BATT_ahChgTotal_5 1;
BA_ "GenSigType" SG_ 2629828613 BATT_ahDchTotal_5 1;
BA_ "GenSigType" SG_ 2629828614 BATT_ahChgTotal_6 1;
BA_ "GenSigType" SG_ 2629828614 BATT_ahDchTotal_6 1;
BA_ "GenSigType" SG_ 2629828615 BATT_ahDchTotal_7 1;
BA_ "GenSigType" SG_ 2629828615 BATT_ahChgTotal_7 1;
BA_ "GenSigType" SG_ 2629828616 BATT_ahChgTotal_8 1;
BA_ "GenSigType" SG_ 2629828616 BATT_ahDchTotal_8 1;
BA_ "GenSigType" SG_ 2629828617 BATT_ahChgTotal_9 1;
BA_ "GenSigType" SG_ 2629828617 BATT_ahDchTotal_9 1;
BA_ "GenSigType" SG_ 2629828618 BATT_ahDchTotal_10 1;
BA_ "GenSigType" SG_ 2629828618 BATT_ahChgTotal_10 1;
BA_ "GenSigType" SG_ 2629828619 BATT_ahChgTotal_11 1;
BA_ "GenSigType" SG_ 2629828619 BATT_ahDchTotal_11 1;
BA_ "GenSigType" SG_ 2630090752 BATT_socBrick04_0 1;
BA_ "GenSigType" SG_ 2630090752 BATT_socBrick03_0 1;
BA_ "GenSigType" SG_ 2630090752 BATT_socBrick02_0 1;
BA_ "GenSigType" SG_ 2630090752 BATT_socBrick01_0 1;
BA_ "GenSigType" SG_ 2630090753 BATT_socBrick04_1 1;
BA_ "GenSigType" SG_ 2630090753 BATT_socBrick03_1 1;
BA_ "GenSigType" SG_ 2630090753 BATT_socBrick02_1 1;
BA_ "GenSigType" SG_ 2630090753 BATT_socBrick01_1 1;
BA_ "GenSigType" SG_ 2630090754 BATT_socBrick04_2 1;
BA_ "GenSigType" SG_ 2630090754 BATT_socBrick03_2 1;
BA_ "GenSigType" SG_ 2630090754 BATT_socBrick02_2 1;
BA_ "GenSigType" SG_ 2630090754 BATT_socBrick01_2 1;
BA_ "GenSigType" SG_ 2630090755 BATT_socBrick04_3 1;
BA_ "GenSigType" SG_ 2630090755 BATT_socBrick03_3 1;
BA_ "GenSigType" SG_ 2630090755 BATT_socBrick02_3 1;
BA_ "GenSigType" SG_ 2630090755 BATT_socBrick01_3 1;
BA_ "GenSigType" SG_ 2630090756 BATT_socBrick04_4 1;
BA_ "GenSigType" SG_ 2630090756 BATT_socBrick03_4 1;
BA_ "GenSigType" SG_ 2630090756 BATT_socBrick02_4 1;
BA_ "GenSigType" SG_ 2630090756 BATT_socBrick01_4 1;
BA_ "GenSigType" SG_ 2630090757 BATT_socBrick04_5 1;
BA_ "GenSigType" SG_ 2630090757 BATT_socBrick03_5 1;
BA_ "GenSigType" SG_ 2630090757 BATT_socBrick02_5 1;
BA_ "GenSigType" SG_ 2630090757 BATT_socBrick01_5 1;
BA_ "GenSigType" SG_ 2630090758 BATT_socBrick04_6 1;
BA_ "GenSigType" SG_ 2630090758 BATT_socBrick03_6 1;
BA_ "GenSigType" SG_ 2630090758 BATT_socBrick02_6 1;
BA_ "GenSigType" SG_ 2630090758 BATT_socBrick01_6 1;
BA_ "GenSigType" SG_ 2630090759 BATT_socBrick04_7 1;
BA_ "GenSigType" SG_ 2630090759 BATT_socBrick03_7 1;
BA_ "GenSigType" SG_ 2630090759 BATT_socBrick02_7 1;
BA_ "GenSigType" SG_ 2630090759 BATT_socBrick01_7 1;
BA_ "GenSigType" SG_ 2630090760 BATT_socBrick04_8 1;
BA_ "GenSigType" SG_ 2630090760 BATT_socBrick03_8 1;
BA_ "GenSigType" SG_ 2630090760 BATT_socBrick02_8 1;
BA_ "GenSigType" SG_ 2630090760 BATT_socBrick01_8 1;
BA_ "GenSigType" SG_ 2630090761 BATT_socBrick04_9 1;
BA_ "GenSigType" SG_ 2630090761 BATT_socBrick03_9 1;
BA_ "GenSigType" SG_ 2630090761 BATT_socBrick02_9 1;
BA_ "GenSigType" SG_ 2630090761 BATT_socBrick01_9 1;
BA_ "GenSigType" SG_ 2630090762 BATT_socBrick04_10 1;
BA_ "GenSigType" SG_ 2630090762 BATT_socBrick03_10 1;
BA_ "GenSigType" SG_ 2630090762 BATT_socBrick02_10 1;
BA_ "GenSigType" SG_ 2630090762 BATT_socBrick01_10 1;
BA_ "GenSigType" SG_ 2630090763 BATT_socBrick04_11 1;
BA_ "GenSigType" SG_ 2630090763 BATT_socBrick03_11 1;
BA_ "GenSigType" SG_ 2630090763 BATT_socBrick02_11 1;
BA_ "GenSigType" SG_ 2630090763 BATT_socBrick01_11 1;
BA_ "GenSigType" SG_ 2630352896 BATT_socBrick08_0 1;
BA_ "GenSigType" SG_ 2630352896 BATT_socBrick07_0 1;
BA_ "GenSigType" SG_ 2630352896 BATT_socBrick06_0 1;
BA_ "GenSigType" SG_ 2630352896 BATT_socBrick05_0 1;
BA_ "GenSigType" SG_ 2630352897 BATT_socBrick08_1 1;
BA_ "GenSigType" SG_ 2630352897 BATT_socBrick07_1 1;
BA_ "GenSigType" SG_ 2630352897 BATT_socBrick06_1 1;
BA_ "GenSigType" SG_ 2630352897 BATT_socBrick05_1 1;
BA_ "GenSigType" SG_ 2630352898 BATT_socBrick08_2 1;
BA_ "GenSigType" SG_ 2630352898 BATT_socBrick07_2 1;
BA_ "GenSigType" SG_ 2630352898 BATT_socBrick06_2 1;
BA_ "GenSigType" SG_ 2630352898 BATT_socBrick05_2 1;
BA_ "GenSigType" SG_ 2630352899 BATT_socBrick08_3 1;
BA_ "GenSigType" SG_ 2630352899 BATT_socBrick07_3 1;
BA_ "GenSigType" SG_ 2630352899 BATT_socBrick06_3 1;
BA_ "GenSigType" SG_ 2630352899 BATT_socBrick05_3 1;
BA_ "GenSigType" SG_ 2630352900 BATT_socBrick08_4 1;
BA_ "GenSigType" SG_ 2630352900 BATT_socBrick07_4 1;
BA_ "GenSigType" SG_ 2630352900 BATT_socBrick06_4 1;
BA_ "GenSigType" SG_ 2630352900 BATT_socBrick05_4 1;
BA_ "GenSigType" SG_ 2630352901 BATT_socBrick08_5 1;
BA_ "GenSigType" SG_ 2630352901 BATT_socBrick07_5 1;
BA_ "GenSigType" SG_ 2630352901 BATT_socBrick06_5 1;
BA_ "GenSigType" SG_ 2630352901 BATT_socBrick05_5 1;
BA_ "GenSigType" SG_ 2630352902 BATT_socBrick08_6 1;
BA_ "GenSigType" SG_ 2630352902 BATT_socBrick07_6 1;
BA_ "GenSigType" SG_ 2630352902 BATT_socBrick06_6 1;
BA_ "GenSigType" SG_ 2630352902 BATT_socBrick05_6 1;
BA_ "GenSigType" SG_ 2630352903 BATT_socBrick08_7 1;
BA_ "GenSigType" SG_ 2630352903 BATT_socBrick07_7 1;
BA_ "GenSigType" SG_ 2630352903 BATT_socBrick06_7 1;
BA_ "GenSigType" SG_ 2630352903 BATT_socBrick05_7 1;
BA_ "GenSigType" SG_ 2630352904 BATT_socBrick08_8 1;
BA_ "GenSigType" SG_ 2630352904 BATT_socBrick07_8 1;
BA_ "GenSigType" SG_ 2630352904 BATT_socBrick06_8 1;
BA_ "GenSigType" SG_ 2630352904 BATT_socBrick05_8 1;
BA_ "GenSigType" SG_ 2630352905 BATT_socBrick08_9 1;
BA_ "GenSigType" SG_ 2630352905 BATT_socBrick07_9 1;
BA_ "GenSigType" SG_ 2630352905 BATT_socBrick06_9 1;
BA_ "GenSigType" SG_ 2630352905 BATT_socBrick05_9 1;
BA_ "GenSigType" SG_ 2630352906 BATT_socBrick08_10 1;
BA_ "GenSigType" SG_ 2630352906 BATT_socBrick07_10 1;
BA_ "GenSigType" SG_ 2630352906 BATT_socBrick06_10 1;
BA_ "GenSigType" SG_ 2630352906 BATT_socBrick05_10 1;
BA_ "GenSigType" SG_ 2630352907 BATT_socBrick08_11 1;
BA_ "GenSigType" SG_ 2630352907 BATT_socBrick07_11 1;
BA_ "GenSigType" SG_ 2630352907 BATT_socBrick06_11 1;
BA_ "GenSigType" SG_ 2630352907 BATT_socBrick05_11 1;
BA_ "GenSigType" SG_ 2630615040 BATT_socBrick12_0 1;
BA_ "GenSigType" SG_ 2630615040 BATT_socBrick11_0 1;
BA_ "GenSigType" SG_ 2630615040 BATT_socBrick09_0 1;
BA_ "GenSigType" SG_ 2630615040 BATT_socBrick10_0 1;
BA_ "GenSigType" SG_ 2630615041 BATT_socBrick12_1 1;
BA_ "GenSigType" SG_ 2630615041 BATT_socBrick11_1 1;
BA_ "GenSigType" SG_ 2630615041 BATT_socBrick09_1 1;
BA_ "GenSigType" SG_ 2630615041 BATT_socBrick10_1 1;
BA_ "GenSigType" SG_ 2630615042 BATT_socBrick12_2 1;
BA_ "GenSigType" SG_ 2630615042 BATT_socBrick11_2 1;
BA_ "GenSigType" SG_ 2630615042 BATT_socBrick09_2 1;
BA_ "GenSigType" SG_ 2630615042 BATT_socBrick10_2 1;
BA_ "GenSigType" SG_ 2630615043 BATT_socBrick12_3 1;
BA_ "GenSigType" SG_ 2630615043 BATT_socBrick11_3 1;
BA_ "GenSigType" SG_ 2630615043 BATT_socBrick09_3 1;
BA_ "GenSigType" SG_ 2630615043 BATT_socBrick10_3 1;
BA_ "GenSigType" SG_ 2630615044 BATT_socBrick12_4 1;
BA_ "GenSigType" SG_ 2630615044 BATT_socBrick11_4 1;
BA_ "GenSigType" SG_ 2630615044 BATT_socBrick09_4 1;
BA_ "GenSigType" SG_ 2630615044 BATT_socBrick10_4 1;
BA_ "GenSigType" SG_ 2630615045 BATT_socBrick12_5 1;
BA_ "GenSigType" SG_ 2630615045 BATT_socBrick11_5 1;
BA_ "GenSigType" SG_ 2630615045 BATT_socBrick09_5 1;
BA_ "GenSigType" SG_ 2630615045 BATT_socBrick10_5 1;
BA_ "GenSigType" SG_ 2630615046 BATT_socBrick12_6 1;
BA_ "GenSigType" SG_ 2630615046 BATT_socBrick11_6 1;
BA_ "GenSigType" SG_ 2630615046 BATT_socBrick09_6 1;
BA_ "GenSigType" SG_ 2630615046 BATT_socBrick10_6 1;
BA_ "GenSigType" SG_ 2630615047 BATT_socBrick12_7 1;
BA_ "GenSigType" SG_ 2630615047 BATT_socBrick11_7 1;
BA_ "GenSigType" SG_ 2630615047 BATT_socBrick09_7 1;
BA_ "GenSigType" SG_ 2630615047 BATT_socBrick10_7 1;
BA_ "GenSigType" SG_ 2630615048 BATT_socBrick12_8 1;
BA_ "GenSigType" SG_ 2630615048 BATT_socBrick11_8 1;
BA_ "GenSigType" SG_ 2630615048 BATT_socBrick09_8 1;
BA_ "GenSigType" SG_ 2630615048 BATT_socBrick10_8 1;
BA_ "GenSigType" SG_ 2630615049 BATT_socBrick12_9 1;
BA_ "GenSigType" SG_ 2630615049 BATT_socBrick11_9 1;
BA_ "GenSigType" SG_ 2630615049 BATT_socBrick09_9 1;
BA_ "GenSigType" SG_ 2630615049 BATT_socBrick10_9 1;
BA_ "GenSigType" SG_ 2630615050 BATT_socBrick12_10 1;
BA_ "GenSigType" SG_ 2630615050 BATT_socBrick11_10 1;
BA_ "GenSigType" SG_ 2630615050 BATT_socBrick09_10 1;
BA_ "GenSigType" SG_ 2630615050 BATT_socBrick10_10 1;
BA_ "GenSigType" SG_ 2630615051 BATT_socBrick12_11 1;
BA_ "GenSigType" SG_ 2630615051 BATT_socBrick11_11 1;
BA_ "GenSigType" SG_ 2630615051 BATT_socBrick09_11 1;
BA_ "GenSigType" SG_ 2630615051 BATT_socBrick10_11 1;
BA_ "GenSigType" SG_ 2630877184 BATT_socState_0 1;
BA_ "GenSigType" SG_ 2630877184 BATT_socLoLimit_0 1;
BA_ "GenSigType" SG_ 2630877184 BATT_socHiLimit_0 1;
BA_ "GenSigType" SG_ 2630877184 BATT_socBrick14_0 1;
BA_ "GenSigType" SG_ 2630877184 BATT_socBrick13_0 1;
BA_ "GenSigType" SG_ 2630877185 BATT_socState_1 1;
BA_ "GenSigType" SG_ 2630877185 BATT_socLoLimit_1 1;
BA_ "GenSigType" SG_ 2630877185 BATT_socHiLimit_1 1;
BA_ "GenSigType" SG_ 2630877185 BATT_socBrick14_1 1;
BA_ "GenSigType" SG_ 2630877185 BATT_socBrick13_1 1;
BA_ "GenSigType" SG_ 2630877186 BATT_socState_2 1;
BA_ "GenSigType" SG_ 2630877186 BATT_socLoLimit_2 1;
BA_ "GenSigType" SG_ 2630877186 BATT_socHiLimit_2 1;
BA_ "GenSigType" SG_ 2630877186 BATT_socBrick14_2 1;
BA_ "GenSigType" SG_ 2630877186 BATT_socBrick13_2 1;
BA_ "GenSigType" SG_ 2630877187 BATT_socState_3 1;
BA_ "GenSigType" SG_ 2630877187 BATT_socLoLimit_3 1;
BA_ "GenSigType" SG_ 2630877187 BATT_socHiLimit_3 1;
BA_ "GenSigType" SG_ 2630877187 BATT_socBrick14_3 1;
BA_ "GenSigType" SG_ 2630877187 BATT_socBrick13_3 1;
BA_ "GenSigType" SG_ 2630877188 BATT_socState_4 1;
BA_ "GenSigType" SG_ 2630877188 BATT_socLoLimit_4 1;
BA_ "GenSigType" SG_ 2630877188 BATT_socHiLimit_4 1;
BA_ "GenSigType" SG_ 2630877188 BATT_socBrick14_4 1;
BA_ "GenSigType" SG_ 2630877188 BATT_socBrick13_4 1;
BA_ "GenSigType" SG_ 2630877189 BATT_socState_5 1;
BA_ "GenSigType" SG_ 2630877189 BATT_socLoLimit_5 1;
BA_ "GenSigType" SG_ 2630877189 BATT_socHiLimit_5 1;
BA_ "GenSigType" SG_ 2630877189 BATT_socBrick14_5 1;
BA_ "GenSigType" SG_ 2630877189 BATT_socBrick13_5 1;
BA_ "GenSigType" SG_ 2630877190 BATT_socState_6 1;
BA_ "GenSigType" SG_ 2630877190 BATT_socLoLimit_6 1;
BA_ "GenSigType" SG_ 2630877190 BATT_socHiLimit_6 1;
BA_ "GenSigType" SG_ 2630877190 BATT_socBrick14_6 1;
BA_ "GenSigType" SG_ 2630877190 BATT_socBrick13_6 1;
BA_ "GenSigType" SG_ 2630877191 BATT_socState_7 1;
BA_ "GenSigType" SG_ 2630877191 BATT_socLoLimit_7 1;
BA_ "GenSigType" SG_ 2630877191 BATT_socHiLimit_7 1;
BA_ "GenSigType" SG_ 2630877191 BATT_socBrick14_7 1;
BA_ "GenSigType" SG_ 2630877191 BATT_socBrick13_7 1;
BA_ "GenSigType" SG_ 2630877192 BATT_socState_8 1;
BA_ "GenSigType" SG_ 2630877192 BATT_socLoLimit_8 1;
BA_ "GenSigType" SG_ 2630877192 BATT_socHiLimit_8 1;
BA_ "GenSigType" SG_ 2630877192 BATT_socBrick14_8 1;
BA_ "GenSigType" SG_ 2630877192 BATT_socBrick13_8 1;
BA_ "GenSigType" SG_ 2630877193 BATT_socState_9 1;
BA_ "GenSigType" SG_ 2630877193 BATT_socLoLimit_9 1;
BA_ "GenSigType" SG_ 2630877193 BATT_socHiLimit_9 1;
BA_ "GenSigType" SG_ 2630877193 BATT_socBrick14_9 1;
BA_ "GenSigType" SG_ 2630877193 BATT_socBrick13_9 1;
BA_ "GenSigType" SG_ 2630877194 BATT_socState_10 1;
BA_ "GenSigType" SG_ 2630877194 BATT_socLoLimit_10 1;
BA_ "GenSigType" SG_ 2630877194 BATT_socHiLimit_10 1;
BA_ "GenSigType" SG_ 2630877194 BATT_socBrick14_10 1;
BA_ "GenSigType" SG_ 2630877194 BATT_socBrick13_10 1;
BA_ "GenSigType" SG_ 2630877195 BATT_socState_11 1;
BA_ "GenSigType" SG_ 2630877195 BATT_socLoLimit_11 1;
BA_ "GenSigType" SG_ 2630877195 BATT_socHiLimit_11 1;
BA_ "GenSigType" SG_ 2630877195 BATT_socBrick14_11 1;
BA_ "GenSigType" SG_ 2630877195 BATT_socBrick13_11 1;
BA_ "GenSigType" SG_ 2642935808 BATT_canTXFifoWaterMark_0 1;
BA_ "GenSigType" SG_ 2642935808 BATT_canRXFifoSizeUsed_0 1;
BA_ "GenSigType" SG_ 2642935808 BATT_canTXFifoSizeUsed_0 1;
BA_ "GenSigType" SG_ 2642935808 BATT_canRXFifoWaterMark_0 1;
BA_ "GenSigType" SG_ 2642935809 BATT_canTXFifoWaterMark_1 1;
BA_ "GenSigType" SG_ 2642935809 BATT_canTXFifoSizeUsed_1 1;
BA_ "GenSigType" SG_ 2642935809 BATT_canRXFifoWaterMark_1 1;
BA_ "GenSigType" SG_ 2642935809 BATT_canRXFifoSizeUsed_1 1;
BA_ "GenSigType" SG_ 2642935810 BATT_canTXFifoWaterMark_2 1;
BA_ "GenSigType" SG_ 2642935810 BATT_canRXFifoWaterMark_2 1;
BA_ "GenSigType" SG_ 2642935810 BATT_canTXFifoSizeUsed_2 1;
BA_ "GenSigType" SG_ 2642935810 BATT_canRXFifoSizeUsed_2 1;
BA_ "GenSigType" SG_ 2642935811 BATT_canTXFifoWaterMark_3 1;
BA_ "GenSigType" SG_ 2642935811 BATT_canRXFifoSizeUsed_3 1;
BA_ "GenSigType" SG_ 2642935811 BATT_canTXFifoSizeUsed_3 1;
BA_ "GenSigType" SG_ 2642935811 BATT_canRXFifoWaterMark_3 1;
BA_ "GenSigType" SG_ 2642935812 BATT_canTXFifoWaterMark_4 1;
BA_ "GenSigType" SG_ 2642935812 BATT_canRXFifoWaterMark_4 1;
BA_ "GenSigType" SG_ 2642935812 BATT_canTXFifoSizeUsed_4 1;
BA_ "GenSigType" SG_ 2642935812 BATT_canRXFifoSizeUsed_4 1;
BA_ "GenSigType" SG_ 2642935813 BATT_canTXFifoWaterMark_5 1;
BA_ "GenSigType" SG_ 2642935813 BATT_canRXFifoWaterMark_5 1;
BA_ "GenSigType" SG_ 2642935813 BATT_canRXFifoSizeUsed_5 1;
BA_ "GenSigType" SG_ 2642935813 BATT_canTXFifoSizeUsed_5 1;
BA_ "GenSigType" SG_ 2642935814 BATT_canTXFifoWaterMark_6 1;
BA_ "GenSigType" SG_ 2642935814 BATT_canRXFifoWaterMark_6 1;
BA_ "GenSigType" SG_ 2642935814 BATT_canTXFifoSizeUsed_6 1;
BA_ "GenSigType" SG_ 2642935814 BATT_canRXFifoSizeUsed_6 1;
BA_ "GenSigType" SG_ 2642935815 BATT_canTXFifoWaterMark_7 1;
BA_ "GenSigType" SG_ 2642935815 BATT_canRXFifoWaterMark_7 1;
BA_ "GenSigType" SG_ 2642935815 BATT_canTXFifoSizeUsed_7 1;
BA_ "GenSigType" SG_ 2642935815 BATT_canRXFifoSizeUsed_7 1;
BA_ "GenSigType" SG_ 2642935816 BATT_canTXFifoWaterMark_8 1;
BA_ "GenSigType" SG_ 2642935816 BATT_canRXFifoWaterMark_8 1;
BA_ "GenSigType" SG_ 2642935816 BATT_canTXFifoSizeUsed_8 1;
BA_ "GenSigType" SG_ 2642935816 BATT_canRXFifoSizeUsed_8 1;
BA_ "GenSigType" SG_ 2642935817 BATT_canTXFifoWaterMark_9 1;
BA_ "GenSigType" SG_ 2642935817 BATT_canRXFifoWaterMark_9 1;
BA_ "GenSigType" SG_ 2642935817 BATT_canTXFifoSizeUsed_9 1;
BA_ "GenSigType" SG_ 2642935817 BATT_canRXFifoSizeUsed_9 1;
BA_ "GenSigType" SG_ 2642935818 BATT_canTXFifoSizeUsed_10 1;
BA_ "GenSigType" SG_ 2642935818 BATT_canRXFifoSizeUsed_10 1;
BA_ "GenSigType" SG_ 2642935818 BATT_canTXFifoWaterMark_10 1;
BA_ "GenSigType" SG_ 2642935818 BATT_canRXFifoWaterMark_10 1;
BA_ "GenSigType" SG_ 2642935819 BATT_canTXFifoSizeUsed_11 1;
BA_ "GenSigType" SG_ 2642935819 BATT_canRXFifoSizeUsed_11 1;
BA_ "GenSigType" SG_ 2642935819 BATT_canTXFifoWaterMark_11 1;
BA_ "GenSigType" SG_ 2642935819 BATT_canRXFifoWaterMark_11 1;
BA_ "GenSigType" SG_ 2643001344 BATT_deltaQError 0;
BA_ "GenSigType" SG_ 2643001344 BATT_deltaQEvent 0;
BA_ "GenSigType" SG_ 2643001344 BATT_deltaQTaskOsTimeDelta 0;
BA_ "GenSigType" SG_ 2643001344 BATT_deltaQFifoWaterMark 0;
BA_ "GenSigType" SG_ 2643001344 BATT_deltaQState 0;
BA_ "GenSigType" SG_ 2643001344 BATT_deltaQFifoSizeUsed 0;
BA_ "GenSigType" SG_ 2643001344 BATT_deltaQTaskOsTime 0;
BA_ "GenSigType" SG_ 2671771648 BATT_boardADC_LOAD_0 0;
BA_ "GenSigType" SG_ 2671771648 BATT_boardADC_COMMON_DRAIN_0 0;
BA_ "GenSigType" SG_ 2671771648 BATT_boardADC_PACK_0 0;
BA_ "GenSigType" SG_ 2671771649 BATT_boardADC_LOAD_1 0;
BA_ "GenSigType" SG_ 2671771649 BATT_boardADC_COMMON_DRAIN_1 0;
BA_ "GenSigType" SG_ 2671771649 BATT_boardADC_PACK_1 0;
BA_ "GenSigType" SG_ 2671771650 BATT_boardADC_LOAD_2 0;
BA_ "GenSigType" SG_ 2671771650 BATT_boardADC_COMMON_DRAIN_2 0;
BA_ "GenSigType" SG_ 2671771650 BATT_boardADC_PACK_2 0;
BA_ "GenSigType" SG_ 2671771651 BATT_boardADC_LOAD_3 0;
BA_ "GenSigType" SG_ 2671771651 BATT_boardADC_COMMON_DRAIN_3 0;
BA_ "GenSigType" SG_ 2671771651 BATT_boardADC_PACK_3 0;
BA_ "GenSigType" SG_ 2671771652 BATT_boardADC_LOAD_4 0;
BA_ "GenSigType" SG_ 2671771652 BATT_boardADC_COMMON_DRAIN_4 0;
BA_ "GenSigType" SG_ 2671771652 BATT_boardADC_PACK_4 0;
BA_ "GenSigType" SG_ 2671771653 BATT_boardADC_LOAD_5 0;
BA_ "GenSigType" SG_ 2671771653 BATT_boardADC_COMMON_DRAIN_5 0;
BA_ "GenSigType" SG_ 2671771653 BATT_boardADC_PACK_5 0;
BA_ "GenSigType" SG_ 2671771654 BATT_boardADC_LOAD_6 0;
BA_ "GenSigType" SG_ 2671771654 BATT_boardADC_COMMON_DRAIN_6 0;
BA_ "GenSigType" SG_ 2671771654 BATT_boardADC_PACK_6 0;
BA_ "GenSigType" SG_ 2671771655 BATT_boardADC_LOAD_7 0;
BA_ "GenSigType" SG_ 2671771655 BATT_boardADC_COMMON_DRAIN_7 0;
BA_ "GenSigType" SG_ 2671771655 BATT_boardADC_PACK_7 0;
BA_ "GenSigType" SG_ 2671771656 BATT_boardADC_LOAD_8 0;
BA_ "GenSigType" SG_ 2671771656 BATT_boardADC_COMMON_DRAIN_8 0;
BA_ "GenSigType" SG_ 2671771656 BATT_boardADC_PACK_8 0;
BA_ "GenSigType" SG_ 2671771657 BATT_boardADC_LOAD_9 0;
BA_ "GenSigType" SG_ 2671771657 BATT_boardADC_COMMON_DRAIN_9 0;
BA_ "GenSigType" SG_ 2671771657 BATT_boardADC_PACK_9 0;
BA_ "GenSigType" SG_ 2671771658 BATT_boardADC_LOAD_10 0;
BA_ "GenSigType" SG_ 2671771658 BATT_boardADC_COMMON_DRAIN_10 0;
BA_ "GenSigType" SG_ 2671771658 BATT_boardADC_PACK_10 0;
BA_ "GenSigType" SG_ 2671771659 BATT_boardADC_LOAD_11 0;
BA_ "GenSigType" SG_ 2671771659 BATT_boardADC_COMMON_DRAIN_11 0;
BA_ "GenSigType" SG_ 2671771659 BATT_boardADC_PACK_11 0;
BA_ "GenSigType" SG_ 2672033792 BATT_boardADC_12V_0 0;
BA_ "GenSigType" SG_ 2672033792 BATT_boardADC_5V_0 0;
BA_ "GenSigType" SG_ 2672033792 BATT_boardADC_3V3_0 0;
BA_ "GenSigType" SG_ 2672033793 BATT_boardADC_12V_1 0;
BA_ "GenSigType" SG_ 2672033793 BATT_boardADC_5V_1 0;
BA_ "GenSigType" SG_ 2672033793 BATT_boardADC_3V3_1 0;
BA_ "GenSigType" SG_ 2672033794 BATT_boardADC_12V_2 0;
BA_ "GenSigType" SG_ 2672033794 BATT_boardADC_5V_2 0;
BA_ "GenSigType" SG_ 2672033794 BATT_boardADC_3V3_2 0;
BA_ "GenSigType" SG_ 2672033795 BATT_boardADC_12V_3 0;
BA_ "GenSigType" SG_ 2672033795 BATT_boardADC_5V_3 0;
BA_ "GenSigType" SG_ 2672033795 BATT_boardADC_3V3_3 0;
BA_ "GenSigType" SG_ 2672033796 BATT_boardADC_12V_4 0;
BA_ "GenSigType" SG_ 2672033796 BATT_boardADC_5V_4 0;
BA_ "GenSigType" SG_ 2672033796 BATT_boardADC_3V3_4 0;
BA_ "GenSigType" SG_ 2672033797 BATT_boardADC_12V_5 0;
BA_ "GenSigType" SG_ 2672033797 BATT_boardADC_5V_5 0;
BA_ "GenSigType" SG_ 2672033797 BATT_boardADC_3V3_5 0;
BA_ "GenSigType" SG_ 2672033798 BATT_boardADC_12V_6 0;
BA_ "GenSigType" SG_ 2672033798 BATT_boardADC_5V_6 0;
BA_ "GenSigType" SG_ 2672033798 BATT_boardADC_3V3_6 0;
BA_ "GenSigType" SG_ 2672033799 BATT_boardADC_12V_7 0;
BA_ "GenSigType" SG_ 2672033799 BATT_boardADC_5V_7 0;
BA_ "GenSigType" SG_ 2672033799 BATT_boardADC_3V3_7 0;
BA_ "GenSigType" SG_ 2672033800 BATT_boardADC_12V_8 0;
BA_ "GenSigType" SG_ 2672033800 BATT_boardADC_5V_8 0;
BA_ "GenSigType" SG_ 2672033800 BATT_boardADC_3V3_8 0;
BA_ "GenSigType" SG_ 2672033801 BATT_boardADC_12V_9 0;
BA_ "GenSigType" SG_ 2672033801 BATT_boardADC_5V_9 0;
BA_ "GenSigType" SG_ 2672033801 BATT_boardADC_3V3_9 0;
BA_ "GenSigType" SG_ 2672033802 BATT_boardADC_12V_10 0;
BA_ "GenSigType" SG_ 2672033802 BATT_boardADC_5V_10 0;
BA_ "GenSigType" SG_ 2672033802 BATT_boardADC_3V3_10 0;
BA_ "GenSigType" SG_ 2672033803 BATT_boardADC_12V_11 0;
BA_ "GenSigType" SG_ 2672033803 BATT_boardADC_5V_11 0;
BA_ "GenSigType" SG_ 2672033803 BATT_boardADC_3V3_11 0;
BA_ "GenSigType" SG_ 2672295936 BATT_boardADC_SHUNT_TEMP_0 0;
BA_ "GenSigType" SG_ 2672295936 BATT_boardADC_FET_TEMP_0 0;
BA_ "GenSigType" SG_ 2672295936 BATT_boardADC_AMB_TEMP_0 0;
BA_ "GenSigType" SG_ 2672295937 BATT_boardADC_SHUNT_TEMP_1 0;
BA_ "GenSigType" SG_ 2672295937 BATT_boardADC_FET_TEMP_1 0;
BA_ "GenSigType" SG_ 2672295937 BATT_boardADC_AMB_TEMP_1 0;
BA_ "GenSigType" SG_ 2672295938 BATT_boardADC_SHUNT_TEMP_2 0;
BA_ "GenSigType" SG_ 2672295938 BATT_boardADC_FET_TEMP_2 0;
BA_ "GenSigType" SG_ 2672295938 BATT_boardADC_AMB_TEMP_2 0;
BA_ "GenSigType" SG_ 2672295939 BATT_boardADC_SHUNT_TEMP_3 0;
BA_ "GenSigType" SG_ 2672295939 BATT_boardADC_FET_TEMP_3 0;
BA_ "GenSigType" SG_ 2672295939 BATT_boardADC_AMB_TEMP_3 0;
BA_ "GenSigType" SG_ 2672295940 BATT_boardADC_SHUNT_TEMP_4 0;
BA_ "GenSigType" SG_ 2672295940 BATT_boardADC_FET_TEMP_4 0;
BA_ "GenSigType" SG_ 2672295940 BATT_boardADC_AMB_TEMP_4 0;
BA_ "GenSigType" SG_ 2672295941 BATT_boardADC_SHUNT_TEMP_5 0;
BA_ "GenSigType" SG_ 2672295941 BATT_boardADC_FET_TEMP_5 0;
BA_ "GenSigType" SG_ 2672295941 BATT_boardADC_AMB_TEMP_5 0;
BA_ "GenSigType" SG_ 2672295942 BATT_boardADC_SHUNT_TEMP_6 0;
BA_ "GenSigType" SG_ 2672295942 BATT_boardADC_FET_TEMP_6 0;
BA_ "GenSigType" SG_ 2672295942 BATT_boardADC_AMB_TEMP_6 0;
BA_ "GenSigType" SG_ 2672295943 BATT_boardADC_SHUNT_TEMP_7 0;
BA_ "GenSigType" SG_ 2672295943 BATT_boardADC_FET_TEMP_7 0;
BA_ "GenSigType" SG_ 2672295943 BATT_boardADC_AMB_TEMP_7 0;
BA_ "GenSigType" SG_ 2672295944 BATT_boardADC_SHUNT_TEMP_8 0;
BA_ "GenSigType" SG_ 2672295944 BATT_boardADC_FET_TEMP_8 0;
BA_ "GenSigType" SG_ 2672295944 BATT_boardADC_AMB_TEMP_8 0;
BA_ "GenSigType" SG_ 2672295945 BATT_boardADC_SHUNT_TEMP_9 0;
BA_ "GenSigType" SG_ 2672295945 BATT_boardADC_FET_TEMP_9 0;
BA_ "GenSigType" SG_ 2672295945 BATT_boardADC_AMB_TEMP_9 0;
BA_ "GenSigType" SG_ 2672295946 BATT_boardADC_SHUNT_TEMP_10 0;
BA_ "GenSigType" SG_ 2672295946 BATT_boardADC_FET_TEMP_10 0;
BA_ "GenSigType" SG_ 2672295946 BATT_boardADC_AMB_TEMP_10 0;
BA_ "GenSigType" SG_ 2672295947 BATT_boardADC_SHUNT_TEMP_11 0;
BA_ "GenSigType" SG_ 2672295947 BATT_boardADC_FET_TEMP_11 0;
BA_ "GenSigType" SG_ 2672295947 BATT_boardADC_AMB_TEMP_11 0;
BA_ "GenSigSNA" SG_ 2626813958 BATT_HrnsImpDelta_0_6 65535;
BA_ "GenSigSNA" SG_ 2626813958 BATT_HrnsImpDelta_1_6 65535;
BA_ "GenSigSNA" SG_ 2626813958 BATT_HrnsImpDelta_3_6 65535;
BA_ "GenSigSNA" SG_ 2626813958 BATT_HrnsImpDelta_2_6 65535;
BA_ "GenSigSNA" SG_ 2626813959 BATT_HrnsImpDelta_3_7 65535;
BA_ "GenSigSNA" SG_ 2626813959 BATT_HrnsImpDelta_0_7 65535;
BA_ "GenSigSNA" SG_ 2626813959 BATT_HrnsImpDelta_2_7 65535;
BA_ "GenSigSNA" SG_ 2626813959 BATT_HrnsImpDelta_1_7 65535;
BA_ "GenSigSNA" SG_ 2626813960 BATT_HrnsImpDelta_2_8 65535;
BA_ "GenSigSNA" SG_ 2626813960 BATT_HrnsImpDelta_3_8 65535;
BA_ "GenSigSNA" SG_ 2626813960 BATT_HrnsImpDelta_1_8 65535;
BA_ "GenSigSNA" SG_ 2626813960 BATT_HrnsImpDelta_0_8 65535;
BA_ "GenSigSNA" SG_ 2626813961 BATT_HrnsImpDelta_2_9 65535;
BA_ "GenSigSNA" SG_ 2626813961 BATT_HrnsImpDelta_1_9 65535;
BA_ "GenSigSNA" SG_ 2626813961 BATT_HrnsImpDelta_0_9 65535;
BA_ "GenSigSNA" SG_ 2626813961 BATT_HrnsImpDelta_3_9 65535;
BA_ "GenSigSNA" SG_ 2626813962 BATT_HrnsImpDelta_0_10 65535;
BA_ "GenSigSNA" SG_ 2626813962 BATT_HrnsImpDelta_2_10 65535;
BA_ "GenSigSNA" SG_ 2626813962 BATT_HrnsImpDelta_1_10 65535;
BA_ "GenSigSNA" SG_ 2626813962 BATT_HrnsImpDelta_3_10 65535;
BA_ "GenSigSNA" SG_ 2626813963 BATT_HrnsImpDelta_2_11 65535;
BA_ "GenSigSNA" SG_ 2626813963 BATT_HrnsImpDelta_1_11 65535;
BA_ "GenSigSNA" SG_ 2626813963 BATT_HrnsImpDelta_3_11 65535;
BA_ "GenSigSNA" SG_ 2626813963 BATT_HrnsImpDelta_0_11 65535;
BA_ "GenSigSNA" SG_ 2626818048 BATT_HrnsImpDelta_4_0 65535;
BA_ "GenSigSNA" SG_ 2626818048 BATT_HrnsImpDelta_6_0 65535;
BA_ "GenSigSNA" SG_ 2626818048 BATT_HrnsImpDelta_5_0 65535;
BA_ "GenSigSNA" SG_ 2626818048 BATT_HrnsImpDelta_7_0 65535;
BA_ "GenSigSNA" SG_ 2626818049 BATT_HrnsImpDelta_6_1 65535;
BA_ "GenSigSNA" SG_ 2626818049 BATT_HrnsImpDelta_5_1 65535;
BA_ "GenSigSNA" SG_ 2626818049 BATT_HrnsImpDelta_4_1 65535;
BA_ "GenSigSNA" SG_ 2626818049 BATT_HrnsImpDelta_7_1 65535;
BA_ "GenSigSNA" SG_ 2626818050 BATT_HrnsImpDelta_7_2 65535;
BA_ "GenSigSNA" SG_ 2626818050 BATT_HrnsImpDelta_6_2 65535;
BA_ "GenSigSNA" SG_ 2626818050 BATT_HrnsImpDelta_5_2 65535;
BA_ "GenSigSNA" SG_ 2626818050 BATT_HrnsImpDelta_4_2 65535;
BA_ "GenSigSNA" SG_ 2626818051 BATT_HrnsImpDelta_5_3 65535;
BA_ "GenSigSNA" SG_ 2626818051 BATT_HrnsImpDelta_4_3 65535;
BA_ "GenSigSNA" SG_ 2626818051 BATT_HrnsImpDelta_7_3 65535;
BA_ "GenSigSNA" SG_ 2626818051 BATT_HrnsImpDelta_6_3 65535;
BA_ "GenSigSNA" SG_ 2626818052 BATT_HrnsImpDelta_7_4 65535;
BA_ "GenSigSNA" SG_ 2626818052 BATT_HrnsImpDelta_6_4 65535;
BA_ "GenSigSNA" SG_ 2626818052 BATT_HrnsImpDelta_5_4 65535;
BA_ "GenSigSNA" SG_ 2626818052 BATT_HrnsImpDelta_4_4 65535;
BA_ "GenSigSNA" SG_ 2626818053 BATT_HrnsImpDelta_5_5 65535;
BA_ "GenSigSNA" SG_ 2626818053 BATT_HrnsImpDelta_4_5 65535;
BA_ "GenSigSNA" SG_ 2626818053 BATT_HrnsImpDelta_7_5 65535;
BA_ "GenSigSNA" SG_ 2626818053 BATT_HrnsImpDelta_6_5 65535;
BA_ "GenSigSNA" SG_ 2626818054 BATT_HrnsImpDelta_4_6 65535;
BA_ "GenSigSNA" SG_ 2626818054 BATT_HrnsImpDelta_7_6 65535;
BA_ "GenSigSNA" SG_ 2626818054 BATT_HrnsImpDelta_6_6 65535;
BA_ "GenSigSNA" SG_ 2626818054 BATT_HrnsImpDelta_5_6 65535;
BA_ "GenSigSNA" SG_ 2626818055 BATT_HrnsImpDelta_7_7 65535;
BA_ "GenSigSNA" SG_ 2626818055 BATT_HrnsImpDelta_6_7 65535;
BA_ "GenSigSNA" SG_ 2626818055 BATT_HrnsImpDelta_4_7 65535;
BA_ "GenSigSNA" SG_ 2626818055 BATT_HrnsImpDelta_5_7 65535;
BA_ "GenSigSNA" SG_ 2626818056 BATT_HrnsImpDelta_7_8 65535;
BA_ "GenSigSNA" SG_ 2626818056 BATT_HrnsImpDelta_6_8 65535;
BA_ "GenSigSNA" SG_ 2626818056 BATT_HrnsImpDelta_4_8 65535;
BA_ "GenSigSNA" SG_ 2626818056 BATT_HrnsImpDelta_5_8 65535;
BA_ "GenSigSNA" SG_ 2626818057 BATT_HrnsImpDelta_4_9 65535;
BA_ "GenSigSNA" SG_ 2626818057 BATT_HrnsImpDelta_6_9 65535;
BA_ "GenSigSNA" SG_ 2626818057 BATT_HrnsImpDelta_7_9 65535;
BA_ "GenSigSNA" SG_ 2626818057 BATT_HrnsImpDelta_5_9 65535;
BA_ "GenSigSNA" SG_ 2626818058 BATT_HrnsImpDelta_6_10 65535;
BA_ "GenSigSNA" SG_ 2626818058 BATT_HrnsImpDelta_5_10 65535;
BA_ "GenSigSNA" SG_ 2626818058 BATT_HrnsImpDelta_4_10 65535;
BA_ "GenSigSNA" SG_ 2626818058 BATT_HrnsImpDelta_7_10 65535;
BA_ "GenSigSNA" SG_ 2626818059 BATT_HrnsImpDelta_7_11 65535;
BA_ "GenSigSNA" SG_ 2626818059 BATT_HrnsImpDelta_6_11 65535;
BA_ "GenSigSNA" SG_ 2626818059 BATT_HrnsImpDelta_5_11 65535;
BA_ "GenSigSNA" SG_ 2626818059 BATT_HrnsImpDelta_4_11 65535;
BA_ "GenSigSNA" SG_ 2626822144 BATT_HrnsImpDelta_8_0 65535;
BA_ "GenSigSNA" SG_ 2626822144 BATT_HrnsImpDelta_9_0 65535;
BA_ "GenSigSNA" SG_ 2626822144 BATT_HrnsImpDelta_11_0 65535;
BA_ "GenSigSNA" SG_ 2626822144 BATT_HrnsImpDelta_10_0 65535;
BA_ "GenSigSNA" SG_ 2626822145 BATT_HrnsImpDelta_11_1 65535;
BA_ "GenSigSNA" SG_ 2626822145 BATT_HrnsImpDelta_9_1 65535;
BA_ "GenSigSNA" SG_ 2626822145 BATT_HrnsImpDelta_8_1 65535;
BA_ "GenSigSNA" SG_ 2626822145 BATT_HrnsImpDelta_10_1 65535;
BA_ "GenSigSNA" SG_ 2626822146 BATT_HrnsImpDelta_11_2 65535;
BA_ "GenSigSNA" SG_ 2626822146 BATT_HrnsImpDelta_10_2 65535;
BA_ "GenSigSNA" SG_ 2626822146 BATT_HrnsImpDelta_8_2 65535;
BA_ "GenSigSNA" SG_ 2626822146 BATT_HrnsImpDelta_9_2 65535;
BA_ "GenSigSNA" SG_ 2626822147 BATT_HrnsImpDelta_11_3 65535;
BA_ "GenSigSNA" SG_ 2626822147 BATT_HrnsImpDelta_10_3 65535;
BA_ "GenSigSNA" SG_ 2626822147 BATT_HrnsImpDelta_8_3 65535;
BA_ "GenSigSNA" SG_ 2626822147 BATT_HrnsImpDelta_9_3 65535;
BA_ "GenSigSNA" SG_ 2626822148 BATT_HrnsImpDelta_9_4 65535;
BA_ "GenSigSNA" SG_ 2626822148 BATT_HrnsImpDelta_11_4 65535;
BA_ "GenSigSNA" SG_ 2626822148 BATT_HrnsImpDelta_10_4 65535;
BA_ "GenSigSNA" SG_ 2626822148 BATT_HrnsImpDelta_8_4 65535;
BA_ "GenSigSNA" SG_ 2626822149 BATT_HrnsImpDelta_10_5 65535;
BA_ "GenSigSNA" SG_ 2626822149 BATT_HrnsImpDelta_8_5 65535;
BA_ "GenSigSNA" SG_ 2626822149 BATT_HrnsImpDelta_9_5 65535;
BA_ "GenSigSNA" SG_ 2626822149 BATT_HrnsImpDelta_11_5 65535;
BA_ "GenSigSNA" SG_ 2626822150 BATT_HrnsImpDelta_10_6 65535;
BA_ "GenSigSNA" SG_ 2626822150 BATT_HrnsImpDelta_11_6 65535;
BA_ "GenSigSNA" SG_ 2626822150 BATT_HrnsImpDelta_9_6 65535;
BA_ "GenSigSNA" SG_ 2626822150 BATT_HrnsImpDelta_8_6 65535;
BA_ "GenSigSNA" SG_ 2626822151 BATT_HrnsImpDelta_8_7 65535;
BA_ "GenSigSNA" SG_ 2626822151 BATT_HrnsImpDelta_11_7 65535;
BA_ "GenSigSNA" SG_ 2626822151 BATT_HrnsImpDelta_10_7 65535;
BA_ "GenSigSNA" SG_ 2626822151 BATT_HrnsImpDelta_9_7 65535;
BA_ "GenSigSNA" SG_ 2626822152 BATT_HrnsImpDelta_10_8 65535;
BA_ "GenSigSNA" SG_ 2626822152 BATT_HrnsImpDelta_11_8 65535;
BA_ "GenSigSNA" SG_ 2626822152 BATT_HrnsImpDelta_9_8 65535;
BA_ "GenSigSNA" SG_ 2626822152 BATT_HrnsImpDelta_8_8 65535;
BA_ "GenSigSNA" SG_ 2626822153 BATT_HrnsImpDelta_8_9 65535;
BA_ "GenSigSNA" SG_ 2626822153 BATT_HrnsImpDelta_9_9 65535;
BA_ "GenSigSNA" SG_ 2626822153 BATT_HrnsImpDelta_11_9 65535;
BA_ "GenSigSNA" SG_ 2626822153 BATT_HrnsImpDelta_10_9 65535;
BA_ "GenSigSNA" SG_ 2626822154 BATT_HrnsImpDelta_11_10 65535;
BA_ "GenSigSNA" SG_ 2626822154 BATT_HrnsImpDelta_8_10 65535;
BA_ "GenSigSNA" SG_ 2626822154 BATT_HrnsImpDelta_10_10 65535;
BA_ "GenSigSNA" SG_ 2626822154 BATT_HrnsImpDelta_9_10 65535;
BA_ "GenSigSNA" SG_ 2626822155 BATT_HrnsImpDelta_10_11 65535;
BA_ "GenSigSNA" SG_ 2626822155 BATT_HrnsImpDelta_8_11 65535;
BA_ "GenSigSNA" SG_ 2626822155 BATT_HrnsImpDelta_9_11 65535;
BA_ "GenSigSNA" SG_ 2626822155 BATT_HrnsImpDelta_11_11 65535;
BA_ "GenSigSNA" SG_ 2626826240 BATT_HrnsImpDelta_12_0 65535;
BA_ "GenSigSNA" SG_ 2626826240 BATT_HrnsImpDelta_14_0 65535;
BA_ "GenSigSNA" SG_ 2626826240 BATT_HrnsImpDelta_13_0 65535;
BA_ "GenSigSNA" SG_ 2626826241 BATT_HrnsImpDelta_14_1 65535;
BA_ "GenSigSNA" SG_ 2626826241 BATT_HrnsImpDelta_13_1 65535;
BA_ "GenSigSNA" SG_ 2626826241 BATT_HrnsImpDelta_12_1 65535;
BA_ "GenSigSNA" SG_ 2626826242 BATT_HrnsImpDelta_14_2 65535;
BA_ "GenSigSNA" SG_ 2626826242 BATT_HrnsImpDelta_13_2 65535;
BA_ "GenSigSNA" SG_ 2626826242 BATT_HrnsImpDelta_12_2 65535;
BA_ "GenSigSNA" SG_ 2626826243 BATT_HrnsImpDelta_12_3 65535;
BA_ "GenSigSNA" SG_ 2626826243 BATT_HrnsImpDelta_14_3 65535;
BA_ "GenSigSNA" SG_ 2626826243 BATT_HrnsImpDelta_13_3 65535;
BA_ "GenSigSNA" SG_ 2626826244 BATT_HrnsImpDelta_13_4 65535;
BA_ "GenSigSNA" SG_ 2626826244 BATT_HrnsImpDelta_12_4 65535;
BA_ "GenSigSNA" SG_ 2626826244 BATT_HrnsImpDelta_14_4 65535;
BA_ "GenSigSNA" SG_ 2626826245 BATT_HrnsImpDelta_14_5 65535;
BA_ "GenSigSNA" SG_ 2626826245 BATT_HrnsImpDelta_13_5 65535;
BA_ "GenSigSNA" SG_ 2626826245 BATT_HrnsImpDelta_12_5 65535;
BA_ "GenSigSNA" SG_ 2626826246 BATT_HrnsImpDelta_14_6 65535;
BA_ "GenSigSNA" SG_ 2626826246 BATT_HrnsImpDelta_13_6 65535;
BA_ "GenSigSNA" SG_ 2626826246 BATT_HrnsImpDelta_12_6 65535;
BA_ "GenSigSNA" SG_ 2626826247 BATT_HrnsImpDelta_14_7 65535;
BA_ "GenSigSNA" SG_ 2626826247 BATT_HrnsImpDelta_13_7 65535;
BA_ "GenSigSNA" SG_ 2626826247 BATT_HrnsImpDelta_12_7 65535;
BA_ "GenSigSNA" SG_ 2626826248 BATT_HrnsImpDelta_14_8 65535;
BA_ "GenSigSNA" SG_ 2626826248 BATT_HrnsImpDelta_13_8 65535;
BA_ "GenSigSNA" SG_ 2626826248 BATT_HrnsImpDelta_12_8 65535;
BA_ "GenSigSNA" SG_ 2626826249 BATT_HrnsImpDelta_14_9 65535;
BA_ "GenSigSNA" SG_ 2626826249 BATT_HrnsImpDelta_13_9 65535;
BA_ "GenSigSNA" SG_ 2626826249 BATT_HrnsImpDelta_12_9 65535;
BA_ "GenSigSNA" SG_ 2626826250 BATT_HrnsImpDelta_14_10 65535;
BA_ "GenSigSNA" SG_ 2626826250 BATT_HrnsImpDelta_13_10 65535;
BA_ "GenSigSNA" SG_ 2626826250 BATT_HrnsImpDelta_12_10 65535;
BA_ "GenSigSNA" SG_ 2626826251 BATT_HrnsImpDelta_14_11 65535;
BA_ "GenSigSNA" SG_ 2626826251 BATT_HrnsImpDelta_13_11 65535;
BA_ "GenSigSNA" SG_ 2626826251 BATT_HrnsImpDelta_12_11 65535;
BA_ "GenSigSNA" SG_ 2630090752 BATT_socBrick04_0 1023;
BA_ "GenSigSNA" SG_ 2630090752 BATT_socBrick03_0 1023;
BA_ "GenSigSNA" SG_ 2630090752 BATT_socBrick02_0 1023;
BA_ "GenSigSNA" SG_ 2630090752 BATT_socBrick01_0 1023;
BA_ "GenSigSNA" SG_ 2630090753 BATT_socBrick04_1 1023;
BA_ "GenSigSNA" SG_ 2630090753 BATT_socBrick03_1 1023;
BA_ "GenSigSNA" SG_ 2630090753 BATT_socBrick02_1 1023;
BA_ "GenSigSNA" SG_ 2630090753 BATT_socBrick01_1 1023;
BA_ "GenSigSNA" SG_ 2630090754 BATT_socBrick04_2 1023;
BA_ "GenSigSNA" SG_ 2630090754 BATT_socBrick03_2 1023;
BA_ "GenSigSNA" SG_ 2630090754 BATT_socBrick02_2 1023;
BA_ "GenSigSNA" SG_ 2630090754 BATT_socBrick01_2 1023;
BA_ "GenSigSNA" SG_ 2630090755 BATT_socBrick04_3 1023;
BA_ "GenSigSNA" SG_ 2630090755 BATT_socBrick03_3 1023;
BA_ "GenSigSNA" SG_ 2630090755 BATT_socBrick02_3 1023;
BA_ "GenSigSNA" SG_ 2630090755 BATT_socBrick01_3 1023;
BA_ "GenSigSNA" SG_ 2630090756 BATT_socBrick04_4 1023;
BA_ "GenSigSNA" SG_ 2630090756 BATT_socBrick03_4 1023;
BA_ "GenSigSNA" SG_ 2630090756 BATT_socBrick02_4 1023;
BA_ "GenSigSNA" SG_ 2630090756 BATT_socBrick01_4 1023;
BA_ "GenSigSNA" SG_ 2630090757 BATT_socBrick04_5 1023;
BA_ "GenSigSNA" SG_ 2630090757 BATT_socBrick03_5 1023;
BA_ "GenSigSNA" SG_ 2630090757 BATT_socBrick02_5 1023;
BA_ "GenSigSNA" SG_ 2630090757 BATT_socBrick01_5 1023;
BA_ "GenSigSNA" SG_ 2630090758 BATT_socBrick04_6 1023;
BA_ "GenSigSNA" SG_ 2630090758 BATT_socBrick03_6 1023;
BA_ "GenSigSNA" SG_ 2630090758 BATT_socBrick02_6 1023;
BA_ "GenSigSNA" SG_ 2630090758 BATT_socBrick01_6 1023;
BA_ "GenSigSNA" SG_ 2630090759 BATT_socBrick04_7 1023;
BA_ "GenSigSNA" SG_ 2630090759 BATT_socBrick03_7 1023;
BA_ "GenSigSNA" SG_ 2630090759 BATT_socBrick02_7 1023;
BA_ "GenSigSNA" SG_ 2630090759 BATT_socBrick01_7 1023;
BA_ "GenSigSNA" SG_ 2630090760 BATT_socBrick04_8 1023;
BA_ "GenSigSNA" SG_ 2630090760 BATT_socBrick03_8 1023;
BA_ "GenSigSNA" SG_ 2630090760 BATT_socBrick02_8 1023;
BA_ "GenSigSNA" SG_ 2630090760 BATT_socBrick01_8 1023;
BA_ "GenSigSNA" SG_ 2630090761 BATT_socBrick04_9 1023;
BA_ "GenSigSNA" SG_ 2630090761 BATT_socBrick03_9 1023;
BA_ "GenSigSNA" SG_ 2630090761 BATT_socBrick02_9 1023;
BA_ "GenSigSNA" SG_ 2630090761 BATT_socBrick01_9 1023;
BA_ "GenSigSNA" SG_ 2630090762 BATT_socBrick04_10 1023;
BA_ "GenSigSNA" SG_ 2630090762 BATT_socBrick03_10 1023;
BA_ "GenSigSNA" SG_ 2630090762 BATT_socBrick02_10 1023;
BA_ "GenSigSNA" SG_ 2630090762 BATT_socBrick01_10 1023;
BA_ "GenSigSNA" SG_ 2630090763 BATT_socBrick04_11 1023;
BA_ "GenSigSNA" SG_ 2630090763 BATT_socBrick03_11 1023;
BA_ "GenSigSNA" SG_ 2630090763 BATT_socBrick02_11 1023;
BA_ "GenSigSNA" SG_ 2630090763 BATT_socBrick01_11 1023;
BA_ "GenSigSNA" SG_ 2630352896 BATT_socBrick08_0 1023;
BA_ "GenSigSNA" SG_ 2630352896 BATT_socBrick07_0 1023;
BA_ "GenSigSNA" SG_ 2630352896 BATT_socBrick06_0 1023;
BA_ "GenSigSNA" SG_ 2630352896 BATT_socBrick05_0 1023;
BA_ "GenSigSNA" SG_ 2630352897 BATT_socBrick08_1 1023;
BA_ "GenSigSNA" SG_ 2630352897 BATT_socBrick07_1 1023;
BA_ "GenSigSNA" SG_ 2630352897 BATT_socBrick06_1 1023;
BA_ "GenSigSNA" SG_ 2630352897 BATT_socBrick05_1 1023;
BA_ "GenSigSNA" SG_ 2630352898 BATT_socBrick08_2 1023;
BA_ "GenSigSNA" SG_ 2630352898 BATT_socBrick07_2 1023;
BA_ "GenSigSNA" SG_ 2630352898 BATT_socBrick06_2 1023;
BA_ "GenSigSNA" SG_ 2630352898 BATT_socBrick05_2 1023;
BA_ "GenSigSNA" SG_ 2630352899 BATT_socBrick08_3 1023;
BA_ "GenSigSNA" SG_ 2630352899 BATT_socBrick07_3 1023;
BA_ "GenSigSNA" SG_ 2630352899 BATT_socBrick06_3 1023;
BA_ "GenSigSNA" SG_ 2630352899 BATT_socBrick05_3 1023;
BA_ "GenSigSNA" SG_ 2630352900 BATT_socBrick08_4 1023;
BA_ "GenSigSNA" SG_ 2630352900 BATT_socBrick07_4 1023;
BA_ "GenSigSNA" SG_ 2630352900 BATT_socBrick06_4 1023;
BA_ "GenSigSNA" SG_ 2630352900 BATT_socBrick05_4 1023;
BA_ "GenSigSNA" SG_ 2630352901 BATT_socBrick08_5 1023;
BA_ "GenSigSNA" SG_ 2630352901 BATT_socBrick07_5 1023;
BA_ "GenSigSNA" SG_ 2630352901 BATT_socBrick06_5 1023;
BA_ "GenSigSNA" SG_ 2630352901 BATT_socBrick05_5 1023;
BA_ "GenSigSNA" SG_ 2630352902 BATT_socBrick08_6 1023;
BA_ "GenSigSNA" SG_ 2630352902 BATT_socBrick07_6 1023;
BA_ "GenSigSNA" SG_ 2630352902 BATT_socBrick06_6 1023;
BA_ "GenSigSNA" SG_ 2630352902 BATT_socBrick05_6 1023;
BA_ "GenSigSNA" SG_ 2630352903 BATT_socBrick08_7 1023;
BA_ "GenSigSNA" SG_ 2630352903 BATT_socBrick07_7 1023;
BA_ "GenSigSNA" SG_ 2630352903 BATT_socBrick06_7 1023;
BA_ "GenSigSNA" SG_ 2630352903 BATT_socBrick05_7 1023;
BA_ "GenSigSNA" SG_ 2630352904 BATT_socBrick08_8 1023;
BA_ "GenSigSNA" SG_ 2630352904 BATT_socBrick07_8 1023;
BA_ "GenSigSNA" SG_ 2630352904 BATT_socBrick06_8 1023;
BA_ "GenSigSNA" SG_ 2630352904 BATT_socBrick05_8 1023;
BA_ "GenSigSNA" SG_ 2630352905 BATT_socBrick08_9 1023;
BA_ "GenSigSNA" SG_ 2630352905 BATT_socBrick07_9 1023;
BA_ "GenSigSNA" SG_ 2630352905 BATT_socBrick06_9 1023;
BA_ "GenSigSNA" SG_ 2630352905 BATT_socBrick05_9 1023;
BA_ "GenSigSNA" SG_ 2630352906 BATT_socBrick08_10 1023;
BA_ "GenSigSNA" SG_ 2630352906 BATT_socBrick07_10 1023;
BA_ "GenSigSNA" SG_ 2630352906 BATT_socBrick06_10 1023;
BA_ "GenSigSNA" SG_ 2630352906 BATT_socBrick05_10 1023;
BA_ "GenSigSNA" SG_ 2630352907 BATT_socBrick08_11 1023;
BA_ "GenSigSNA" SG_ 2630352907 BATT_socBrick07_11 1023;
BA_ "GenSigSNA" SG_ 2630352907 BATT_socBrick06_11 1023;
BA_ "GenSigSNA" SG_ 2630352907 BATT_socBrick05_11 1023;
BA_ "GenSigSNA" SG_ 2630615040 BATT_socBrick12_0 1023;
BA_ "GenSigSNA" SG_ 2630615040 BATT_socBrick11_0 1023;
BA_ "GenSigSNA" SG_ 2630615040 BATT_socBrick09_0 1023;
BA_ "GenSigSNA" SG_ 2630615040 BATT_socBrick10_0 1023;
BA_ "GenSigSNA" SG_ 2630615041 BATT_socBrick12_1 1023;
BA_ "GenSigSNA" SG_ 2630615041 BATT_socBrick11_1 1023;
BA_ "GenSigSNA" SG_ 2630615041 BATT_socBrick09_1 1023;
BA_ "GenSigSNA" SG_ 2630615041 BATT_socBrick10_1 1023;
BA_ "GenSigSNA" SG_ 2630615042 BATT_socBrick12_2 1023;
BA_ "GenSigSNA" SG_ 2630615042 BATT_socBrick11_2 1023;
BA_ "GenSigSNA" SG_ 2630615042 BATT_socBrick09_2 1023;
BA_ "GenSigSNA" SG_ 2630615042 BATT_socBrick10_2 1023;
BA_ "GenSigSNA" SG_ 2630615043 BATT_socBrick12_3 1023;
BA_ "GenSigSNA" SG_ 2630615043 BATT_socBrick11_3 1023;
BA_ "GenSigSNA" SG_ 2630615043 BATT_socBrick09_3 1023;
BA_ "GenSigSNA" SG_ 2630615043 BATT_socBrick10_3 1023;
BA_ "GenSigSNA" SG_ 2630615044 BATT_socBrick12_4 1023;
BA_ "GenSigSNA" SG_ 2630615044 BATT_socBrick11_4 1023;
BA_ "GenSigSNA" SG_ 2630615044 BATT_socBrick09_4 1023;
BA_ "GenSigSNA" SG_ 2630615044 BATT_socBrick10_4 1023;
BA_ "GenSigSNA" SG_ 2630615045 BATT_socBrick12_5 1023;
BA_ "GenSigSNA" SG_ 2630615045 BATT_socBrick11_5 1023;
BA_ "GenSigSNA" SG_ 2630615045 BATT_socBrick09_5 1023;
BA_ "GenSigSNA" SG_ 2630615045 BATT_socBrick10_5 1023;
BA_ "GenSigSNA" SG_ 2630615046 BATT_socBrick12_6 1023;
BA_ "GenSigSNA" SG_ 2630615046 BATT_socBrick11_6 1023;
BA_ "GenSigSNA" SG_ 2630615046 BATT_socBrick09_6 1023;
BA_ "GenSigSNA" SG_ 2630615046 BATT_socBrick10_6 1023;
BA_ "GenSigSNA" SG_ 2630615047 BATT_socBrick12_7 1023;
BA_ "GenSigSNA" SG_ 2630615047 BATT_socBrick11_7 1023;
BA_ "GenSigSNA" SG_ 2630615047 BATT_socBrick09_7 1023;
BA_ "GenSigSNA" SG_ 2630615047 BATT_socBrick10_7 1023;
BA_ "GenSigSNA" SG_ 2630615048 BATT_socBrick12_8 1023;
BA_ "GenSigSNA" SG_ 2630615048 BATT_socBrick11_8 1023;
BA_ "GenSigSNA" SG_ 2630615048 BATT_socBrick09_8 1023;
BA_ "GenSigSNA" SG_ 2630615048 BATT_socBrick10_8 1023;
BA_ "GenSigSNA" SG_ 2630615049 BATT_socBrick12_9 1023;
BA_ "GenSigSNA" SG_ 2630615049 BATT_socBrick11_9 1023;
BA_ "GenSigSNA" SG_ 2630615049 BATT_socBrick09_9 1023;
BA_ "GenSigSNA" SG_ 2630615049 BATT_socBrick10_9 1023;
BA_ "GenSigSNA" SG_ 2630615050 BATT_socBrick12_10 1023;
BA_ "GenSigSNA" SG_ 2630615050 BATT_socBrick11_10 1023;
BA_ "GenSigSNA" SG_ 2630615050 BATT_socBrick09_10 1023;
BA_ "GenSigSNA" SG_ 2630615050 BATT_socBrick10_10 1023;
BA_ "GenSigSNA" SG_ 2630615051 BATT_socBrick12_11 1023;
BA_ "GenSigSNA" SG_ 2630615051 BATT_socBrick11_11 1023;
BA_ "GenSigSNA" SG_ 2630615051 BATT_socBrick09_11 1023;
BA_ "GenSigSNA" SG_ 2630615051 BATT_socBrick10_11 1023;
BA_ "GenSigSNA" SG_ 2630877184 BATT_socBrick14_0 1023;
BA_ "GenSigSNA" SG_ 2630877184 BATT_socBrick13_0 1023;
BA_ "GenSigSNA" SG_ 2630877185 BATT_socBrick14_1 1023;
BA_ "GenSigSNA" SG_ 2630877185 BATT_socBrick13_1 1023;
BA_ "GenSigSNA" SG_ 2630877186 BATT_socBrick14_2 1023;
BA_ "GenSigSNA" SG_ 2630877186 BATT_socBrick13_2 1023;
BA_ "GenSigSNA" SG_ 2630877187 BATT_socBrick14_3 1023;
BA_ "GenSigSNA" SG_ 2630877187 BATT_socBrick13_3 1023;
BA_ "GenSigSNA" SG_ 2630877188 BATT_socBrick14_4 1023;
BA_ "GenSigSNA" SG_ 2630877188 BATT_socBrick13_4 1023;
BA_ "GenSigSNA" SG_ 2630877189 BATT_socBrick14_5 1023;
BA_ "GenSigSNA" SG_ 2630877189 BATT_socBrick13_5 1023;
BA_ "GenSigSNA" SG_ 2630877190 BATT_socBrick14_6 1023;
BA_ "GenSigSNA" SG_ 2630877190 BATT_socBrick13_6 1023;
BA_ "GenSigSNA" SG_ 2630877191 BATT_socBrick14_7 1023;
BA_ "GenSigSNA" SG_ 2630877191 BATT_socBrick13_7 1023;
BA_ "GenSigSNA" SG_ 2630877192 BATT_socBrick14_8 1023;
BA_ "GenSigSNA" SG_ 2630877192 BATT_socBrick13_8 1023;
BA_ "GenSigSNA" SG_ 2630877193 BATT_socBrick14_9 1023;
BA_ "GenSigSNA" SG_ 2630877193 BATT_socBrick13_9 1023;
BA_ "GenSigSNA" SG_ 2630877194 BATT_socBrick14_10 1023;
BA_ "GenSigSNA" SG_ 2630877194 BATT_socBrick13_10 1023;
BA_ "GenSigSNA" SG_ 2630877195 BATT_socBrick14_11 1023;
BA_ "GenSigSNA" SG_ 2630877195 BATT_socBrick13_11 1023;
VAL_ 2630090752 BATT_socBrick04_0  1023 "SNA"  ;
VAL_ 2630090752 BATT_socBrick03_0  1023 "SNA"  ;
VAL_ 2630090752 BATT_socBrick02_0  1023 "SNA"  ;
VAL_ 2630090752 BATT_socBrick01_0  1023 "SNA"  ;
VAL_ 2630090753 BATT_socBrick04_1  1023 "SNA"  ;
VAL_ 2630090753 BATT_socBrick03_1  1023 "SNA"  ;
VAL_ 2630090753 BATT_socBrick02_1  1023 "SNA"  ;
VAL_ 2630090753 BATT_socBrick01_1  1023 "SNA"  ;
VAL_ 2630090754 BATT_socBrick04_2  1023 "SNA"  ;
VAL_ 2630090754 BATT_socBrick03_2  1023 "SNA"  ;
VAL_ 2630090754 BATT_socBrick02_2  1023 "SNA"  ;
VAL_ 2630090754 BATT_socBrick01_2  1023 "SNA"  ;
VAL_ 2630090755 BATT_socBrick04_3  1023 "SNA"  ;
VAL_ 2630090755 BATT_socBrick03_3  1023 "SNA"  ;
VAL_ 2630090755 BATT_socBrick02_3  1023 "SNA"  ;
VAL_ 2630090755 BATT_socBrick01_3  1023 "SNA"  ;
VAL_ 2630090756 BATT_socBrick04_4  1023 "SNA"  ;
VAL_ 2630090756 BATT_socBrick03_4  1023 "SNA"  ;
VAL_ 2630090756 BATT_socBrick02_4  1023 "SNA"  ;
VAL_ 2630090756 BATT_socBrick01_4  1023 "SNA"  ;
VAL_ 2630090757 BATT_socBrick04_5  1023 "SNA"  ;
VAL_ 2630090757 BATT_socBrick03_5  1023 "SNA"  ;
VAL_ 2630090757 BATT_socBrick02_5  1023 "SNA"  ;
VAL_ 2630090757 BATT_socBrick01_5  1023 "SNA"  ;
VAL_ 2630090758 BATT_socBrick04_6  1023 "SNA"  ;
VAL_ 2630090758 BATT_socBrick03_6  1023 "SNA"  ;
VAL_ 2630090758 BATT_socBrick02_6  1023 "SNA"  ;
VAL_ 2630090758 BATT_socBrick01_6  1023 "SNA"  ;
VAL_ 2630090759 BATT_socBrick04_7  1023 "SNA"  ;
VAL_ 2630090759 BATT_socBrick03_7  1023 "SNA"  ;
VAL_ 2630090759 BATT_socBrick02_7  1023 "SNA"  ;
VAL_ 2630090759 BATT_socBrick01_7  1023 "SNA"  ;
VAL_ 2630090760 BATT_socBrick04_8  1023 "SNA"  ;
VAL_ 2630090760 BATT_socBrick03_8  1023 "SNA"  ;
VAL_ 2630090760 BATT_socBrick02_8  1023 "SNA"  ;
VAL_ 2630090760 BATT_socBrick01_8  1023 "SNA"  ;
VAL_ 2630090761 BATT_socBrick04_9  1023 "SNA"  ;
VAL_ 2630090761 BATT_socBrick03_9  1023 "SNA"  ;
VAL_ 2630090761 BATT_socBrick02_9  1023 "SNA"  ;
VAL_ 2630090761 BATT_socBrick01_9  1023 "SNA"  ;
VAL_ 2630090762 BATT_socBrick04_10  1023 "SNA"  ;
VAL_ 2630090762 BATT_socBrick03_10  1023 "SNA"  ;
VAL_ 2630090762 BATT_socBrick02_10  1023 "SNA"  ;
VAL_ 2630090762 BATT_socBrick01_10  1023 "SNA"  ;
VAL_ 2630090763 BATT_socBrick04_11  1023 "SNA"  ;
VAL_ 2630090763 BATT_socBrick03_11  1023 "SNA"  ;
VAL_ 2630090763 BATT_socBrick02_11  1023 "SNA"  ;
VAL_ 2630090763 BATT_socBrick01_11  1023 "SNA"  ;
VAL_ 2630352896 BATT_socBrick08_0  1023 "SNA"  ;
VAL_ 2630352896 BATT_socBrick07_0  1023 "SNA"  ;
VAL_ 2630352896 BATT_socBrick06_0  1023 "SNA"  ;
VAL_ 2630352896 BATT_socBrick05_0  1023 "SNA"  ;
VAL_ 2630352897 BATT_socBrick08_1  1023 "SNA"  ;
VAL_ 2630352897 BATT_socBrick07_1  1023 "SNA"  ;
VAL_ 2630352897 BATT_socBrick06_1  1023 "SNA"  ;
VAL_ 2630352897 BATT_socBrick05_1  1023 "SNA"  ;
VAL_ 2630352898 BATT_socBrick08_2  1023 "SNA"  ;
VAL_ 2630352898 BATT_socBrick07_2  1023 "SNA"  ;
VAL_ 2630352898 BATT_socBrick06_2  1023 "SNA"  ;
VAL_ 2630352898 BATT_socBrick05_2  1023 "SNA"  ;
VAL_ 2630352899 BATT_socBrick08_3  1023 "SNA"  ;
VAL_ 2630352899 BATT_socBrick07_3  1023 "SNA"  ;
VAL_ 2630352899 BATT_socBrick06_3  1023 "SNA"  ;
VAL_ 2630352899 BATT_socBrick05_3  1023 "SNA"  ;
VAL_ 2630352900 BATT_socBrick08_4  1023 "SNA"  ;
VAL_ 2630352900 BATT_socBrick07_4  1023 "SNA"  ;
VAL_ 2630352900 BATT_socBrick06_4  1023 "SNA"  ;
VAL_ 2630352900 BATT_socBrick05_4  1023 "SNA"  ;
VAL_ 2630352901 BATT_socBrick08_5  1023 "SNA"  ;
VAL_ 2630352901 BATT_socBrick07_5  1023 "SNA"  ;
VAL_ 2630352901 BATT_socBrick06_5  1023 "SNA"  ;
VAL_ 2630352901 BATT_socBrick05_5  1023 "SNA"  ;
VAL_ 2630352902 BATT_socBrick08_6  1023 "SNA"  ;
VAL_ 2630352902 BATT_socBrick07_6  1023 "SNA"  ;
VAL_ 2630352902 BATT_socBrick06_6  1023 "SNA"  ;
VAL_ 2630352902 BATT_socBrick05_6  1023 "SNA"  ;
VAL_ 2630352903 BATT_socBrick08_7  1023 "SNA"  ;
VAL_ 2630352903 BATT_socBrick07_7  1023 "SNA"  ;
VAL_ 2630352903 BATT_socBrick06_7  1023 "SNA"  ;
VAL_ 2630352903 BATT_socBrick05_7  1023 "SNA"  ;
VAL_ 2630352904 BATT_socBrick08_8  1023 "SNA"  ;
VAL_ 2630352904 BATT_socBrick07_8  1023 "SNA"  ;
VAL_ 2630352904 BATT_socBrick06_8  1023 "SNA"  ;
VAL_ 2630352904 BATT_socBrick05_8  1023 "SNA"  ;
VAL_ 2630352905 BATT_socBrick08_9  1023 "SNA"  ;
VAL_ 2630352905 BATT_socBrick07_9  1023 "SNA"  ;
VAL_ 2630352905 BATT_socBrick06_9  1023 "SNA"  ;
VAL_ 2630352905 BATT_socBrick05_9  1023 "SNA"  ;
VAL_ 2630352906 BATT_socBrick08_10  1023 "SNA"  ;
VAL_ 2630352906 BATT_socBrick07_10  1023 "SNA"  ;
VAL_ 2630352906 BATT_socBrick06_10  1023 "SNA"  ;
VAL_ 2630352906 BATT_socBrick05_10  1023 "SNA"  ;
VAL_ 2630352907 BATT_socBrick08_11  1023 "SNA"  ;
VAL_ 2630352907 BATT_socBrick07_11  1023 "SNA"  ;
VAL_ 2630352907 BATT_socBrick06_11  1023 "SNA"  ;
VAL_ 2630352907 BATT_socBrick05_11  1023 "SNA"  ;
VAL_ 2630615040 BATT_socBrick12_0  1023 "SNA"  ;
VAL_ 2630615040 BATT_socBrick11_0  1023 "SNA"  ;
VAL_ 2630615040 BATT_socBrick09_0  1023 "SNA"  ;
VAL_ 2630615040 BATT_socBrick10_0  1023 "SNA"  ;
VAL_ 2630615041 BATT_socBrick12_1  1023 "SNA"  ;
VAL_ 2630615041 BATT_socBrick11_1  1023 "SNA"  ;
VAL_ 2630615041 BATT_socBrick09_1  1023 "SNA"  ;
VAL_ 2630615041 BATT_socBrick10_1  1023 "SNA"  ;
VAL_ 2630615042 BATT_socBrick12_2  1023 "SNA"  ;
VAL_ 2630615042 BATT_socBrick11_2  1023 "SNA"  ;
VAL_ 2630615042 BATT_socBrick09_2  1023 "SNA"  ;
VAL_ 2630615042 BATT_socBrick10_2  1023 "SNA"  ;
VAL_ 2630615043 BATT_socBrick12_3  1023 "SNA"  ;
VAL_ 2630615043 BATT_socBrick11_3  1023 "SNA"  ;
VAL_ 2630615043 BATT_socBrick09_3  1023 "SNA"  ;
VAL_ 2630615043 BATT_socBrick10_3  1023 "SNA"  ;
VAL_ 2630615044 BATT_socBrick12_4  1023 "SNA"  ;
VAL_ 2630615044 BATT_socBrick11_4  1023 "SNA"  ;
VAL_ 2630615044 BATT_socBrick09_4  1023 "SNA"  ;
VAL_ 2630615044 BATT_socBrick10_4  1023 "SNA"  ;
VAL_ 2630615045 BATT_socBrick12_5  1023 "SNA"  ;
VAL_ 2630615045 BATT_socBrick11_5  1023 "SNA"  ;
VAL_ 2630615045 BATT_socBrick09_5  1023 "SNA"  ;
VAL_ 2630615045 BATT_socBrick10_5  1023 "SNA"  ;
VAL_ 2630615046 BATT_socBrick12_6  1023 "SNA"  ;
VAL_ 2630615046 BATT_socBrick11_6  1023 "SNA"  ;
VAL_ 2630615046 BATT_socBrick09_6  1023 "SNA"  ;
VAL_ 2630615046 BATT_socBrick10_6  1023 "SNA"  ;
VAL_ 2630615047 BATT_socBrick12_7  1023 "SNA"  ;
VAL_ 2630615047 BATT_socBrick11_7  1023 "SNA"  ;
VAL_ 2630615047 BATT_socBrick09_7  1023 "SNA"  ;
VAL_ 2630615047 BATT_socBrick10_7  1023 "SNA"  ;
VAL_ 2630615048 BATT_socBrick12_8  1023 "SNA"  ;
VAL_ 2630615048 BATT_socBrick11_8  1023 "SNA"  ;
VAL_ 2630615048 BATT_socBrick09_8  1023 "SNA"  ;
VAL_ 2630615048 BATT_socBrick10_8  1023 "SNA"  ;
VAL_ 2630615049 BATT_socBrick12_9  1023 "SNA"  ;
VAL_ 2630615049 BATT_socBrick11_9  1023 "SNA"  ;
VAL_ 2630615049 BATT_socBrick09_9  1023 "SNA"  ;
VAL_ 2630615049 BATT_socBrick10_9  1023 "SNA"  ;
VAL_ 2630615050 BATT_socBrick12_10  1023 "SNA"  ;
VAL_ 2630615050 BATT_socBrick11_10  1023 "SNA"  ;
VAL_ 2630615050 BATT_socBrick09_10  1023 "SNA"  ;
VAL_ 2630615050 BATT_socBrick10_10  1023 "SNA"  ;
VAL_ 2630615051 BATT_socBrick12_11  1023 "SNA"  ;
VAL_ 2630615051 BATT_socBrick11_11  1023 "SNA"  ;
VAL_ 2630615051 BATT_socBrick09_11  1023 "SNA"  ;
VAL_ 2630615051 BATT_socBrick10_11  1023 "SNA"  ;
VAL_ 2630877184 BATT_socState_0  3 "Normal"  2 "OCV Correction"  1 "OCV Reset"  0 "Startup"  ;
VAL_ 2630877184 BATT_socBrick14_0  1023 "SNA"  ;
VAL_ 2630877184 BATT_socBrick13_0  1023 "SNA"  ;
VAL_ 2630877185 BATT_socState_1  3 "Normal"  2 "OCV Correction"  1 "OCV Reset"  0 "Startup"  ;
VAL_ 2630877185 BATT_socBrick14_1  1023 "SNA"  ;
VAL_ 2630877185 BATT_socBrick13_1  1023 "SNA"  ;
VAL_ 2630877186 BATT_socState_2  3 "Normal"  2 "OCV Correction"  1 "OCV Reset"  0 "Startup"  ;
VAL_ 2630877186 BATT_socBrick14_2  1023 "SNA"  ;
VAL_ 2630877186 BATT_socBrick13_2  1023 "SNA"  ;
VAL_ 2630877187 BATT_socState_3  3 "Normal"  2 "OCV Correction"  1 "OCV Reset"  0 "Startup"  ;
VAL_ 2630877187 BATT_socBrick14_3  1023 "SNA"  ;
VAL_ 2630877187 BATT_socBrick13_3  1023 "SNA"  ;
VAL_ 2630877188 BATT_socState_4  3 "Normal"  2 "OCV Correction"  1 "OCV Reset"  0 "Startup"  ;
VAL_ 2630877188 BATT_socBrick14_4  1023 "SNA"  ;
VAL_ 2630877188 BATT_socBrick13_4  1023 "SNA"  ;
VAL_ 2630877189 BATT_socState_5  3 "Normal"  2 "OCV Correction"  1 "OCV Reset"  0 "Startup"  ;
VAL_ 2630877189 BATT_socBrick14_5  1023 "SNA"  ;
VAL_ 2630877189 BATT_socBrick13_5  1023 "SNA"  ;
VAL_ 2630877190 BATT_socState_6  3 "Normal"  2 "OCV Correction"  1 "OCV Reset"  0 "Startup"  ;
VAL_ 2630877190 BATT_socBrick14_6  1023 "SNA"  ;
VAL_ 2630877190 BATT_socBrick13_6  1023 "SNA"  ;
VAL_ 2630877191 BATT_socState_7  3 "Normal"  2 "OCV Correction"  1 "OCV Reset"  0 "Startup"  ;
VAL_ 2630877191 BATT_socBrick14_7  1023 "SNA"  ;
VAL_ 2630877191 BATT_socBrick13_7  1023 "SNA"  ;
VAL_ 2630877192 BATT_socState_8  3 "Normal"  2 "OCV Correction"  1 "OCV Reset"  0 "Startup"  ;
VAL_ 2630877192 BATT_socBrick14_8  1023 "SNA"  ;
VAL_ 2630877192 BATT_socBrick13_8  1023 "SNA"  ;
VAL_ 2630877193 BATT_socState_9  3 "Normal"  2 "OCV Correction"  1 "OCV Reset"  0 "Startup"  ;
VAL_ 2630877193 BATT_socBrick14_9  1023 "SNA"  ;
VAL_ 2630877193 BATT_socBrick13_9  1023 "SNA"  ;
VAL_ 2630877194 BATT_socState_10  3 "Normal"  2 "OCV Correction"  1 "OCV Reset"  0 "Startup"  ;
VAL_ 2630877194 BATT_socBrick14_10  1023 "SNA"  ;
VAL_ 2630877194 BATT_socBrick13_10  1023 "SNA"  ;
VAL_ 2630877195 BATT_socState_11  3 "Normal"  2 "OCV Correction"  1 "OCV Reset"  0 "Startup"  ;
VAL_ 2630877195 BATT_socBrick14_11  1023 "SNA"  ;
VAL_ 2630877195 BATT_socBrick13_11  1023 "SNA"  ;
VAL_ 2643001344 BATT_deltaQError  5 "UnexpectedDisconnect"  4 "BadRequest"  3 "RequestTimeout"  2 "Charger"  1 "Comms"  0 "None"  ;
VAL_ 2643001344 BATT_deltaQEvent  8 "NMT Start TO"  7 "User Data TO"  6 "Heartbeat TO"  5 "RPDO Send Timer"  4 "Precharge Timer"  3 "Stop Request"  2 "Start Request"  1 "User Data Received"  0 "CAN Data Received"  ;
VAL_ 2643001344 BATT_deltaQState  5 "Error"  4 "Stopping"  3 "Charging"  2 "Connected"  1 "NMTStart"  0 "Disconnected"  ;
